VERSION ""

NS_ :

BS_:

BU_: ECM

BO_ 611 ORC_FD_1: 32 Vector__XXX
 SG_ MessageCounter_ORC1 : 179|4@0+ (1,0) [0|15] "-"  ECM
 SG_ CRC_ORC1 : 191|8@0+ (1,0) [0|255] "-"  ECM

BO_ 264 EPS_FD_1: 32 Vector__XXX
 SG_ LwsAngle : 7|16@0+ (0.1,-720) [-720|720] "°"  ECM

BO_ 518 ENGINE_FD_5: 32 ECM
 SG_ RPMOverRev_W : 115|1@0+ (1,0) [0|1] "-"  Vector__XXX
 SG_ PdlPosActual : 87|8@0+ (0.4,0) [0|100] "%"  Vector__XXX
 SG_ MessageCounter_ENGINE5 : 179|4@0+ (1,0) [0|15] "-"  Vector__XXX
 SG_ EngTrqEnblRq_DAS_W : 101|1@0+ (1,0) [0|1] "-"  Vector__XXX
 SG_ CRC_ENGINE5 : 191|8@0+ (1,0) [0|255] "-"  Vector__XXX

BO_ 1054 ENGINE_FD_1: 32 ECM
 SG_ ThermalManagementActive_W : 1|1@0+ (1,0) [0|1] "-"  Vector__XXX
 SG_ MessageCounter_ENGINE1 : 179|4@0+ (1,0) [0|15] "-"  Vector__XXX
 SG_ CRC_ENGINE1 : 191|8@0+ (1,0) [0|255] "-"  Vector__XXX

BO_ 514 BRAKE_FD_7: 32 Vector__XXX
 SG_ MessageCounter_BRAKE7 : 179|4@0+ (1,0) [0|15] "-"  ECM
 SG_ CRC_BRAKE7 : 191|8@0+ (1,0) [0|255] "-"  ECM
 SG_ BrkPdl_Stat : 85|2@0+ (1,0) [0|2] "-"  ECM
 SG_ BrkPdl_Flt : 86|1@0+ (1,0) [0|1] "-"  ECM
 SG_ BrakePdlPosn : 63|8@0+ (0.4,0) [0|100] "%"  ECM

BO_ 1155 BRAKE_FD_5: 32 Vector__XXX
 SG_ ACCEngaged : 92|1@0+ (1,0) [0|1] "-"  ECM
 SG_ ABSFailSts : 87|1@0+ (1,0) [0|1] "-"  ECM
 SG_ MessageCounter_BRAKE5 : 179|4@0+ (1,0) [0|15] "-"  ECM
 SG_ CRC_BRAKE5 : 191|8@0+ (1,0) [0|255] "-"  ECM

BO_ 513 BRAKE_FD_1: 32 Vector__XXX
 SG_ SelectSpdSts : 165|2@0+ (1,0) [0|2] "-"  ECM
 SG_ MessageCounter_BRAKE1 : 179|4@0+ (1,0) [0|15] "-"  ECM
 SG_ CRC_BRAKE1 : 191|8@0+ (1,0) [0|255] "-"  ECM

BO_ 255 PT_TORQUE_FD_1: 48 ECM
 SG_ SumTorqueStatic : 98|11@0+ (1,-500) [-500|1546] "Nm"  Vector__XXX
 SG_ SumTorqueSel_D_TTC : 82|11@0+ (1,-500) [-500|1546] "Nm"  Vector__XXX
 SG_ SumTorqueMin : 66|11@0+ (1,-500) [-500|1546] "Nm"  Vector__XXX
 SG_ SumTorqueMax : 50|11@0+ (1,-500) [-500|1546] "Nm"  Vector__XXX
 SG_ SumTorqueExp : 34|11@0+ (1,-500) [-500|1546] "Nm"  Vector__XXX
 SG_ SumTorque_DrvReqMod : 20|13@0+ (0.25,-500) [-500|1547.5] "Nm"  Vector__XXX
 SG_ MessageCounter_PT_TORQUE_FD_1 : 307|4@0+ (1,0) [0|15] "-"  Vector__XXX
 SG_ CRC_PT_TORQUE_FD_1 : 319|8@0+ (1,0) [0|255] "-"  Vector__XXX
 SG_ SSC_TrqEnblRq_Allowed : 22|1@0+ (1,0) [0|1] "-"  Vector__XXX
 SG_ ESC_TrqEnblRq_Allowed : 38|1@0+ (1,0) [0|1] "-"  Vector__XXX
 SG_ Accel_Pedal_Override : 37|1@0+ (1,0) [0|1] "-"  Vector__XXX
 SG_ ACC_NCC_TrqEnblRq_Allowed : 23|1@0+ (1,0) [0|1] "-"  Vector__XXX
 SG_ Total_AxleTorque_Static : 151|16@0+ (2,-65534) [-65534|65536] "Nm"  Vector__XXX
 SG_ Rear_AxleTorque_Static : 183|16@0+ (2,-65534) [-65534|65536] "Nm"  Vector__XXX
 SG_ Front_AxleTorque_Static : 167|16@0+ (2,-65534) [-65534|65536] "Nm"  Vector__XXX

BO_ 1036 ENGINE_FD_3: 32 ECM
 SG_ SpeedLimitSts : 159|3@0+ (1,0) [0|7] "-"  Vector__XXX
 SG_ Override : 163|1@0+ (1,0) [0|1] "-"  Vector__XXX
 SG_ MessageCounter_ENGINE3 : 179|4@0+ (1,0) [0|15] "-"  Vector__XXX
 SG_ ISASts : 167|1@0+ (1,0) [0|1] "-"  Vector__XXX
 SG_ CRC_ENGINE3 : 191|8@0+ (1,0) [0|255] "-"  Vector__XXX

BO_ 1456 ADAS_FD_HMI: 32 Vector__XXX
 SG_ MessageCounter_ADAS_FD_HMI : 179|4@0+ (1,0) [0|15] "-"  ECM
 SG_ CRC_ADAS_FD_HMI : 191|8@0+ (1,0) [0|255] "-"  ECM
 SG_ Set_Speed_MPH : 15|8@0+ (1,0) [0|255] "mph"  ECM
 SG_ Set_Speed_KPH : 7|8@0+ (1,0) [0|255] "kph"  ECM

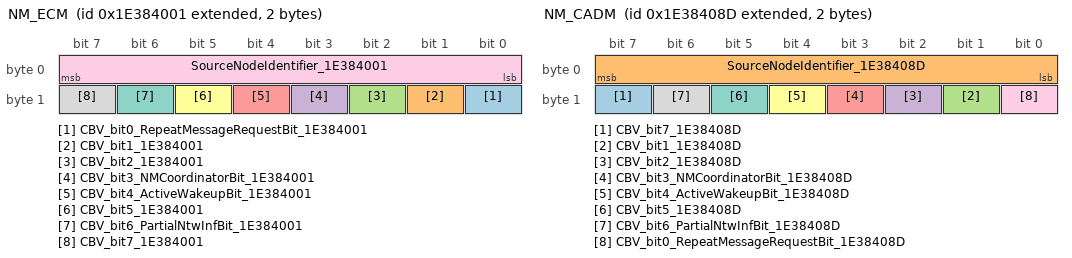
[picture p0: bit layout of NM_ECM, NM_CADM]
BO_ 2654486529 NM_ECM: 2 ECM
 SG_ CBV_bit0_RepeatMessageRequestBit_1E384001 : 8|1@0+ (1,0) [0|1] "" Vector__XXX
 SG_ CBV_bit1_1E384001 : 9|1@0+ (1,0) [0|1] "" Vector__XXX
 SG_ CBV_bit2_1E384001 : 10|1@0+ (1,0) [0|1] "" Vector__XXX
 SG_ CBV_bit3_NMCoordinatorBit_1E384001 : 11|1@0+ (1,0) [0|1] "" Vector__XXX
 SG_ CBV_bit4_ActiveWakeupBit_1E384001 : 12|1@0+ (1,0) [0|1] "" Vector__XXX
 SG_ CBV_bit5_1E384001 : 13|1@0+ (1,0) [0|1] "" Vector__XXX
 SG_ CBV_bit6_PartialNtwInfBit_1E384001 : 14|1@0+ (1,0) [0|1] "" Vector__XXX
 SG_ CBV_bit7_1E384001 : 15|1@0+ (1,0) [0|1] "" Vector__XXX
 SG_ SourceNodeIdentifier_1E384001 : 7|8@0+ (1,0) [0|255] "-"  Vector__XXX

BO_ 2654486669 NM_CADM: 2 Vector__XXX
 SG_ CBV_bit7_1E38408D : 15|1@0+ (1,0) [0|1] "" ECM
 SG_ SourceNodeIdentifier_1E38408D : 7|8@0+ (1,0) [0|255] "-"  ECM
 SG_ CBV_bit1_1E38408D : 9|1@0+ (1,0) [0|1] "" ECM
 SG_ CBV_bit2_1E38408D : 10|1@0+ (1,0) [0|1] "" ECM
 SG_ CBV_bit3_NMCoordinatorBit_1E38408D : 11|1@0+ (1,0) [0|1] "" ECM
 SG_ CBV_bit4_ActiveWakeupBit_1E38408D : 12|1@0+ (1,0) [0|1] "" ECM
 SG_ CBV_bit5_1E38408D : 13|1@0+ (1,0) [0|1] "" ECM
 SG_ CBV_bit6_PartialNtwInfBit_1E38408D : 14|1@0+ (1,0) [0|1] "" ECM
 SG_ CBV_bit0_RepeatMessageRequestBit_1E38408D : 8|1@0+ (1,0) [0|1] "" ECM

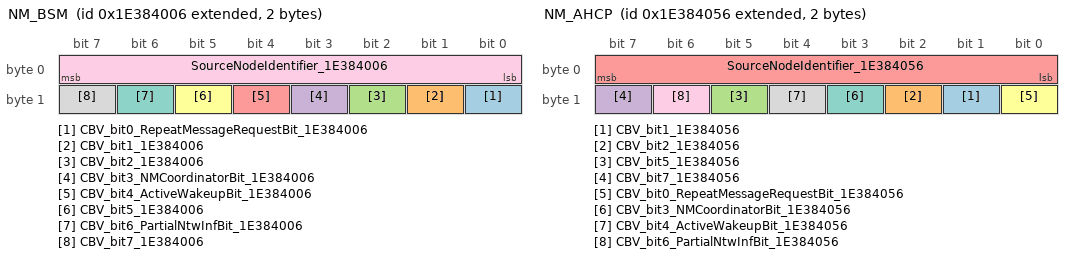
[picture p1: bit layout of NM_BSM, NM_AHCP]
BO_ 2654486534 NM_BSM: 2 Vector__XXX
 SG_ CBV_bit0_RepeatMessageRequestBit_1E384006 : 8|1@0+ (1,0) [0|1] "" ECM
 SG_ CBV_bit1_1E384006 : 9|1@0+ (1,0) [0|1] "" ECM
 SG_ CBV_bit2_1E384006 : 10|1@0+ (1,0) [0|1] "" ECM
 SG_ CBV_bit3_NMCoordinatorBit_1E384006 : 11|1@0+ (1,0) [0|1] "" ECM
 SG_ CBV_bit4_ActiveWakeupBit_1E384006 : 12|1@0+ (1,0) [0|1] "" ECM
 SG_ CBV_bit5_1E384006 : 13|1@0+ (1,0) [0|1] "" ECM
 SG_ CBV_bit6_PartialNtwInfBit_1E384006 : 14|1@0+ (1,0) [0|1] "" ECM
 SG_ CBV_bit7_1E384006 : 15|1@0+ (1,0) [0|1] "" ECM
 SG_ SourceNodeIdentifier_1E384006 : 7|8@0+ (1,0) [0|255] "-"  ECM

BO_ 276 HYBRID_POWERTRAIN1: 64 Vector__XXX
 SG_ PropulsionSystemActive : 408|1@0+ (1,0) [0|1] "-"  ECM

BO_ 262 ENGINE_FD_2: 64 ECM
 SG_ PowertrainPrplsnActv : 181|1@0+ (1,0) [0|1] "" Vector__XXX
 SG_ MessageCounter_ENGINE2 : 435|4@0+ (1,0) [0|15] "-"  Vector__XXX
 SG_ LV12PwrFreeRq_W : 176|1@0+ (1,0) [0|1] "-"  Vector__XXX
 SG_ GasPedalPositionFailSts_W : 169|1@0+ (1,0) [0|1] "-"  Vector__XXX
 SG_ GasPedalPosition_W : 143|8@0+ (0.392,0) [0|99.568] "%"  Vector__XXX
 SG_ FeedbackASR_ESCReq_W : 186|1@0+ (1,0) [0|1] "-"  Vector__XXX
 SG_ ESS_ENG_ST_W : 175|4@0+ (1,0) [0|15] "-"  Vector__XXX
 SG_ EngineSts_W : 87|2@0+ (1,0) [0|3] "-"  Vector__XXX
 SG_ EngineSpeed_W : 21|14@0+ (1,0) [0|16382] "1/min"  Vector__XXX
 SG_ ECM_LHOM_W : 188|1@0+ (1,0) [0|1] "-"  Vector__XXX
 SG_ CRC_ENGINE2 : 447|8@0+ (1,0) [0|255] "-"  Vector__XXX

BO_ 258 BRAKE_FD_2: 64 Vector__XXX
 SG_ TorqueRequest : 98|11@0+ (1,-500) [-500|1546] "-"  ECM
 SG_ TorqueReduct : 158|1@0+ (1,0) [0|1] "-"  ECM
 SG_ TorqueIncrease : 175|1@0+ (1,0) [0|1] "-"  ECM
 SG_ MessageCounter_BRAKE2 : 435|4@0+ (1,0) [0|15] "-"  ECM
 SG_ CRC_BRAKE2 : 447|8@0+ (1,0) [0|255] "-"  ECM
 SG_ BrakePedalPressure : 386|11@0+ (0.1,0) [0|200] "bar"  ECM
 SG_ BrakeBoostPressure : 370|11@0+ (0.1,0) [0|200] "bar"  ECM
 SG_ ABSActive : 83|1@0+ (1,0) [0|1] "-"  ECM
 SG_ Brk_Stat : 343|2@0+ (1,0) [0|2] "-"  ECM
 SG_ ACC_Wheel_Torque_Enabled_BSM : 85|1@0+ (1,0) [0|1] "-"  ECM
 SG_ ACC_Wheel_Torque_BSM : 423|16@0+ (2,-36878) [-36878|94190] "-"  ECM

BO_ 2654486614 NM_AHCP: 2 Vector__XXX
 SG_ CBV_bit1_1E384056 : 9|1@0+ (1,0) [0|1] "" ECM
 SG_ CBV_bit2_1E384056 : 10|1@0+ (1,0) [0|1] "" ECM
 SG_ CBV_bit5_1E384056 : 13|1@0+ (1,0) [0|1] "" ECM
 SG_ CBV_bit7_1E384056 : 15|1@0+ (1,0) [0|1] "" ECM
 SG_ SourceNodeIdentifier_1E384056 : 7|8@0+ (1,0) [0|255] "-"  ECM
 SG_ CBV_bit0_RepeatMessageRequestBit_1E384056 : 8|1@0+ (1,0) [0|1] "" ECM
 SG_ CBV_bit3_NMCoordinatorBit_1E384056 : 11|1@0+ (1,0) [0|1] "" ECM
 SG_ CBV_bit4_ActiveWakeupBit_1E384056 : 12|1@0+ (1,0) [0|1] "" ECM
 SG_ CBV_bit6_PartialNtwInfBit_1E384056 : 14|1@0+ (1,0) [0|1] "" ECM

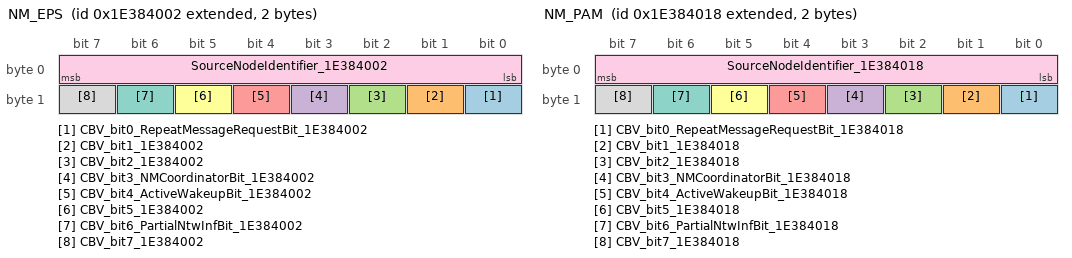
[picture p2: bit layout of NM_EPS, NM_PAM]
BO_ 2654486530 NM_EPS: 2 Vector__XXX
 SG_ CBV_bit0_RepeatMessageRequestBit_1E384002 : 8|1@0+ (1,0) [0|1] "" ECM
 SG_ CBV_bit1_1E384002 : 9|1@0+ (1,0) [0|1] "" ECM
 SG_ CBV_bit2_1E384002 : 10|1@0+ (1,0) [0|1] "" ECM
 SG_ CBV_bit3_NMCoordinatorBit_1E384002 : 11|1@0+ (1,0) [0|1] "" ECM
 SG_ CBV_bit4_ActiveWakeupBit_1E384002 : 12|1@0+ (1,0) [0|1] "" ECM
 SG_ CBV_bit5_1E384002 : 13|1@0+ (1,0) [0|1] "" ECM
 SG_ CBV_bit6_PartialNtwInfBit_1E384002 : 14|1@0+ (1,0) [0|1] "" ECM
 SG_ CBV_bit7_1E384002 : 15|1@0+ (1,0) [0|1] "" ECM
 SG_ SourceNodeIdentifier_1E384002 : 7|8@0+ (1,0) [0|255] "-"  ECM

BO_ 2654486552 NM_PAM: 2 Vector__XXX
 SG_ CBV_bit0_RepeatMessageRequestBit_1E384018 : 8|1@0+ (1,0) [0|1] "" ECM
 SG_ CBV_bit1_1E384018 : 9|1@0+ (1,0) [0|1] "" ECM
 SG_ CBV_bit2_1E384018 : 10|1@0+ (1,0) [0|1] "" ECM
 SG_ CBV_bit3_NMCoordinatorBit_1E384018 : 11|1@0+ (1,0) [0|1] "" ECM
 SG_ CBV_bit4_ActiveWakeupBit_1E384018 : 12|1@0+ (1,0) [0|1] "" ECM
 SG_ CBV_bit5_1E384018 : 13|1@0+ (1,0) [0|1] "" ECM
 SG_ CBV_bit6_PartialNtwInfBit_1E384018 : 14|1@0+ (1,0) [0|1] "" ECM
 SG_ CBV_bit7_1E384018 : 15|1@0+ (1,0) [0|1] "" ECM
 SG_ SourceNodeIdentifier_1E384018 : 7|8@0+ (1,0) [0|255] "-"  ECM

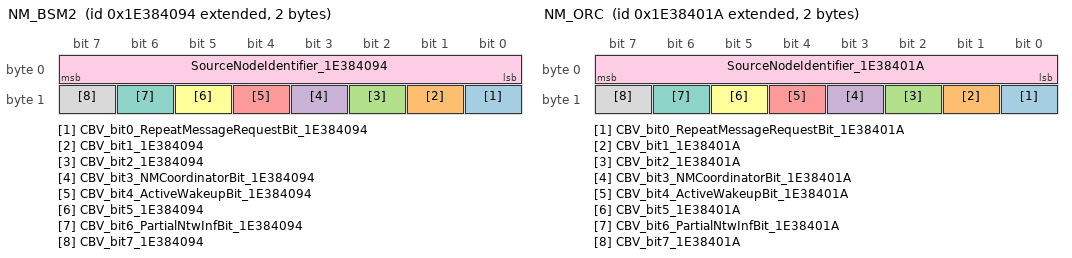
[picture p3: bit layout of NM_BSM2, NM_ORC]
BO_ 2654486676 NM_BSM2: 2 Vector__XXX
 SG_ CBV_bit0_RepeatMessageRequestBit_1E384094 : 8|1@0+ (1,0) [0|1] "" ECM
 SG_ CBV_bit1_1E384094 : 9|1@0+ (1,0) [0|1] "" ECM
 SG_ CBV_bit2_1E384094 : 10|1@0+ (1,0) [0|1] "" ECM
 SG_ CBV_bit3_NMCoordinatorBit_1E384094 : 11|1@0+ (1,0) [0|1] "" ECM
 SG_ CBV_bit4_ActiveWakeupBit_1E384094 : 12|1@0+ (1,0) [0|1] "" ECM
 SG_ CBV_bit5_1E384094 : 13|1@0+ (1,0) [0|1] "" ECM
 SG_ CBV_bit6_PartialNtwInfBit_1E384094 : 14|1@0+ (1,0) [0|1] "" ECM
 SG_ CBV_bit7_1E384094 : 15|1@0+ (1,0) [0|1] "" ECM
 SG_ SourceNodeIdentifier_1E384094 : 7|8@0+ (1,0) [0|255] "-"  ECM

BO_ 280 ADAS_FD_INFO: 32 Vector__XXX
 SG_ Object_Dist : 127|8@0+ (1,0) [0|255] "m"  ECM
 SG_ MessageCounter_ADAS_FD_INFO : 179|4@0+ (1,0) [0|15] "-"  ECM
 SG_ CRC_ADAS_FD_INFO : 191|8@0+ (1,0) [0|255] "-"  ECM
 SG_ ACC_DsrSpeedKPH : 119|8@0+ (1,0) [0|255] "km/h"  ECM
 SG_ MRM_STATUS : 23|3@0+ (1,0) [0|6] "" ECM
 SG_ ACC_Systemsts : 183|4@0+ (1,0) [0|14] "-"  ECM
 SG_ ACC_StopStart : 97|2@0+ (1,0) [0|2] "-"  ECM

BO_ 2654486554 NM_ORC: 2 Vector__XXX
 SG_ CBV_bit0_RepeatMessageRequestBit_1E38401A : 8|1@0+ (1,0) [0|1] "" ECM
 SG_ CBV_bit1_1E38401A : 9|1@0+ (1,0) [0|1] "" ECM
 SG_ CBV_bit2_1E38401A : 10|1@0+ (1,0) [0|1] "" ECM
 SG_ CBV_bit3_NMCoordinatorBit_1E38401A : 11|1@0+ (1,0) [0|1] "" ECM
 SG_ CBV_bit4_ActiveWakeupBit_1E38401A : 12|1@0+ (1,0) [0|1] "" ECM
 SG_ CBV_bit5_1E38401A : 13|1@0+ (1,0) [0|1] "" ECM
 SG_ CBV_bit6_PartialNtwInfBit_1E38401A : 14|1@0+ (1,0) [0|1] "" ECM
 SG_ CBV_bit7_1E38401A : 15|1@0+ (1,0) [0|1] "" ECM
 SG_ SourceNodeIdentifier_1E38401A : 7|8@0+ (1,0) [0|255] "-"  ECM

BO_ 205 BRAKE_FD_6: 64 Vector__XXX
 SG_ CRC_BRAKE_FD_6 : 447|8@0+ (1,0) [0|255] "-"  ECM
 SG_ MessageCounter_BRAKE_FD_6 : 435|4@0+ (1,0) [0|15] "-"  ECM
 SG_ TotalAxle_Min_Rq_BSM : 50|1@0+ (1,0) [0|1] "" ECM
 SG_ TotalAxle_Max_Rq_BSM : 51|1@0+ (1,0) [0|1] "" ECM
 SG_ DriverReq_AxleTrq_Enabled_BSM : 175|4@0+ (1,0) [0|15] "" ECM
 SG_ TotalAxle_Rq_BSM : 95|16@0+ (2,-65534) [-65534|65536] "Nm"  ECM
 SG_ DriverRequested_AxleTrq_BSM : 159|16@0+ (2,-65534) [-65534|65536] "Nm"  ECM

BO_ 204 AXLE_TORQUE_FD_1: 48 ECM
 SG_ MessageCounter_AXLE_TORQUE_FD_1 : 307|4@0+ (1,0) [0|15] "-"  Vector__XXX
 SG_ CRC_AXLE_TORQUE_FD_1 : 319|8@0+ (1,0) [0|255] "-"  Vector__XXX
 SG_ Rear_Axle_Regen_Capacity : 197|14@0+ (2,0) [0|32764] "Nm"  Vector__XXX
 SG_ Rear_Axle_Est_Regen_Torq : 181|14@0+ (2,0) [0|32764] "Nm"  Vector__XXX
 SG_ Front_Axle_Regen_Capacity : 165|14@0+ (2,0) [0|32764] "Nm"  Vector__XXX
 SG_ Front_Axle_Est_Regen_Torq : 149|14@0+ (2,0) [0|32764] "Nm"  Vector__XXX
 SG_ Total_AxleTorque_Min : 23|16@0+ (2,-65534) [-65534|65536] "Nm"  Vector__XXX
 SG_ Total_AxleTorque_Max : 7|16@0+ (2,-65534) [-65534|65536] "Nm"  Vector__XXX
 SG_ Axle_TorqueStatic_D_TTC : 39|16@0+ (2,-65534) [-65534|65536] "Nm"  Vector__XXX
 SG_ Axle_Torque_DrvReqMod : 55|16@0+ (2,-65534) [-65534|65536] "Nm"  Vector__XXX
 SG_ Rear_AxleTorque_Min : 119|16@0+ (2,-65534) [-65534|65536] "Nm"  Vector__XXX
 SG_ Rear_AxleTorque_Max : 103|16@0+ (2,-65534) [-65534|65536] "Nm"  Vector__XXX
 SG_ Front_AxleTorque_Min : 87|16@0+ (2,-65534) [-65534|65536] "Nm"  Vector__XXX
 SG_ Front_AxleTorque_Max : 71|16@0+ (2,-65534) [-65534|65536] "Nm"  Vector__XXX

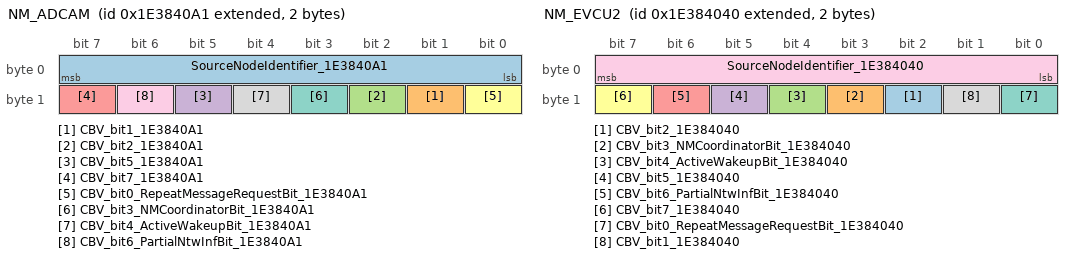
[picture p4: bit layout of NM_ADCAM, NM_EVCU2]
BO_ 2654486689 NM_ADCAM: 2 Vector__XXX
 SG_ SourceNodeIdentifier_1E3840A1 : 7|8@0+ (1,0) [0|255] "-"  ECM
 SG_ CBV_bit1_1E3840A1 : 9|1@0+ (1,0) [0|1] "" ECM
 SG_ CBV_bit2_1E3840A1 : 10|1@0+ (1,0) [0|1] "" ECM
 SG_ CBV_bit5_1E3840A1 : 13|1@0+ (1,0) [0|1] "" ECM
 SG_ CBV_bit7_1E3840A1 : 15|1@0+ (1,0) [0|1] "" ECM
 SG_ CBV_bit0_RepeatMessageRequestBit_1E3840A1 : 8|1@0+ (1,0) [0|1] "-"  ECM
 SG_ CBV_bit3_NMCoordinatorBit_1E3840A1 : 11|1@0+ (1,0) [0|1] "-"  ECM
 SG_ CBV_bit4_ActiveWakeupBit_1E3840A1 : 12|1@0+ (1,0) [0|1] "-"  ECM
 SG_ CBV_bit6_PartialNtwInfBit_1E3840A1 : 14|1@0+ (1,0) [0|1] "-"  ECM

BO_ 263 PT_SYSTEM_FD_1: 64 Vector__XXX
 SG_ MessageCounter_PT_SYSTEM_FD_1 : 435|4@0+ (1,0) [0|15] "-"  ECM
 SG_ CRC_PT_SYSTEM_FD_1 : 447|8@0+ (1,0) [0|255] "-"  ECM

BO_ 2654486592 NM_EVCU2: 2 Vector__XXX
 SG_ CBV_bit2_1E384040 : 10|1@0+ (1,0) [0|1] "" ECM
 SG_ CBV_bit3_NMCoordinatorBit_1E384040 : 11|1@0+ (1,0) [0|1] "" ECM
 SG_ CBV_bit4_ActiveWakeupBit_1E384040 : 12|1@0+ (1,0) [0|1] "" ECM
 SG_ CBV_bit5_1E384040 : 13|1@0+ (1,0) [0|1] "" ECM
 SG_ CBV_bit6_PartialNtwInfBit_1E384040 : 14|1@0+ (1,0) [0|1] "" ECM
 SG_ CBV_bit7_1E384040 : 15|1@0+ (1,0) [0|1] "" ECM
 SG_ CBV_bit0_RepeatMessageRequestBit_1E384040 : 8|1@0+ (1,0) [0|1] "" ECM
 SG_ CBV_bit1_1E384040 : 9|1@0+ (1,0) [0|1] "" ECM
 SG_ SourceNodeIdentifier_1E384040 : 7|8@0+ (1,0) [0|255] "-"  ECM

CM_ "Project_WL25_ProjectStandard_FD-CAN14 [CS00155_FD]";
CM_ SG_ 263 CRC_PT_SYSTEM_FD_1 "CRC according to SAE J1850 standard at each frame transmission.";
CM_ SG_ 263 MessageCounter_PT_SYSTEM_FD_1 "This signal is a counter used for safety checks strategies. This counter is incremented of 1 (one) unit at each frame transmission.";
CM_ SG_ 2654486689 CBV_bit0_RepeatMessageRequestBit_1E3840A1 "Repeat Message Request Bit";
CM_ SG_ 2654486689 CBV_bit3_NMCoordinatorBit_1E3840A1 "NM Coordinator Sleep Bit";
CM_ SG_ 2654486689 CBV_bit4_ActiveWakeupBit_1E3840A1 "Active Wakeup Bit";
CM_ SG_ 2654486689 CBV_bit6_PartialNtwInfBit_1E3840A1 "Partial Network Information Bit (PNI)";
CM_ SG_ 2654486689 SourceNodeIdentifier_1E3840A1 "Source Node Identifier";
CM_ SG_ 264 LwsAngle "This signal indicates the steering angle value, counterclockwise positive.";
CM_ SG_ 611 CRC_ORC1 "CRC according to SAE J1850 standard at each frame transmission.";
CM_ SG_ 611 MessageCounter_ORC1 "This signal is a counter used for safety checks strategies. This counter is incremented of 1 (one) unit at each frame transmission.";
CM_ SG_ 205 DriverRequested_AxleTrq_BSM "Virtual driver torque request from BSM";
CM_ SG_ 205 TotalAxle_Rq_BSM "Combined axle traction torque request";
CM_ SG_ 205 DriverReq_AxleTrq_Enabled_BSM "It indicates the request to enable virtual driver torque interface for BSM driver functions";
CM_ SG_ 205 TotalAxle_Max_Rq_BSM "Combined axle traction torque max limit flag. Active = [1]";
CM_ SG_ 205 TotalAxle_Min_Rq_BSM "Combined axle traction torque min limit flag. Active = [1]";
CM_ SG_ 205 MessageCounter_BRAKE_FD_6 "This signal is a counter used for safety checks strategies. This counter is incremented of 1 (one) unit at each frame transmission.";
CM_ SG_ 205 CRC_BRAKE_FD_6 "CRC according to SAE J1850 standard at each frame transmission.";
CM_ SG_ 2654486554 CBV_bit0_RepeatMessageRequestBit_1E38401A "Repeat Message Request Bit";
CM_ SG_ 2654486554 CBV_bit3_NMCoordinatorBit_1E38401A "NM Coordinator Sleep Bit";
CM_ SG_ 2654486554 CBV_bit4_ActiveWakeupBit_1E38401A "Active Wakeup Bit";
CM_ SG_ 2654486554 CBV_bit6_PartialNtwInfBit_1E38401A "Partial Network Information Bit (PNI)";
CM_ SG_ 2654486554 SourceNodeIdentifier_1E38401A "Source Node Identifier";
CM_ SG_ 280 Object_Dist "It indicates the distance to the recognized object";
CM_ SG_ 280 ACC_DsrSpeedKPH "Desired speed in kilometers per hour";
CM_ SG_ 280 ACC_StopStart "Allows StopStart when ACC is engaged";
CM_ SG_ 280 ACC_Systemsts "ACC System Status";
CM_ SG_ 280 MRM_STATUS "Status of the minimum risk maneuver to handle system faults or driver abuse as understood by primary controller";
CM_ SG_ 280 CRC_ADAS_FD_INFO "CRC according to SAE J1850 standard at each frame transmission.";
CM_ SG_ 280 MessageCounter_ADAS_FD_INFO "This signal is a counter used for safety checks strategies. This counter is incremented of 1 (one) unit at each frame transmission.";
CM_ SG_ 2654486676 CBV_bit0_RepeatMessageRequestBit_1E384094 "Repeat Message Request Bit";
CM_ SG_ 2654486676 CBV_bit3_NMCoordinatorBit_1E384094 "NM Coordinator Sleep Bit";
CM_ SG_ 2654486676 CBV_bit4_ActiveWakeupBit_1E384094 "Active Wakeup Bit";
CM_ SG_ 2654486676 CBV_bit6_PartialNtwInfBit_1E384094 "Partial Network Information Bit (PNI)";
CM_ SG_ 2654486676 SourceNodeIdentifier_1E384094 "Source Node Identifier";
CM_ SG_ 2654486552 CBV_bit0_RepeatMessageRequestBit_1E384018 "Repeat Message Request Bit";
CM_ SG_ 2654486552 CBV_bit3_NMCoordinatorBit_1E384018 "NM Coordinator Sleep Bit";
CM_ SG_ 2654486552 CBV_bit4_ActiveWakeupBit_1E384018 "Active Wakeup Bit";
CM_ SG_ 2654486552 CBV_bit6_PartialNtwInfBit_1E384018 "Partial Network Information Bit (PNI)";
CM_ SG_ 2654486552 SourceNodeIdentifier_1E384018 "Source Node Identifier";
CM_ SG_ 2654486530 CBV_bit0_RepeatMessageRequestBit_1E384002 "Repeat Message Request Bit";
CM_ SG_ 2654486530 CBV_bit3_NMCoordinatorBit_1E384002 "NM Coordinator Sleep Bit";
CM_ SG_ 2654486530 CBV_bit4_ActiveWakeupBit_1E384002 "Active Wakeup Bit";
CM_ SG_ 2654486530 CBV_bit6_PartialNtwInfBit_1E384002 "Partial Network Information Bit (PNI)";
CM_ SG_ 2654486530 SourceNodeIdentifier_1E384002 "Source Node Identifier";
CM_ SG_ 2654486614 CBV_bit0_RepeatMessageRequestBit_1E384056 "Repeat Message Request Bit";
CM_ SG_ 2654486614 CBV_bit3_NMCoordinatorBit_1E384056 "NM Coordinator Sleep Bit";
CM_ SG_ 2654486614 CBV_bit4_ActiveWakeupBit_1E384056 "Active Wakeup Bit";
CM_ SG_ 2654486614 CBV_bit6_PartialNtwInfBit_1E384056 "Partial Network Information Bit (PNI)";
CM_ SG_ 2654486614 SourceNodeIdentifier_1E384056 "Source Node Identifier";
CM_ SG_ 258 BrakePedalPressure "Pressure Information from Brake Pedal Simulator Pressure Sensor";
CM_ SG_ 258 BrakeBoostPressure "Pressure Information from Brake Booster Pressure Sensor";
CM_ SG_ 258 ACC_Wheel_Torque_BSM "It indicates the requested wheel torque value of ACC function";
CM_ SG_ 258 ACC_Wheel_Torque_Enabled_BSM "It indicates the request to enable torque interface of ACC function";
CM_ SG_ 258 Brk_Stat "Brake state";
CM_ SG_ 258 ABSActive "This signal is set to Active when the ABS functionality is active.";
CM_ SG_ 258 CRC_BRAKE2 "CRC according to SAE J1850 standard at each frame transmission.";
CM_ SG_ 258 MessageCounter_BRAKE2 "This signal is a counter used for safety checks strategies. This counter is incremented of 1 (one) unit at each frame transmission.";
CM_ SG_ 258 TorqueIncrease "0";
CM_ SG_ 258 TorqueReduct "0";
CM_ SG_ 258 TorqueRequest "[NOTE FOR MASERATI PROGRAMS ONLY] ICE & MHEV BSG: signal is referred to flywheel torque - Unit: Nm; MHEV P1R & BEV: signal is referred to wheel torque - Unit: daNm";
CM_ SG_ 276 PropulsionSystemActive "Propulsion system active, [1] = active";
CM_ SG_ 2654486534 CBV_bit0_RepeatMessageRequestBit_1E384006 "Repeat Message Request Bit";
CM_ SG_ 2654486534 CBV_bit3_NMCoordinatorBit_1E384006 "NM Coordinator Sleep Bit";
CM_ SG_ 2654486534 CBV_bit4_ActiveWakeupBit_1E384006 "Active Wakeup Bit";
CM_ SG_ 2654486534 CBV_bit6_PartialNtwInfBit_1E384006 "Partial Network Information Bit (PNI)";
CM_ SG_ 2654486534 SourceNodeIdentifier_1E384006 "Source Node Identifier";
CM_ SG_ 2654486669 CBV_bit0_RepeatMessageRequestBit_1E38408D "Repeat Message Request Bit";
CM_ SG_ 2654486669 CBV_bit3_NMCoordinatorBit_1E38408D "NM Coordinator Sleep Bit";
CM_ SG_ 2654486669 CBV_bit4_ActiveWakeupBit_1E38408D "Active Wakeup Bit";
CM_ SG_ 2654486669 CBV_bit6_PartialNtwInfBit_1E38408D "Partial Network Information Bit (PNI)";
CM_ SG_ 2654486669 SourceNodeIdentifier_1E38408D "Source Node Identifier";
CM_ SG_ 1456 Set_Speed_KPH "Speed shown by IPC, which ACC is controlling in KPH";
CM_ SG_ 1456 Set_Speed_MPH "Speed shown by IPC, which ACC is controlling in MPH";
CM_ SG_ 1456 CRC_ADAS_FD_HMI "CRC according to SAE J1850 standard at each frame transmission.";
CM_ SG_ 1456 MessageCounter_ADAS_FD_HMI "This signal is a counter used for safety checks strategies. This counter is incremented of 1 (one) unit at each frame transmission.";
CM_ SG_ 513 CRC_BRAKE1 "CRC according to SAE J1850 standard at each frame transmission.";
CM_ SG_ 513 MessageCounter_BRAKE1 "This signal is a counter used for safety checks strategies. This counter is incremented of 1 (one) unit at each frame transmission.";
CM_ SG_ 513 SelectSpdSts "0";
CM_ SG_ 1155 CRC_BRAKE5 "CRC according to SAE J1850 standard at each frame transmission.";
CM_ SG_ 1155 MessageCounter_BRAKE5 "This signal is a counter used for safety checks strategies. This counter is incremented of 1 (one) unit at each frame transmission.";
CM_ SG_ 1155 ABSFailSts "0";
CM_ SG_ 1155 ACCEngaged "ACC is engaged";
CM_ SG_ 514 CRC_BRAKE7 "CRC according to SAE J1850 standard at each frame transmission.";
CM_ SG_ 514 MessageCounter_BRAKE7 "This signal is a counter used for safety checks strategies. This counter is incremented of 1 (one) unit at each frame transmission.";
CM_ SG_ 514 BrkPdl_Flt "Brake Pedal Fault is active, 1=Faulted";
CM_ SG_ 514 BrakePdlPosn "Brake pedal travel sensor 0-100% (0 = upstop)";
CM_ SG_ 514 BrkPdl_Stat "Brake pedal state";
CM_ SG_ 204 Rear_Axle_Regen_Capacity "Regenerative Braking rear Axle Torque Capability";
CM_ SG_ 204 Rear_Axle_Est_Regen_Torq "Estimated regen Braking Torque at the Rear axle";
CM_ SG_ 204 Front_Axle_Regen_Capacity "Regenerative Braking front Axle Torque Capability";
CM_ SG_ 204 Front_Axle_Est_Regen_Torq "Estimated regen Braking Torque at the Front axle";
CM_ SG_ 204 Rear_AxleTorque_Min "Minimum rear Axle torque";
CM_ SG_ 204 Rear_AxleTorque_Max "Maximum rear Axle torque";
CM_ SG_ 204 Front_AxleTorque_Min "Minimum front Axle torque";
CM_ SG_ 204 Front_AxleTorque_Max "Maximum front Axle torque";
CM_ SG_ 204 Axle_Torque_DrvReqMod "Driver requested Axle torque raw (no torque shaping)";
CM_ SG_ 204 Axle_TorqueStatic_D_TTC "Driver requested Axle torque (filtered/ torque shaped)";
CM_ SG_ 204 Total_AxleTorque_Max "Maximum total Axle torque";
CM_ SG_ 204 Total_AxleTorque_Min "Minimum total Axle torque";
CM_ SG_ 204 CRC_AXLE_TORQUE_FD_1 "CRC according to SAE J1850 standard at each frame transmission.";
CM_ SG_ 204 MessageCounter_AXLE_TORQUE_FD_1 "This signal is a counter used for safety checks strategies. This counter is incremented of 1 (one) unit at each frame transmission.";
CM_ SG_ 262 CRC_ENGINE2 "CRC according to SAE J1850 standard at each frame transmission.";
CM_ SG_ 262 ECM_LHOM_W "-";
CM_ SG_ 262 EngineSpeed_W "It gives information on C-CAN network about  engine speed";
CM_ SG_ 262 EngineSts_W "-";
CM_ SG_ 262 ESS_ENG_ST_W "ESS Engine State";
CM_ SG_ 262 FeedbackASR_ESCReq_W "It is set to Not Valid, when the plausibility conditions about ASR / ESC torque request are not fulfilled . Nevertheless, it shall not be set to Not Valid, due to ValidData bits Not Valid transmitted from BSM.";
CM_ SG_ 262 GasPedalPosition_W "-";
CM_ SG_ 262 GasPedalPositionFailSts_W "-";
CM_ SG_ 262 LV12PwrFreeRq_W "-";
CM_ SG_ 262 MessageCounter_ENGINE2 "This signal is a counter used for safety checks strategies. This counter is incremented of 1 (one) unit at each frame transmission.";
CM_ SG_ 262 PowertrainPrplsnActv "Powertrain Propulsion Status.";
CM_ SG_ 2654486529 CBV_bit0_RepeatMessageRequestBit_1E384001 "Repeat Message Request Bit";
CM_ SG_ 2654486529 CBV_bit3_NMCoordinatorBit_1E384001 "NM Coordinator Sleep Bit";
CM_ SG_ 2654486529 CBV_bit4_ActiveWakeupBit_1E384001 "Active Wakeup Bit";
CM_ SG_ 2654486529 CBV_bit6_PartialNtwInfBit_1E384001 "Partial Network Information Bit (PNI)";
CM_ SG_ 2654486529 SourceNodeIdentifier_1E384001 "Source Node Identifier";
CM_ SG_ 1036 CRC_ENGINE3 "CRC according to SAE J1850 standard at each frame transmission.";
CM_ SG_ 1036 ISASts "This signal will be used to indicate when the Intelligent Speed Assist is Active";
CM_ SG_ 1036 MessageCounter_ENGINE3 "This signal is a counter used for safety checks strategies. This counter is incremented of 1 (one) unit at each frame transmission.";
CM_ SG_ 1036 Override "-";
CM_ SG_ 1036 SpeedLimitSts "It represents on C-CAN the actual status of speed limiter control function.";
CM_ SG_ 255 Rear_AxleTorque_Static "Static Rear Axle Torque";
CM_ SG_ 255 Front_AxleTorque_Static "Static Front Axle Torqu";
CM_ SG_ 255 ACC_NCC_TrqEnblRq_Allowed "ACC/NCC Torque request allowed. True =[1]";
CM_ SG_ 255 Accel_Pedal_Override "Driver Accelerator Pedal Override. True =[1]";
CM_ SG_ 255 ESC_TrqEnblRq_Allowed "ESC Torque request allowed. True =[1]";
CM_ SG_ 255 SSC_TrqEnblRq_Allowed "SCC Torque request allowed. True =[1]";
CM_ SG_ 255 CRC_PT_TORQUE_FD_1 "CRC according to SAE J1850 standard at each frame transmission.";
CM_ SG_ 255 MessageCounter_PT_TORQUE_FD_1 "This signal is a counter used for safety checks strategies. This counter is incremented of 1 (one) unit at each frame transmission.";
CM_ SG_ 255 Total_AxleTorque_Static "Static Axle Torque (effective total Axle torque)";
CM_ SG_ 255 SumTorque_DrvReqMod "Driver requested sum torque modified";
CM_ SG_ 255 SumTorqueExp "Expected sum torque based on target transmission input speed";
CM_ SG_ 255 SumTorqueMax "Maximum sum torque";
CM_ SG_ 255 SumTorqueMin "Minimum sum torque";
CM_ SG_ 255 SumTorqueSel_D_TTC "Corrected (substitute) driver torque demand";
CM_ SG_ 255 SumTorqueStatic "Static sum torque (effective sum torque)";
CM_ SG_ 1054 CRC_ENGINE1 "CRC according to SAE J1850 standard at each frame transmission.";
CM_ SG_ 1054 MessageCounter_ENGINE1 "This signal is a counter used for safety checks strategies. This counter is incremented of 1 (one) unit at each frame transmission.";
CM_ SG_ 1054 ThermalManagementActive_W "-";
CM_ SG_ 518 CRC_ENGINE5 "CRC according to SAE J1850 standard at each frame transmission.";
CM_ SG_ 518 EngTrqEnblRq_DAS_W "-";
CM_ SG_ 518 MessageCounter_ENGINE5 "This signal is a counter used for safety checks strategies. This counter is incremented of 1 (one) unit at each frame transmission.";
CM_ SG_ 518 PdlPosActual "Actual pedal position.";
CM_ SG_ 518 RPMOverRev_W "-";
BA_DEF_ SG_ "GenSigTimeoutTime_ADCAM" INT 0 65535;
BA_DEF_ SG_ "GenSigTimeoutTime_CVADAS" INT 0 65535;
BA_DEF_ SG_ "GenSigTimeoutTime_EVCU2" INT 0 65535;
BA_DEF_ SG_ "GenSigTimeoutTime_VDCM" INT 0 65535;
BA_DEF_ SG_ "GenSigStartValue" INT 0 2147483647;
BA_DEF_ SG_ "GenSigInactiveValue" INT 0 2147483647;
BA_DEF_ SG_ "GenSigSendType" ENUM "NotUsed","OnWrite","OnWriteWithRepetition","OnChange","OnChangeWithRepetition","IfActive","IfActiveWithRepetition","NoSigSendType";
BA_DEF_ SG_ "GenSigTimeoutTime_AHCP" INT 0 65535;
BA_DEF_ SG_ "GenSigTimeoutTime_BSM" INT 0 65535;
BA_DEF_ SG_ "GenSigTimeoutTime_BSM2" INT 0 65535;
BA_DEF_ SG_ "GenSigTimeoutTime_CADM" INT 0 65535;
BA_DEF_ SG_ "GenSigTimeoutTime_CVPAM" INT 0 65535;
BA_DEF_ SG_ "GenSigTimeoutTime_ECM" INT 0 65535;
BA_DEF_ SG_ "GenSigTimeoutTime_EPS" INT 0 65535;
BA_DEF_ SG_ "GenSigTimeoutTime_ORC" INT 0 65535;
BA_DEF_ BO_ "DiagRequest" ENUM "No","Yes";
BA_DEF_ BO_ "Type" ENUM "P","C","PE","COC","PE_Cntrl","E","E_Cntrl","OC","S","BAF","DC","EM","MM","ISO-TP","-";
BA_DEF_ BO_ "DiagResponse" ENUM "No","Yes";
BA_DEF_ BO_ "NmMessage" ENUM "No","Yes";
BA_DEF_ BO_ "GenMsgSendType" ENUM "Cyclic","NotUsed","NotUsed","NotUsed","NotUsed","NotUsed","NotUsed","NotUsed","NoMsgSendType";
BA_DEF_ BO_ "GenMsgNrOfRepetition" INT 0 255;
BA_DEF_ BO_ "GenMsgILSupport" ENUM "No","Yes";
BA_DEF_ BO_ "GenMsgCycleTimeFast" INT 0 65535;
BA_DEF_ BO_ "GenMsgCycleTime" INT 0 65535;
BA_DEF_ BO_ "GenMsgDelayTime" INT 0 65535;
BA_DEF_ BO_ "NmAsrMessage" ENUM "No","Yes";
BA_DEF_ BO_ "DiagState" ENUM "No","Yes";
BA_DEF_ BO_ "DiagConnection" HEX 0 65535;
BA_DEF_ BO_ "VFrameFormat" ENUM "StandardCAN","ExtendedCAN","reserved","reserved","reserved","reserved","reserved","reserved","reserved","reserved","reserved","reserved","reserved","reserved","StandardCAN_FD","ExtendedCAN_FD";
BA_DEF_ BO_ "CANFD_BRS" ENUM "0","1";
BA_DEF_ "Manufacturer" ENUM "DBAG","VAG","BWVAG","PAG","GM";
BA_DEF_ "NmType" STRING ;
BA_DEF_ "BusType" STRING ;
BA_DEF_ "Baudrate" INT 0 1000000;
BA_DEF_ "DBName" STRING ;
BA_DEF_ "NmAsrTimeoutTime" INT 1 65535;
BA_DEF_ "NmAsrWaitBusSleepTime" INT 1 65535;
BA_DEF_ "NmAsrRepeatMessageTime" INT 1 65535;
BA_DEF_ "NmAsrMessageCount" INT 1 256;
BA_DEF_ "NmAsrBaseAddress" HEX 235487232 2147483647;
BA_DEF_ "NmAsrCanMsgCycleTime" INT 1 65535;
BA_DEF_ "Version" HEX 0 255;
BA_DEF_ "VersionWeek" INT 0 53;
BA_DEF_ "VersionYear" INT 0 99;
BA_DEF_ BU_ "Description" STRING ;
BA_DEF_ BU_ "NmStationAddress" HEX 0 255;
BA_DEF_ BU_ "NmNode" ENUM "No","Yes";
BA_DEF_ BU_ "NmAsrNode" ENUM "No","Yes";
BA_DEF_ BU_ "NmAsrNodeIdentifier" HEX 0 255;
BA_DEF_ BU_ "NmAsrCanMsgReducedTime" INT 1 65535;
BA_DEF_ BU_ "NmNodeType" ENUM "+15_NotWakeable","+30_Wakeable","+30_NotWakeable","kMaster","kSlave15","kSlave30","none";
BA_DEF_ BU_ "NwmNodeType" ENUM "+15_NotWakeable","+30_Wakeable","+30_NotWakeable","kMaster","kSlave15","kSlave30","none";
BA_DEF_DEF_ "GenSigTimeoutTime_ADCAM" 2500;
BA_DEF_DEF_ "GenSigTimeoutTime_CVADAS" 2500;
BA_DEF_DEF_ "GenSigTimeoutTime_EVCU2" 2500;
BA_DEF_DEF_ "GenSigTimeoutTime_VDCM" 2500;
BA_DEF_DEF_ "GenSigStartValue" 0;
BA_DEF_DEF_ "GenSigInactiveValue" 0;
BA_DEF_DEF_ "GenSigSendType" "NoSigSendType";
BA_DEF_DEF_ "GenSigTimeoutTime_AHCP" 2500;
BA_DEF_DEF_ "GenSigTimeoutTime_BSM" 2500;
BA_DEF_DEF_ "GenSigTimeoutTime_BSM2" 2500;
BA_DEF_DEF_ "GenSigTimeoutTime_CADM" 2500;
BA_DEF_DEF_ "GenSigTimeoutTime_CVPAM" 2500;
BA_DEF_DEF_ "GenSigTimeoutTime_ECM" 2500;
BA_DEF_DEF_ "GenSigTimeoutTime_EPS" 2500;
BA_DEF_DEF_ "GenSigTimeoutTime_ORC" 2500;
BA_DEF_DEF_ "DiagRequest" "No";
BA_DEF_DEF_ "Type" "-";
BA_DEF_DEF_ "DiagResponse" "No";
BA_DEF_DEF_ "NmMessage" "No";
BA_DEF_DEF_ "GenMsgSendType" "NoMsgSendType";
BA_DEF_DEF_ "GenMsgNrOfRepetition" 0;
BA_DEF_DEF_ "GenMsgILSupport" "No";
BA_DEF_DEF_ "GenMsgCycleTimeFast" 0;
BA_DEF_DEF_ "GenMsgCycleTime" 0;
BA_DEF_DEF_ "GenMsgDelayTime" 0;
BA_DEF_DEF_ "NmAsrMessage" "No";
BA_DEF_DEF_ "DiagState" "No";
BA_DEF_DEF_ "DiagConnection" 0;
BA_DEF_DEF_ "VFrameFormat" "StandardCAN_FD";
BA_DEF_DEF_ "CANFD_BRS" "0";
BA_DEF_DEF_ "Manufacturer" "DBAG";
BA_DEF_DEF_ "NmType" "";
BA_DEF_DEF_ "BusType" "CAN";
BA_DEF_DEF_ "Baudrate" 500000;
BA_DEF_DEF_ "DBName" "CAN";
BA_DEF_DEF_ "NmAsrTimeoutTime" 1000;
BA_DEF_DEF_ "NmAsrWaitBusSleepTime" 750;
BA_DEF_DEF_ "NmAsrRepeatMessageTime" 800;
BA_DEF_DEF_ "NmAsrMessageCount" 256;
BA_DEF_DEF_ "NmAsrBaseAddress" 506724352;
BA_DEF_DEF_ "NmAsrCanMsgCycleTime" 200;
BA_DEF_DEF_ "Version" 160;
BA_DEF_DEF_ "VersionWeek" 34;
BA_DEF_DEF_ "VersionYear" 25;
BA_DEF_DEF_ "Description" "";
BA_DEF_DEF_ "NmStationAddress" 0;
BA_DEF_DEF_ "NmNode" "Yes";
BA_DEF_DEF_ "NmAsrNode" "Yes";
BA_DEF_DEF_ "NmAsrNodeIdentifier" 0;
BA_DEF_DEF_ "NmAsrCanMsgReducedTime" 100;
BA_DEF_DEF_ "NmNodeType" "none";
BA_DEF_DEF_ "NwmNodeType" "none";
BA_ "NmType" "NmAsr";
BA_ "BusType" "CAN FD";
BA_ "DBName" "FDCAN14";
BA_ "NmAsrTimeoutTime" 8000;
BA_ "NmAsrWaitBusSleepTime" 1000;
BA_ "NmAsrRepeatMessageTime" 5000;
BA_ "NmAsrBaseAddress" 507002880;
BA_ "NmAsrCanMsgCycleTime" 1000;
BA_ "Description" BU_ ECM "Engine Control Module";
BA_ "NmStationAddress" BU_ ECM 1;
BA_ "NmAsrNodeIdentifier" BU_ ECM 1;
BA_ "NmAsrCanMsgReducedTime" BU_ ECM 575;
BA_ "NmNodeType" BU_ ECM 2;
BA_ "NwmNodeType" BU_ ECM 2;
BA_ "Type" BO_ 2654486592 8;
BA_ "NmMessage" BO_ 2654486592 1;
BA_ "NmAsrMessage" BO_ 2654486592 1;
BA_ "VFrameFormat" BO_ 2654486592 15;
BA_ "CANFD_BRS" BO_ 2654486592 1;
BA_ "Type" BO_ 263 1;
BA_ "GenMsgSendType" BO_ 263 0;
BA_ "GenMsgILSupport" BO_ 263 1;
BA_ "GenMsgCycleTime" BO_ 263 10;
BA_ "CANFD_BRS" BO_ 263 1;
BA_ "Type" BO_ 2654486689 8;
BA_ "NmMessage" BO_ 2654486689 1;
BA_ "NmAsrMessage" BO_ 2654486689 1;
BA_ "VFrameFormat" BO_ 2654486689 15;
BA_ "CANFD_BRS" BO_ 2654486689 1;
BA_ "Type" BO_ 264 1;
BA_ "GenMsgSendType" BO_ 264 0;
BA_ "GenMsgILSupport" BO_ 264 1;
BA_ "GenMsgCycleTime" BO_ 264 10;
BA_ "CANFD_BRS" BO_ 264 1;
BA_ "Type" BO_ 611 3;
BA_ "GenMsgSendType" BO_ 611 0;
BA_ "GenMsgILSupport" BO_ 611 1;
BA_ "GenMsgCycleTime" BO_ 611 100;
BA_ "GenMsgDelayTime" BO_ 611 20;
BA_ "CANFD_BRS" BO_ 611 1;
BA_ "Type" BO_ 205 1;
BA_ "GenMsgSendType" BO_ 205 0;
BA_ "GenMsgILSupport" BO_ 205 1;
BA_ "GenMsgCycleTime" BO_ 205 10;
BA_ "CANFD_BRS" BO_ 205 1;
BA_ "Type" BO_ 2654486554 8;
BA_ "NmMessage" BO_ 2654486554 1;
BA_ "NmAsrMessage" BO_ 2654486554 1;
BA_ "VFrameFormat" BO_ 2654486554 15;
BA_ "CANFD_BRS" BO_ 2654486554 1;
BA_ "Type" BO_ 280 1;
BA_ "GenMsgSendType" BO_ 280 0;
BA_ "GenMsgILSupport" BO_ 280 1;
BA_ "GenMsgCycleTime" BO_ 280 10;
BA_ "CANFD_BRS" BO_ 280 1;
BA_ "Type" BO_ 2654486676 8;
BA_ "NmMessage" BO_ 2654486676 1;
BA_ "NmAsrMessage" BO_ 2654486676 1;
BA_ "VFrameFormat" BO_ 2654486676 15;
BA_ "CANFD_BRS" BO_ 2654486676 1;
BA_ "Type" BO_ 2654486552 8;
BA_ "NmMessage" BO_ 2654486552 1;
BA_ "NmAsrMessage" BO_ 2654486552 1;
BA_ "VFrameFormat" BO_ 2654486552 15;
BA_ "CANFD_BRS" BO_ 2654486552 1;
BA_ "Type" BO_ 2654486530 8;
BA_ "NmMessage" BO_ 2654486530 1;
BA_ "NmAsrMessage" BO_ 2654486530 1;
BA_ "VFrameFormat" BO_ 2654486530 15;
BA_ "CANFD_BRS" BO_ 2654486530 1;
BA_ "Type" BO_ 2654486614 8;
BA_ "NmMessage" BO_ 2654486614 1;
BA_ "NmAsrMessage" BO_ 2654486614 1;
BA_ "VFrameFormat" BO_ 2654486614 15;
BA_ "CANFD_BRS" BO_ 2654486614 1;
BA_ "Type" BO_ 258 1;
BA_ "GenMsgSendType" BO_ 258 0;
BA_ "GenMsgILSupport" BO_ 258 1;
BA_ "GenMsgCycleTime" BO_ 258 10;
BA_ "CANFD_BRS" BO_ 258 1;
BA_ "Type" BO_ 276 1;
BA_ "GenMsgSendType" BO_ 276 0;
BA_ "GenMsgILSupport" BO_ 276 1;
BA_ "GenMsgCycleTime" BO_ 276 10;
BA_ "CANFD_BRS" BO_ 276 1;
BA_ "Type" BO_ 2654486534 8;
BA_ "NmMessage" BO_ 2654486534 1;
BA_ "NmAsrMessage" BO_ 2654486534 1;
BA_ "VFrameFormat" BO_ 2654486534 15;
BA_ "CANFD_BRS" BO_ 2654486534 1;
BA_ "Type" BO_ 2654486669 8;
BA_ "NmMessage" BO_ 2654486669 1;
BA_ "NmAsrMessage" BO_ 2654486669 1;
BA_ "VFrameFormat" BO_ 2654486669 15;
BA_ "CANFD_BRS" BO_ 2654486669 1;
BA_ "Type" BO_ 1456 3;
BA_ "GenMsgSendType" BO_ 1456 0;
BA_ "GenMsgILSupport" BO_ 1456 1;
BA_ "GenMsgCycleTime" BO_ 1456 100;
BA_ "GenMsgDelayTime" BO_ 1456 20;
BA_ "CANFD_BRS" BO_ 1456 1;
BA_ "Type" BO_ 513 1;
BA_ "GenMsgSendType" BO_ 513 0;
BA_ "GenMsgILSupport" BO_ 513 1;
BA_ "GenMsgCycleTime" BO_ 513 20;
BA_ "CANFD_BRS" BO_ 513 1;
BA_ "Type" BO_ 1155 3;
BA_ "GenMsgSendType" BO_ 1155 0;
BA_ "GenMsgNrOfRepetition" BO_ 1155 2;
BA_ "GenMsgILSupport" BO_ 1155 1;
BA_ "GenMsgCycleTimeFast" BO_ 1155 20;
BA_ "GenMsgCycleTime" BO_ 1155 500;
BA_ "GenMsgDelayTime" BO_ 1155 20;
BA_ "CANFD_BRS" BO_ 1155 1;
BA_ "Type" BO_ 514 1;
BA_ "GenMsgSendType" BO_ 514 0;
BA_ "GenMsgILSupport" BO_ 514 1;
BA_ "GenMsgCycleTime" BO_ 514 20;
BA_ "CANFD_BRS" BO_ 514 1;
BA_ "Type" BO_ 204 1;
BA_ "GenMsgSendType" BO_ 204 0;
BA_ "GenMsgILSupport" BO_ 204 1;
BA_ "GenMsgCycleTime" BO_ 204 10;
BA_ "CANFD_BRS" BO_ 204 1;
BA_ "Type" BO_ 262 1;
BA_ "GenMsgSendType" BO_ 262 0;
BA_ "GenMsgILSupport" BO_ 262 1;
BA_ "GenMsgCycleTime" BO_ 262 10;
BA_ "CANFD_BRS" BO_ 262 1;
BA_ "Type" BO_ 2654486529 8;
BA_ "NmMessage" BO_ 2654486529 1;
BA_ "NmAsrMessage" BO_ 2654486529 1;
BA_ "VFrameFormat" BO_ 2654486529 15;
BA_ "CANFD_BRS" BO_ 2654486529 1;
BA_ "Type" BO_ 1036 3;
BA_ "GenMsgSendType" BO_ 1036 0;
BA_ "GenMsgNrOfRepetition" BO_ 1036 2;
BA_ "GenMsgILSupport" BO_ 1036 1;
BA_ "GenMsgCycleTimeFast" BO_ 1036 20;
BA_ "GenMsgCycleTime" BO_ 1036 100;
BA_ "GenMsgDelayTime" BO_ 1036 20;
BA_ "CANFD_BRS" BO_ 1036 1;
BA_ "Type" BO_ 255 1;
BA_ "GenMsgSendType" BO_ 255 0;
BA_ "GenMsgILSupport" BO_ 255 1;
BA_ "GenMsgCycleTime" BO_ 255 10;
BA_ "CANFD_BRS" BO_ 255 1;
BA_ "Type" BO_ 1054 1;
BA_ "GenMsgSendType" BO_ 1054 0;
BA_ "GenMsgILSupport" BO_ 1054 1;
BA_ "GenMsgCycleTime" BO_ 1054 100;
BA_ "CANFD_BRS" BO_ 1054 1;
BA_ "Type" BO_ 518 1;
BA_ "GenMsgSendType" BO_ 518 0;
BA_ "GenMsgILSupport" BO_ 518 1;
BA_ "GenMsgCycleTime" BO_ 518 20;
BA_ "CANFD_BRS" BO_ 518 1;
BA_ "GenSigTimeoutTime_BSM2" SG_ 1036 CRC_ENGINE3 0;
BA_ "GenSigTimeoutTime_CVPAM" SG_ 1036 CRC_ENGINE3 0;
BA_ "GenSigTimeoutTime_ECM" SG_ 1036 CRC_ENGINE3 0;
BA_ "GenSigTimeoutTime_EPS" SG_ 1036 CRC_ENGINE3 0;
BA_ "GenSigTimeoutTime_ORC" SG_ 1036 CRC_ENGINE3 0;
BA_ "GenSigSendType" SG_ 1036 ISASts 3;
BA_ "GenSigTimeoutTime_AHCP" SG_ 1036 ISASts 0;
BA_ "GenSigTimeoutTime_BSM" SG_ 1036 ISASts 0;
BA_ "GenSigTimeoutTime_BSM2" SG_ 1036 ISASts 0;
BA_ "GenSigTimeoutTime_CADM" SG_ 1036 ISASts 0;
BA_ "GenSigTimeoutTime_CVPAM" SG_ 1036 ISASts 0;
BA_ "GenSigTimeoutTime_ECM" SG_ 1036 ISASts 0;
BA_ "GenSigTimeoutTime_EPS" SG_ 1036 ISASts 0;
BA_ "GenSigTimeoutTime_ORC" SG_ 1036 ISASts 0;
BA_ "GenSigTimeoutTime_AHCP" SG_ 1036 MessageCounter_ENGINE3 0;
BA_ "GenSigTimeoutTime_BSM2" SG_ 1036 MessageCounter_ENGINE3 0;
BA_ "GenSigTimeoutTime_CVPAM" SG_ 1036 MessageCounter_ENGINE3 0;
BA_ "GenSigTimeoutTime_ECM" SG_ 1036 MessageCounter_ENGINE3 0;
BA_ "GenSigTimeoutTime_EPS" SG_ 1036 MessageCounter_ENGINE3 0;
BA_ "GenSigTimeoutTime_ORC" SG_ 1036 MessageCounter_ENGINE3 0;
BA_ "GenSigSendType" SG_ 1036 Override 3;
BA_ "GenSigTimeoutTime_AHCP" SG_ 1036 Override 0;
BA_ "GenSigTimeoutTime_BSM2" SG_ 1036 Override 0;
BA_ "GenSigTimeoutTime_CVPAM" SG_ 1036 Override 0;
BA_ "GenSigTimeoutTime_ECM" SG_ 1036 Override 0;
BA_ "GenSigTimeoutTime_EPS" SG_ 1036 Override 0;
BA_ "GenSigTimeoutTime_ORC" SG_ 1036 Override 0;
BA_ "GenSigStartValue" SG_ 1036 SpeedLimitSts 2;
BA_ "GenSigSendType" SG_ 1036 SpeedLimitSts 3;
BA_ "GenSigTimeoutTime_AHCP" SG_ 1036 SpeedLimitSts 0;
BA_ "GenSigTimeoutTime_BSM" SG_ 1036 SpeedLimitSts 0;
BA_ "GenSigTimeoutTime_BSM2" SG_ 1036 SpeedLimitSts 0;
BA_ "GenSigTimeoutTime_CVPAM" SG_ 1036 SpeedLimitSts 0;
BA_ "GenSigTimeoutTime_ECM" SG_ 1036 SpeedLimitSts 0;
BA_ "GenSigTimeoutTime_EPS" SG_ 1036 SpeedLimitSts 0;
BA_ "GenSigTimeoutTime_ORC" SG_ 1036 SpeedLimitSts 0;
BA_ "GenSigTimeoutTime_ADCAM" SG_ 255 Rear_AxleTorque_Static 0;
BA_ "GenSigTimeoutTime_CVADAS" SG_ 255 Rear_AxleTorque_Static 0;
BA_ "GenSigTimeoutTime_EVCU2" SG_ 255 Rear_AxleTorque_Static 0;
BA_ "GenSigStartValue" SG_ 255 Rear_AxleTorque_Static 32767;
BA_ "GenSigTimeoutTime_BSM" SG_ 255 Rear_AxleTorque_Static 0;
BA_ "GenSigTimeoutTime_ECM" SG_ 255 Rear_AxleTorque_Static 0;
BA_ "GenSigTimeoutTime_EPS" SG_ 255 Rear_AxleTorque_Static 0;
BA_ "GenSigTimeoutTime_ORC" SG_ 255 Rear_AxleTorque_Static 0;
BA_ "GenSigTimeoutTime_ADCAM" SG_ 255 Front_AxleTorque_Static 0;
BA_ "GenSigTimeoutTime_CVADAS" SG_ 255 Front_AxleTorque_Static 0;
BA_ "GenSigTimeoutTime_EVCU2" SG_ 255 Front_AxleTorque_Static 0;
BA_ "GenSigStartValue" SG_ 255 Front_AxleTorque_Static 32767;
BA_ "GenSigTimeoutTime_BSM" SG_ 255 Front_AxleTorque_Static 0;
BA_ "GenSigTimeoutTime_ECM" SG_ 255 Front_AxleTorque_Static 0;
BA_ "GenSigTimeoutTime_ORC" SG_ 255 Front_AxleTorque_Static 0;
BA_ "GenSigTimeoutTime_CVADAS" SG_ 255 ACC_NCC_TrqEnblRq_Allowed 0;
BA_ "GenSigTimeoutTime_EVCU2" SG_ 255 ACC_NCC_TrqEnblRq_Allowed 0;
BA_ "GenSigTimeoutTime_VDCM" SG_ 255 ACC_NCC_TrqEnblRq_Allowed 0;
BA_ "GenSigTimeoutTime_CVADAS" SG_ 255 Accel_Pedal_Override 0;
BA_ "GenSigTimeoutTime_EVCU2" SG_ 255 Accel_Pedal_Override 0;
BA_ "GenSigTimeoutTime_VDCM" SG_ 255 Accel_Pedal_Override 0;
BA_ "GenSigTimeoutTime_ADCAM" SG_ 255 ESC_TrqEnblRq_Allowed 0;
BA_ "GenSigTimeoutTime_CVADAS" SG_ 255 ESC_TrqEnblRq_Allowed 0;
BA_ "GenSigTimeoutTime_EVCU2" SG_ 255 ESC_TrqEnblRq_Allowed 0;
BA_ "GenSigTimeoutTime_VDCM" SG_ 255 ESC_TrqEnblRq_Allowed 0;
BA_ "GenSigTimeoutTime_ADCAM" SG_ 255 SSC_TrqEnblRq_Allowed 0;
BA_ "GenSigTimeoutTime_CVADAS" SG_ 255 SSC_TrqEnblRq_Allowed 0;
BA_ "GenSigTimeoutTime_EVCU2" SG_ 255 SSC_TrqEnblRq_Allowed 0;
BA_ "GenSigTimeoutTime_VDCM" SG_ 255 SSC_TrqEnblRq_Allowed 0;
BA_ "GenSigTimeoutTime_CVADAS" SG_ 255 CRC_PT_TORQUE_FD_1 0;
BA_ "GenSigTimeoutTime_EVCU2" SG_ 255 CRC_PT_TORQUE_FD_1 0;
BA_ "GenSigTimeoutTime_VDCM" SG_ 255 CRC_PT_TORQUE_FD_1 0;
BA_ "GenSigTimeoutTime_CVADAS" SG_ 255 MessageCounter_PT_TORQUE_FD_1 0;
BA_ "GenSigTimeoutTime_EVCU2" SG_ 255 MessageCounter_PT_TORQUE_FD_1 0;
BA_ "GenSigTimeoutTime_VDCM" SG_ 255 MessageCounter_PT_TORQUE_FD_1 0;
BA_ "GenSigTimeoutTime_CVADAS" SG_ 255 Total_AxleTorque_Static 0;
BA_ "GenSigTimeoutTime_EVCU2" SG_ 255 Total_AxleTorque_Static 0;
BA_ "GenSigTimeoutTime_ADCAM" SG_ 255 SumTorque_DrvReqMod 0;
BA_ "GenSigTimeoutTime_CVADAS" SG_ 255 SumTorque_DrvReqMod 0;
BA_ "GenSigTimeoutTime_EVCU2" SG_ 255 SumTorque_DrvReqMod 0;
BA_ "GenSigTimeoutTime_VDCM" SG_ 255 SumTorque_DrvReqMod 0;
BA_ "GenSigTimeoutTime_ADCAM" SG_ 255 SumTorqueMax 0;
BA_ "GenSigTimeoutTime_CVADAS" SG_ 255 SumTorqueMax 0;
BA_ "GenSigTimeoutTime_EVCU2" SG_ 255 SumTorqueMax 0;
BA_ "GenSigTimeoutTime_VDCM" SG_ 255 SumTorqueMax 0;
BA_ "GenSigTimeoutTime_ADCAM" SG_ 255 SumTorqueMin 0;
BA_ "GenSigTimeoutTime_CVADAS" SG_ 255 SumTorqueMin 0;
BA_ "GenSigTimeoutTime_EVCU2" SG_ 255 SumTorqueMin 0;
BA_ "GenSigTimeoutTime_VDCM" SG_ 255 SumTorqueMin 0;
BA_ "GenSigTimeoutTime_ADCAM" SG_ 255 SumTorqueSel_D_TTC 0;
BA_ "GenSigTimeoutTime_CVADAS" SG_ 255 SumTorqueSel_D_TTC 0;
BA_ "GenSigTimeoutTime_EVCU2" SG_ 255 SumTorqueSel_D_TTC 0;
BA_ "GenSigTimeoutTime_VDCM" SG_ 255 SumTorqueSel_D_TTC 0;
BA_ "GenSigTimeoutTime_ADCAM" SG_ 255 SumTorqueStatic 0;
BA_ "GenSigTimeoutTime_CVADAS" SG_ 255 SumTorqueStatic 0;
BA_ "GenSigTimeoutTime_EVCU2" SG_ 255 SumTorqueStatic 0;
BA_ "GenSigTimeoutTime_VDCM" SG_ 255 SumTorqueStatic 0;
BA_ "GenSigTimeoutTime_AHCP" SG_ 255 ACC_NCC_TrqEnblRq_Allowed 0;
BA_ "GenSigTimeoutTime_BSM" SG_ 255 ACC_NCC_TrqEnblRq_Allowed 0;
BA_ "GenSigTimeoutTime_BSM2" SG_ 255 ACC_NCC_TrqEnblRq_Allowed 0;
BA_ "GenSigTimeoutTime_CVPAM" SG_ 255 ACC_NCC_TrqEnblRq_Allowed 0;
BA_ "GenSigTimeoutTime_ECM" SG_ 255 ACC_NCC_TrqEnblRq_Allowed 0;
BA_ "GenSigTimeoutTime_EPS" SG_ 255 ACC_NCC_TrqEnblRq_Allowed 0;
BA_ "GenSigTimeoutTime_ORC" SG_ 255 ACC_NCC_TrqEnblRq_Allowed 0;
BA_ "GenSigTimeoutTime_AHCP" SG_ 255 Accel_Pedal_Override 0;
BA_ "GenSigTimeoutTime_BSM2" SG_ 255 Accel_Pedal_Override 0;
BA_ "GenSigTimeoutTime_CVPAM" SG_ 255 Accel_Pedal_Override 0;
BA_ "GenSigTimeoutTime_ECM" SG_ 255 Accel_Pedal_Override 0;
BA_ "GenSigTimeoutTime_EPS" SG_ 255 Accel_Pedal_Override 0;
BA_ "GenSigTimeoutTime_ORC" SG_ 255 Accel_Pedal_Override 0;
BA_ "GenSigTimeoutTime_AHCP" SG_ 255 ESC_TrqEnblRq_Allowed 0;
BA_ "GenSigTimeoutTime_BSM" SG_ 255 ESC_TrqEnblRq_Allowed 0;
BA_ "GenSigTimeoutTime_BSM2" SG_ 255 ESC_TrqEnblRq_Allowed 0;
BA_ "GenSigTimeoutTime_CADM" SG_ 255 ESC_TrqEnblRq_Allowed 0;
BA_ "GenSigTimeoutTime_CVPAM" SG_ 255 ESC_TrqEnblRq_Allowed 0;
BA_ "GenSigTimeoutTime_ECM" SG_ 255 ESC_TrqEnblRq_Allowed 0;
BA_ "GenSigTimeoutTime_EPS" SG_ 255 ESC_TrqEnblRq_Allowed 0;
BA_ "GenSigTimeoutTime_ORC" SG_ 255 ESC_TrqEnblRq_Allowed 0;
BA_ "GenSigTimeoutTime_AHCP" SG_ 255 SSC_TrqEnblRq_Allowed 0;
BA_ "GenSigTimeoutTime_BSM" SG_ 255 SSC_TrqEnblRq_Allowed 0;
BA_ "GenSigTimeoutTime_BSM2" SG_ 255 SSC_TrqEnblRq_Allowed 0;
BA_ "GenSigTimeoutTime_CADM" SG_ 255 SSC_TrqEnblRq_Allowed 0;
BA_ "GenSigTimeoutTime_CVPAM" SG_ 255 SSC_TrqEnblRq_Allowed 0;
BA_ "GenSigTimeoutTime_ECM" SG_ 255 SSC_TrqEnblRq_Allowed 0;
BA_ "GenSigTimeoutTime_EPS" SG_ 255 SSC_TrqEnblRq_Allowed 0;
BA_ "GenSigTimeoutTime_ORC" SG_ 255 SSC_TrqEnblRq_Allowed 0;
BA_ "GenSigTimeoutTime_AHCP" SG_ 255 CRC_PT_TORQUE_FD_1 0;
BA_ "GenSigTimeoutTime_BSM" SG_ 255 CRC_PT_TORQUE_FD_1 0;
BA_ "GenSigTimeoutTime_BSM2" SG_ 255 CRC_PT_TORQUE_FD_1 0;
BA_ "GenSigTimeoutTime_CVPAM" SG_ 255 CRC_PT_TORQUE_FD_1 0;
BA_ "GenSigTimeoutTime_ECM" SG_ 255 CRC_PT_TORQUE_FD_1 0;
BA_ "GenSigTimeoutTime_EPS" SG_ 255 CRC_PT_TORQUE_FD_1 0;
BA_ "GenSigTimeoutTime_ORC" SG_ 255 CRC_PT_TORQUE_FD_1 0;
BA_ "GenSigTimeoutTime_AHCP" SG_ 255 MessageCounter_PT_TORQUE_FD_1 0;
BA_ "GenSigTimeoutTime_BSM" SG_ 255 MessageCounter_PT_TORQUE_FD_1 0;
BA_ "GenSigTimeoutTime_BSM2" SG_ 255 MessageCounter_PT_TORQUE_FD_1 0;
BA_ "GenSigTimeoutTime_CVPAM" SG_ 255 MessageCounter_PT_TORQUE_FD_1 0;
BA_ "GenSigTimeoutTime_ECM" SG_ 255 MessageCounter_PT_TORQUE_FD_1 0;
BA_ "GenSigTimeoutTime_EPS" SG_ 255 MessageCounter_PT_TORQUE_FD_1 0;
BA_ "GenSigTimeoutTime_ORC" SG_ 255 MessageCounter_PT_TORQUE_FD_1 0;
BA_ "GenSigStartValue" SG_ 255 Total_AxleTorque_Static 32767;
BA_ "GenSigTimeoutTime_AHCP" SG_ 255 Total_AxleTorque_Static 0;
BA_ "GenSigTimeoutTime_BSM" SG_ 255 Total_AxleTorque_Static 0;
BA_ "GenSigTimeoutTime_BSM2" SG_ 255 Total_AxleTorque_Static 0;
BA_ "GenSigTimeoutTime_CVPAM" SG_ 255 Total_AxleTorque_Static 0;
BA_ "GenSigTimeoutTime_ECM" SG_ 255 Total_AxleTorque_Static 0;
BA_ "GenSigTimeoutTime_EPS" SG_ 255 Total_AxleTorque_Static 0;
BA_ "GenSigTimeoutTime_ORC" SG_ 255 Total_AxleTorque_Static 0;
BA_ "GenSigTimeoutTime_AHCP" SG_ 255 SumTorque_DrvReqMod 0;
BA_ "GenSigTimeoutTime_BSM" SG_ 255 SumTorque_DrvReqMod 0;
BA_ "GenSigTimeoutTime_BSM2" SG_ 255 SumTorque_DrvReqMod 0;
BA_ "GenSigTimeoutTime_CVPAM" SG_ 255 SumTorque_DrvReqMod 0;
BA_ "GenSigTimeoutTime_ECM" SG_ 255 SumTorque_DrvReqMod 0;
BA_ "GenSigTimeoutTime_EPS" SG_ 255 SumTorque_DrvReqMod 0;
BA_ "GenSigTimeoutTime_ORC" SG_ 255 SumTorque_DrvReqMod 0;
BA_ "GenSigTimeoutTime_AHCP" SG_ 255 SumTorqueExp 0;
BA_ "GenSigTimeoutTime_BSM" SG_ 255 SumTorqueExp 0;
BA_ "GenSigTimeoutTime_BSM2" SG_ 255 SumTorqueExp 0;
BA_ "GenSigTimeoutTime_CADM" SG_ 255 SumTorqueExp 0;
BA_ "GenSigTimeoutTime_CVPAM" SG_ 255 SumTorqueExp 0;
BA_ "GenSigTimeoutTime_ECM" SG_ 255 SumTorqueExp 0;
BA_ "GenSigTimeoutTime_EPS" SG_ 255 SumTorqueExp 0;
BA_ "GenSigTimeoutTime_ORC" SG_ 255 SumTorqueExp 0;
BA_ "GenSigTimeoutTime_AHCP" SG_ 255 SumTorqueMax 0;
BA_ "GenSigTimeoutTime_BSM" SG_ 255 SumTorqueMax 0;
BA_ "GenSigTimeoutTime_BSM2" SG_ 255 SumTorqueMax 0;
BA_ "GenSigTimeoutTime_CVPAM" SG_ 255 SumTorqueMax 0;
BA_ "GenSigTimeoutTime_ECM" SG_ 255 SumTorqueMax 0;
BA_ "GenSigTimeoutTime_EPS" SG_ 255 SumTorqueMax 0;
BA_ "GenSigTimeoutTime_ORC" SG_ 255 SumTorqueMax 0;
BA_ "GenSigTimeoutTime_AHCP" SG_ 255 SumTorqueMin 0;
BA_ "GenSigTimeoutTime_BSM" SG_ 255 SumTorqueMin 0;
BA_ "GenSigTimeoutTime_BSM2" SG_ 255 SumTorqueMin 0;
BA_ "GenSigTimeoutTime_CVPAM" SG_ 255 SumTorqueMin 0;
BA_ "GenSigTimeoutTime_ECM" SG_ 255 SumTorqueMin 0;
BA_ "GenSigTimeoutTime_EPS" SG_ 255 SumTorqueMin 0;
BA_ "GenSigTimeoutTime_ORC" SG_ 255 SumTorqueMin 0;
BA_ "GenSigTimeoutTime_AHCP" SG_ 255 SumTorqueSel_D_TTC 0;
BA_ "GenSigTimeoutTime_BSM" SG_ 255 SumTorqueSel_D_TTC 0;
BA_ "GenSigTimeoutTime_BSM2" SG_ 255 SumTorqueSel_D_TTC 0;
BA_ "GenSigTimeoutTime_CVPAM" SG_ 255 SumTorqueSel_D_TTC 0;
BA_ "GenSigTimeoutTime_ECM" SG_ 255 SumTorqueSel_D_TTC 0;
BA_ "GenSigTimeoutTime_EPS" SG_ 255 SumTorqueSel_D_TTC 0;
BA_ "GenSigTimeoutTime_ORC" SG_ 255 SumTorqueSel_D_TTC 0;
BA_ "GenSigTimeoutTime_AHCP" SG_ 255 SumTorqueStatic 0;
BA_ "GenSigTimeoutTime_BSM" SG_ 255 SumTorqueStatic 0;
BA_ "GenSigTimeoutTime_BSM2" SG_ 255 SumTorqueStatic 0;
BA_ "GenSigTimeoutTime_CVPAM" SG_ 255 SumTorqueStatic 0;
BA_ "GenSigTimeoutTime_ECM" SG_ 255 SumTorqueStatic 0;
BA_ "GenSigTimeoutTime_EPS" SG_ 255 SumTorqueStatic 0;
BA_ "GenSigTimeoutTime_ORC" SG_ 255 SumTorqueStatic 0;
BA_ "GenSigTimeoutTime_CVADAS" SG_ 1054 ThermalManagementActive_W 0;
BA_ "GenSigTimeoutTime_EVCU2" SG_ 1054 ThermalManagementActive_W 0;
BA_ "GenSigTimeoutTime_VDCM" SG_ 1054 ThermalManagementActive_W 0;
BA_ "GenSigTimeoutTime_AHCP" SG_ 1054 CRC_ENGINE1 0;
BA_ "GenSigTimeoutTime_BSM" SG_ 1054 CRC_ENGINE1 0;
BA_ "GenSigTimeoutTime_BSM2" SG_ 1054 CRC_ENGINE1 0;
BA_ "GenSigTimeoutTime_CVPAM" SG_ 1054 CRC_ENGINE1 0;
BA_ "GenSigTimeoutTime_ECM" SG_ 1054 CRC_ENGINE1 0;
BA_ "GenSigTimeoutTime_EPS" SG_ 1054 CRC_ENGINE1 0;
BA_ "GenSigTimeoutTime_ORC" SG_ 1054 CRC_ENGINE1 0;
BA_ "GenSigTimeoutTime_AHCP" SG_ 1054 MessageCounter_ENGINE1 0;
BA_ "GenSigTimeoutTime_BSM" SG_ 1054 MessageCounter_ENGINE1 0;
BA_ "GenSigTimeoutTime_BSM2" SG_ 1054 MessageCounter_ENGINE1 0;
BA_ "GenSigTimeoutTime_CVPAM" SG_ 1054 MessageCounter_ENGINE1 0;
BA_ "GenSigTimeoutTime_ECM" SG_ 1054 MessageCounter_ENGINE1 0;
BA_ "GenSigTimeoutTime_EPS" SG_ 1054 MessageCounter_ENGINE1 0;
BA_ "GenSigTimeoutTime_ORC" SG_ 1054 MessageCounter_ENGINE1 0;
BA_ "GenSigTimeoutTime_AHCP" SG_ 1054 ThermalManagementActive_W 0;
BA_ "GenSigTimeoutTime_BSM" SG_ 1054 ThermalManagementActive_W 0;
BA_ "GenSigTimeoutTime_BSM2" SG_ 1054 ThermalManagementActive_W 0;
BA_ "GenSigTimeoutTime_CVPAM" SG_ 1054 ThermalManagementActive_W 0;
BA_ "GenSigTimeoutTime_ECM" SG_ 1054 ThermalManagementActive_W 0;
BA_ "GenSigTimeoutTime_EPS" SG_ 1054 ThermalManagementActive_W 0;
BA_ "GenSigTimeoutTime_ORC" SG_ 1054 ThermalManagementActive_W 0;
BA_ "GenSigTimeoutTime_CVADAS" SG_ 518 CRC_ENGINE5 0;
BA_ "GenSigTimeoutTime_EVCU2" SG_ 518 CRC_ENGINE5 0;
BA_ "GenSigTimeoutTime_VDCM" SG_ 518 CRC_ENGINE5 0;
BA_ "GenSigTimeoutTime_BSM" SG_ 518 CRC_ENGINE5 0;
BA_ "GenSigTimeoutTime_CVADAS" SG_ 518 MessageCounter_ENGINE5 0;
BA_ "GenSigTimeoutTime_EVCU2" SG_ 518 MessageCounter_ENGINE5 0;
BA_ "GenSigTimeoutTime_VDCM" SG_ 518 MessageCounter_ENGINE5 0;
BA_ "GenSigTimeoutTime_BSM" SG_ 518 MessageCounter_ENGINE5 0;
BA_ "GenSigTimeoutTime_CVADAS" SG_ 518 PdlPosActual 0;
BA_ "GenSigTimeoutTime_EVCU2" SG_ 518 PdlPosActual 0;
BA_ "GenSigTimeoutTime_VDCM" SG_ 518 PdlPosActual 0;
BA_ "GenSigTimeoutTime_CVADAS" SG_ 518 RPMOverRev_W 0;
BA_ "GenSigTimeoutTime_EVCU2" SG_ 518 RPMOverRev_W 0;
BA_ "GenSigTimeoutTime_VDCM" SG_ 518 RPMOverRev_W 0;
BA_ "GenSigTimeoutTime_AHCP" SG_ 518 CRC_ENGINE5 0;
BA_ "GenSigTimeoutTime_CVPAM" SG_ 518 CRC_ENGINE5 0;
BA_ "GenSigTimeoutTime_ECM" SG_ 518 CRC_ENGINE5 0;
BA_ "GenSigTimeoutTime_EPS" SG_ 518 CRC_ENGINE5 0;
BA_ "GenSigTimeoutTime_ORC" SG_ 518 CRC_ENGINE5 0;
BA_ "GenSigStartValue" SG_ 518 EngTrqEnblRq_DAS_W 1;
BA_ "GenSigTimeoutTime_AHCP" SG_ 518 EngTrqEnblRq_DAS_W 0;
BA_ "GenSigTimeoutTime_ADCAM" SG_ 2654486592 CBV_bit0_RepeatMessageRequestBit_1E384040 0;
BA_ "GenSigTimeoutTime_CVADAS" SG_ 2654486592 CBV_bit0_RepeatMessageRequestBit_1E384040 0;
BA_ "GenSigTimeoutTime_EVCU2" SG_ 2654486592 CBV_bit0_RepeatMessageRequestBit_1E384040 0;
BA_ "GenSigTimeoutTime_VDCM" SG_ 2654486592 CBV_bit0_RepeatMessageRequestBit_1E384040 0;
BA_ "GenSigTimeoutTime_BSM" SG_ 2654486592 CBV_bit0_RepeatMessageRequestBit_1E384040 0;
BA_ "GenSigTimeoutTime_ECM" SG_ 2654486592 CBV_bit0_RepeatMessageRequestBit_1E384040 0;
BA_ "GenSigTimeoutTime_EPS" SG_ 2654486592 CBV_bit0_RepeatMessageRequestBit_1E384040 0;
BA_ "GenSigTimeoutTime_ORC" SG_ 2654486592 CBV_bit0_RepeatMessageRequestBit_1E384040 0;
BA_ "GenSigTimeoutTime_ADCAM" SG_ 2654486592 CBV_bit1_1E384040 0;
BA_ "GenSigTimeoutTime_CVADAS" SG_ 2654486592 CBV_bit1_1E384040 0;
BA_ "GenSigTimeoutTime_EVCU2" SG_ 2654486592 CBV_bit1_1E384040 0;
BA_ "GenSigTimeoutTime_VDCM" SG_ 2654486592 CBV_bit1_1E384040 0;
BA_ "GenSigTimeoutTime_BSM" SG_ 2654486592 CBV_bit1_1E384040 0;
BA_ "GenSigTimeoutTime_ECM" SG_ 2654486592 CBV_bit1_1E384040 0;
BA_ "GenSigTimeoutTime_EPS" SG_ 2654486592 CBV_bit1_1E384040 0;
BA_ "GenSigTimeoutTime_ORC" SG_ 2654486592 CBV_bit1_1E384040 0;
BA_ "GenSigTimeoutTime_ADCAM" SG_ 2654486592 CBV_bit2_1E384040 0;
BA_ "GenSigTimeoutTime_CVADAS" SG_ 2654486592 CBV_bit2_1E384040 0;
BA_ "GenSigTimeoutTime_EVCU2" SG_ 2654486592 CBV_bit2_1E384040 0;
BA_ "GenSigTimeoutTime_VDCM" SG_ 2654486592 CBV_bit2_1E384040 0;
BA_ "GenSigTimeoutTime_BSM" SG_ 2654486592 CBV_bit2_1E384040 0;
BA_ "GenSigTimeoutTime_ECM" SG_ 2654486592 CBV_bit2_1E384040 0;
BA_ "GenSigTimeoutTime_EPS" SG_ 2654486592 CBV_bit2_1E384040 0;
BA_ "GenSigTimeoutTime_ORC" SG_ 2654486592 CBV_bit2_1E384040 0;
BA_ "GenSigTimeoutTime_ADCAM" SG_ 2654486592 CBV_bit3_NMCoordinatorBit_1E384040 0;
BA_ "GenSigTimeoutTime_CVADAS" SG_ 2654486592 CBV_bit3_NMCoordinatorBit_1E384040 0;
BA_ "GenSigTimeoutTime_EVCU2" SG_ 2654486592 CBV_bit3_NMCoordinatorBit_1E384040 0;
BA_ "GenSigTimeoutTime_VDCM" SG_ 2654486592 CBV_bit3_NMCoordinatorBit_1E384040 0;
BA_ "GenSigTimeoutTime_BSM" SG_ 2654486592 CBV_bit3_NMCoordinatorBit_1E384040 0;
BA_ "GenSigTimeoutTime_ECM" SG_ 2654486592 CBV_bit3_NMCoordinatorBit_1E384040 0;
BA_ "GenSigTimeoutTime_EPS" SG_ 2654486592 CBV_bit3_NMCoordinatorBit_1E384040 0;
BA_ "GenSigTimeoutTime_ORC" SG_ 2654486592 CBV_bit3_NMCoordinatorBit_1E384040 0;
BA_ "GenSigTimeoutTime_ADCAM" SG_ 2654486592 CBV_bit4_ActiveWakeupBit_1E384040 0;
BA_ "GenSigTimeoutTime_CVADAS" SG_ 2654486592 CBV_bit4_ActiveWakeupBit_1E384040 0;
BA_ "GenSigTimeoutTime_EVCU2" SG_ 2654486592 CBV_bit4_ActiveWakeupBit_1E384040 0;
BA_ "GenSigTimeoutTime_VDCM" SG_ 2654486592 CBV_bit4_ActiveWakeupBit_1E384040 0;
BA_ "GenSigTimeoutTime_BSM" SG_ 2654486592 CBV_bit4_ActiveWakeupBit_1E384040 0;
BA_ "GenSigTimeoutTime_ECM" SG_ 2654486592 CBV_bit4_ActiveWakeupBit_1E384040 0;
BA_ "GenSigTimeoutTime_EPS" SG_ 2654486592 CBV_bit4_ActiveWakeupBit_1E384040 0;
BA_ "GenSigTimeoutTime_ORC" SG_ 2654486592 CBV_bit4_ActiveWakeupBit_1E384040 0;
BA_ "GenSigTimeoutTime_ADCAM" SG_ 2654486592 CBV_bit5_1E384040 0;
BA_ "GenSigTimeoutTime_CVADAS" SG_ 2654486592 CBV_bit5_1E384040 0;
BA_ "GenSigTimeoutTime_EVCU2" SG_ 2654486592 CBV_bit5_1E384040 0;
BA_ "GenSigTimeoutTime_VDCM" SG_ 2654486592 CBV_bit5_1E384040 0;
BA_ "GenSigTimeoutTime_BSM" SG_ 2654486592 CBV_bit5_1E384040 0;
BA_ "GenSigTimeoutTime_ECM" SG_ 2654486592 CBV_bit5_1E384040 0;
BA_ "GenSigTimeoutTime_EPS" SG_ 2654486592 CBV_bit5_1E384040 0;
BA_ "GenSigTimeoutTime_ORC" SG_ 2654486592 CBV_bit5_1E384040 0;
BA_ "GenSigTimeoutTime_ADCAM" SG_ 2654486592 CBV_bit6_PartialNtwInfBit_1E384040 0;
BA_ "GenSigTimeoutTime_CVADAS" SG_ 2654486592 CBV_bit6_PartialNtwInfBit_1E384040 0;
BA_ "GenSigTimeoutTime_EVCU2" SG_ 2654486592 CBV_bit6_PartialNtwInfBit_1E384040 0;
BA_ "GenSigTimeoutTime_VDCM" SG_ 2654486592 CBV_bit6_PartialNtwInfBit_1E384040 0;
BA_ "GenSigTimeoutTime_BSM" SG_ 2654486592 CBV_bit6_PartialNtwInfBit_1E384040 0;
BA_ "GenSigTimeoutTime_ECM" SG_ 2654486592 CBV_bit6_PartialNtwInfBit_1E384040 0;
BA_ "GenSigTimeoutTime_EPS" SG_ 2654486592 CBV_bit6_PartialNtwInfBit_1E384040 0;
BA_ "GenSigTimeoutTime_ORC" SG_ 2654486592 CBV_bit6_PartialNtwInfBit_1E384040 0;
BA_ "GenSigTimeoutTime_ADCAM" SG_ 2654486592 CBV_bit7_1E384040 0;
BA_ "GenSigTimeoutTime_CVADAS" SG_ 2654486592 CBV_bit7_1E384040 0;
BA_ "GenSigTimeoutTime_EVCU2" SG_ 2654486592 CBV_bit7_1E384040 0;
BA_ "GenSigTimeoutTime_VDCM" SG_ 2654486592 CBV_bit7_1E384040 0;
BA_ "GenSigTimeoutTime_BSM" SG_ 2654486592 CBV_bit7_1E384040 0;
BA_ "GenSigTimeoutTime_ECM" SG_ 2654486592 CBV_bit7_1E384040 0;
BA_ "GenSigTimeoutTime_EPS" SG_ 2654486592 CBV_bit7_1E384040 0;
BA_ "GenSigTimeoutTime_ORC" SG_ 2654486592 CBV_bit7_1E384040 0;
BA_ "GenSigTimeoutTime_ADCAM" SG_ 2654486592 SourceNodeIdentifier_1E384040 0;
BA_ "GenSigTimeoutTime_CVADAS" SG_ 2654486592 SourceNodeIdentifier_1E384040 0;
BA_ "GenSigTimeoutTime_EVCU2" SG_ 2654486592 SourceNodeIdentifier_1E384040 0;
BA_ "GenSigTimeoutTime_VDCM" SG_ 2654486592 SourceNodeIdentifier_1E384040 0;
BA_ "GenSigTimeoutTime_BSM" SG_ 2654486592 SourceNodeIdentifier_1E384040 0;
BA_ "GenSigTimeoutTime_ECM" SG_ 2654486592 SourceNodeIdentifier_1E384040 0;
BA_ "GenSigTimeoutTime_EPS" SG_ 2654486592 SourceNodeIdentifier_1E384040 0;
BA_ "GenSigTimeoutTime_ORC" SG_ 2654486592 SourceNodeIdentifier_1E384040 0;
BA_ "GenSigTimeoutTime_CVADAS" SG_ 263 CRC_PT_SYSTEM_FD_1 0;
BA_ "GenSigTimeoutTime_EVCU2" SG_ 263 CRC_PT_SYSTEM_FD_1 0;
BA_ "GenSigTimeoutTime_VDCM" SG_ 263 CRC_PT_SYSTEM_FD_1 0;
BA_ "GenSigTimeoutTime_BSM" SG_ 263 CRC_PT_SYSTEM_FD_1 0;
BA_ "GenSigTimeoutTime_ORC" SG_ 263 CRC_PT_SYSTEM_FD_1 0;
BA_ "GenSigTimeoutTime_CVADAS" SG_ 263 MessageCounter_PT_SYSTEM_FD_1 0;
BA_ "GenSigTimeoutTime_EVCU2" SG_ 263 MessageCounter_PT_SYSTEM_FD_1 0;
BA_ "GenSigTimeoutTime_VDCM" SG_ 263 MessageCounter_PT_SYSTEM_FD_1 0;
BA_ "GenSigTimeoutTime_BSM" SG_ 263 MessageCounter_PT_SYSTEM_FD_1 0;
BA_ "GenSigTimeoutTime_ORC" SG_ 263 MessageCounter_PT_SYSTEM_FD_1 0;
BA_ "GenSigTimeoutTime_ADCAM" SG_ 2654486689 CBV_bit0_RepeatMessageRequestBit_1E3840A1 0;
BA_ "GenSigTimeoutTime_CVADAS" SG_ 2654486689 CBV_bit0_RepeatMessageRequestBit_1E3840A1 0;
BA_ "GenSigTimeoutTime_EVCU2" SG_ 2654486689 CBV_bit0_RepeatMessageRequestBit_1E3840A1 0;
BA_ "GenSigTimeoutTime_VDCM" SG_ 2654486689 CBV_bit0_RepeatMessageRequestBit_1E3840A1 0;
BA_ "GenSigTimeoutTime_BSM" SG_ 2654486689 CBV_bit0_RepeatMessageRequestBit_1E3840A1 0;
BA_ "GenSigTimeoutTime_ECM" SG_ 2654486689 CBV_bit0_RepeatMessageRequestBit_1E3840A1 0;
BA_ "GenSigTimeoutTime_EPS" SG_ 2654486689 CBV_bit0_RepeatMessageRequestBit_1E3840A1 0;
BA_ "GenSigTimeoutTime_ORC" SG_ 2654486689 CBV_bit0_RepeatMessageRequestBit_1E3840A1 0;
BA_ "GenSigTimeoutTime_ADCAM" SG_ 2654486689 CBV_bit3_NMCoordinatorBit_1E3840A1 0;
BA_ "GenSigTimeoutTime_CVADAS" SG_ 2654486689 CBV_bit3_NMCoordinatorBit_1E3840A1 0;
BA_ "GenSigTimeoutTime_EVCU2" SG_ 2654486689 CBV_bit3_NMCoordinatorBit_1E3840A1 0;
BA_ "GenSigTimeoutTime_VDCM" SG_ 2654486689 CBV_bit3_NMCoordinatorBit_1E3840A1 0;
BA_ "GenSigTimeoutTime_BSM" SG_ 2654486689 CBV_bit3_NMCoordinatorBit_1E3840A1 0;
BA_ "GenSigTimeoutTime_ECM" SG_ 2654486689 CBV_bit3_NMCoordinatorBit_1E3840A1 0;
BA_ "GenSigTimeoutTime_EPS" SG_ 2654486689 CBV_bit3_NMCoordinatorBit_1E3840A1 0;
BA_ "GenSigTimeoutTime_ORC" SG_ 2654486689 CBV_bit3_NMCoordinatorBit_1E3840A1 0;
BA_ "GenSigTimeoutTime_ADCAM" SG_ 2654486689 CBV_bit4_ActiveWakeupBit_1E3840A1 0;
BA_ "GenSigTimeoutTime_CVADAS" SG_ 2654486689 CBV_bit4_ActiveWakeupBit_1E3840A1 0;
BA_ "GenSigTimeoutTime_EVCU2" SG_ 2654486689 CBV_bit4_ActiveWakeupBit_1E3840A1 0;
BA_ "GenSigTimeoutTime_VDCM" SG_ 2654486689 CBV_bit4_ActiveWakeupBit_1E3840A1 0;
BA_ "GenSigTimeoutTime_BSM" SG_ 2654486689 CBV_bit4_ActiveWakeupBit_1E3840A1 0;
BA_ "GenSigTimeoutTime_ECM" SG_ 2654486689 CBV_bit4_ActiveWakeupBit_1E3840A1 0;
BA_ "GenSigTimeoutTime_EPS" SG_ 2654486689 CBV_bit4_ActiveWakeupBit_1E3840A1 0;
BA_ "GenSigTimeoutTime_ORC" SG_ 2654486689 CBV_bit4_ActiveWakeupBit_1E3840A1 0;
BA_ "GenSigTimeoutTime_ADCAM" SG_ 2654486689 CBV_bit6_PartialNtwInfBit_1E3840A1 0;
BA_ "GenSigTimeoutTime_CVADAS" SG_ 2654486689 CBV_bit6_PartialNtwInfBit_1E3840A1 0;
BA_ "GenSigTimeoutTime_EVCU2" SG_ 2654486689 CBV_bit6_PartialNtwInfBit_1E3840A1 0;
BA_ "GenSigTimeoutTime_VDCM" SG_ 2654486689 CBV_bit6_PartialNtwInfBit_1E3840A1 0;
BA_ "GenSigTimeoutTime_BSM" SG_ 2654486689 CBV_bit6_PartialNtwInfBit_1E3840A1 0;
BA_ "GenSigTimeoutTime_ECM" SG_ 2654486689 CBV_bit6_PartialNtwInfBit_1E3840A1 0;
BA_ "GenSigTimeoutTime_EPS" SG_ 2654486689 CBV_bit6_PartialNtwInfBit_1E3840A1 0;
BA_ "GenSigTimeoutTime_ORC" SG_ 2654486689 CBV_bit6_PartialNtwInfBit_1E3840A1 0;
BA_ "GenSigTimeoutTime_ADCAM" SG_ 2654486689 CBV_bit1_1E3840A1 0;
BA_ "GenSigTimeoutTime_CVADAS" SG_ 2654486689 CBV_bit1_1E3840A1 0;
BA_ "GenSigTimeoutTime_EVCU2" SG_ 2654486689 CBV_bit1_1E3840A1 0;
BA_ "GenSigTimeoutTime_VDCM" SG_ 2654486689 CBV_bit1_1E3840A1 0;
BA_ "GenSigTimeoutTime_BSM" SG_ 2654486689 CBV_bit1_1E3840A1 0;
BA_ "GenSigTimeoutTime_ECM" SG_ 2654486689 CBV_bit1_1E3840A1 0;
BA_ "GenSigTimeoutTime_EPS" SG_ 2654486689 CBV_bit1_1E3840A1 0;
BA_ "GenSigTimeoutTime_ORC" SG_ 2654486689 CBV_bit1_1E3840A1 0;
BA_ "GenSigTimeoutTime_ADCAM" SG_ 2654486689 CBV_bit2_1E3840A1 0;
BA_ "GenSigTimeoutTime_CVADAS" SG_ 2654486689 CBV_bit2_1E3840A1 0;
BA_ "GenSigTimeoutTime_EVCU2" SG_ 2654486689 CBV_bit2_1E3840A1 0;
BA_ "GenSigTimeoutTime_VDCM" SG_ 2654486689 CBV_bit2_1E3840A1 0;
BA_ "GenSigTimeoutTime_BSM" SG_ 2654486689 CBV_bit2_1E3840A1 0;
BA_ "GenSigTimeoutTime_ECM" SG_ 2654486689 CBV_bit2_1E3840A1 0;
BA_ "GenSigTimeoutTime_EPS" SG_ 2654486689 CBV_bit2_1E3840A1 0;
BA_ "GenSigTimeoutTime_ORC" SG_ 2654486689 CBV_bit2_1E3840A1 0;
BA_ "GenSigTimeoutTime_ADCAM" SG_ 2654486689 CBV_bit5_1E3840A1 0;
BA_ "GenSigTimeoutTime_CVADAS" SG_ 2654486689 CBV_bit5_1E3840A1 0;
BA_ "GenSigTimeoutTime_EVCU2" SG_ 2654486689 CBV_bit5_1E3840A1 0;
BA_ "GenSigTimeoutTime_VDCM" SG_ 2654486689 CBV_bit5_1E3840A1 0;
BA_ "GenSigTimeoutTime_BSM" SG_ 2654486689 CBV_bit5_1E3840A1 0;
BA_ "GenSigTimeoutTime_ECM" SG_ 2654486689 CBV_bit5_1E3840A1 0;
BA_ "GenSigTimeoutTime_EPS" SG_ 2654486689 CBV_bit5_1E3840A1 0;
BA_ "GenSigTimeoutTime_ORC" SG_ 2654486689 CBV_bit5_1E3840A1 0;
BA_ "GenSigTimeoutTime_ADCAM" SG_ 2654486689 CBV_bit7_1E3840A1 0;
BA_ "GenSigTimeoutTime_CVADAS" SG_ 2654486689 CBV_bit7_1E3840A1 0;
BA_ "GenSigTimeoutTime_EVCU2" SG_ 2654486689 CBV_bit7_1E3840A1 0;
BA_ "GenSigTimeoutTime_VDCM" SG_ 2654486689 CBV_bit7_1E3840A1 0;
BA_ "GenSigTimeoutTime_BSM" SG_ 2654486689 CBV_bit7_1E3840A1 0;
BA_ "GenSigTimeoutTime_ECM" SG_ 2654486689 CBV_bit7_1E3840A1 0;
BA_ "GenSigTimeoutTime_EPS" SG_ 2654486689 CBV_bit7_1E3840A1 0;
BA_ "GenSigTimeoutTime_ORC" SG_ 2654486689 CBV_bit7_1E3840A1 0;
BA_ "GenSigTimeoutTime_ADCAM" SG_ 2654486689 SourceNodeIdentifier_1E3840A1 0;
BA_ "GenSigTimeoutTime_CVADAS" SG_ 2654486689 SourceNodeIdentifier_1E3840A1 0;
BA_ "GenSigTimeoutTime_EVCU2" SG_ 2654486689 SourceNodeIdentifier_1E3840A1 0;
BA_ "GenSigTimeoutTime_VDCM" SG_ 2654486689 SourceNodeIdentifier_1E3840A1 0;
BA_ "GenSigTimeoutTime_BSM" SG_ 2654486689 SourceNodeIdentifier_1E3840A1 0;
BA_ "GenSigTimeoutTime_ECM" SG_ 2654486689 SourceNodeIdentifier_1E3840A1 0;
BA_ "GenSigTimeoutTime_EPS" SG_ 2654486689 SourceNodeIdentifier_1E3840A1 0;
BA_ "GenSigTimeoutTime_ORC" SG_ 2654486689 SourceNodeIdentifier_1E3840A1 0;
BA_ "GenSigTimeoutTime_EPS" SG_ 264 LwsAngle 0;
BA_ "GenSigTimeoutTime_ORC" SG_ 264 LwsAngle 0;
BA_ "GenSigTimeoutTime_CVADAS" SG_ 611 CRC_ORC1 0;
BA_ "GenSigTimeoutTime_VDCM" SG_ 611 CRC_ORC1 0;
BA_ "GenSigTimeoutTime_EPS" SG_ 611 CRC_ORC1 0;
BA_ "GenSigTimeoutTime_ORC" SG_ 611 CRC_ORC1 0;
BA_ "GenSigTimeoutTime_CVADAS" SG_ 611 MessageCounter_ORC1 0;
BA_ "GenSigTimeoutTime_VDCM" SG_ 611 MessageCounter_ORC1 0;
BA_ "GenSigTimeoutTime_EPS" SG_ 611 MessageCounter_ORC1 0;
BA_ "GenSigTimeoutTime_ORC" SG_ 611 MessageCounter_ORC1 0;
BA_ "GenSigTimeoutTime_ADCAM" SG_ 205 DriverRequested_AxleTrq_BSM 0;
BA_ "GenSigTimeoutTime_CVADAS" SG_ 205 DriverRequested_AxleTrq_BSM 0;
BA_ "GenSigTimeoutTime_VDCM" SG_ 205 DriverRequested_AxleTrq_BSM 0;
BA_ "GenSigTimeoutTime_ADCAM" SG_ 205 TotalAxle_Rq_BSM 0;
BA_ "GenSigTimeoutTime_CVADAS" SG_ 205 TotalAxle_Rq_BSM 0;
BA_ "GenSigTimeoutTime_EVCU2" SG_ 205 TotalAxle_Rq_BSM 0;
BA_ "GenSigTimeoutTime_VDCM" SG_ 205 TotalAxle_Rq_BSM 0;
BA_ "GenSigTimeoutTime_ADCAM" SG_ 205 DriverReq_AxleTrq_Enabled_BSM 0;
BA_ "GenSigTimeoutTime_CVADAS" SG_ 205 DriverReq_AxleTrq_Enabled_BSM 0;
BA_ "GenSigTimeoutTime_VDCM" SG_ 205 DriverReq_AxleTrq_Enabled_BSM 0;
BA_ "GenSigTimeoutTime_ADCAM" SG_ 205 TotalAxle_Max_Rq_BSM 0;
BA_ "GenSigTimeoutTime_CVADAS" SG_ 205 TotalAxle_Max_Rq_BSM 0;
BA_ "GenSigTimeoutTime_EVCU2" SG_ 205 TotalAxle_Max_Rq_BSM 0;
BA_ "GenSigTimeoutTime_VDCM" SG_ 205 TotalAxle_Max_Rq_BSM 0;
BA_ "GenSigTimeoutTime_ADCAM" SG_ 205 TotalAxle_Min_Rq_BSM 0;
BA_ "GenSigTimeoutTime_CVADAS" SG_ 205 TotalAxle_Min_Rq_BSM 0;
BA_ "GenSigTimeoutTime_EVCU2" SG_ 205 TotalAxle_Min_Rq_BSM 0;
BA_ "GenSigTimeoutTime_VDCM" SG_ 205 TotalAxle_Min_Rq_BSM 0;
BA_ "GenSigTimeoutTime_ADCAM" SG_ 205 MessageCounter_BRAKE_FD_6 0;
BA_ "GenSigTimeoutTime_CVADAS" SG_ 205 MessageCounter_BRAKE_FD_6 0;
BA_ "GenSigTimeoutTime_VDCM" SG_ 205 MessageCounter_BRAKE_FD_6 0;
BA_ "GenSigTimeoutTime_ADCAM" SG_ 205 CRC_BRAKE_FD_6 0;
BA_ "GenSigTimeoutTime_CVADAS" SG_ 205 CRC_BRAKE_FD_6 0;
BA_ "GenSigTimeoutTime_VDCM" SG_ 205 CRC_BRAKE_FD_6 0;
BA_ "GenSigStartValue" SG_ 205 DriverRequested_AxleTrq_BSM 32767;
BA_ "GenSigTimeoutTime_AHCP" SG_ 205 DriverRequested_AxleTrq_BSM 0;
BA_ "GenSigTimeoutTime_BSM" SG_ 205 DriverRequested_AxleTrq_BSM 0;
BA_ "GenSigTimeoutTime_BSM2" SG_ 205 DriverRequested_AxleTrq_BSM 0;
BA_ "GenSigTimeoutTime_CADM" SG_ 205 DriverRequested_AxleTrq_BSM 0;
BA_ "GenSigTimeoutTime_CVPAM" SG_ 205 DriverRequested_AxleTrq_BSM 0;
BA_ "GenSigTimeoutTime_EPS" SG_ 205 DriverRequested_AxleTrq_BSM 0;
BA_ "GenSigTimeoutTime_ORC" SG_ 205 DriverRequested_AxleTrq_BSM 0;
BA_ "GenSigStartValue" SG_ 205 TotalAxle_Rq_BSM 32767;
BA_ "GenSigTimeoutTime_AHCP" SG_ 205 TotalAxle_Rq_BSM 0;
BA_ "GenSigTimeoutTime_BSM" SG_ 205 TotalAxle_Rq_BSM 0;
BA_ "GenSigTimeoutTime_BSM2" SG_ 205 TotalAxle_Rq_BSM 0;
BA_ "GenSigTimeoutTime_CADM" SG_ 205 TotalAxle_Rq_BSM 0;
BA_ "GenSigTimeoutTime_CVPAM" SG_ 205 TotalAxle_Rq_BSM 0;
BA_ "GenSigTimeoutTime_EPS" SG_ 205 TotalAxle_Rq_BSM 0;
BA_ "GenSigTimeoutTime_ORC" SG_ 205 TotalAxle_Rq_BSM 0;
BA_ "GenSigTimeoutTime_AHCP" SG_ 205 DriverReq_AxleTrq_Enabled_BSM 0;
BA_ "GenSigTimeoutTime_BSM" SG_ 205 DriverReq_AxleTrq_Enabled_BSM 0;
BA_ "GenSigTimeoutTime_BSM2" SG_ 205 DriverReq_AxleTrq_Enabled_BSM 0;
BA_ "GenSigTimeoutTime_CADM" SG_ 205 DriverReq_AxleTrq_Enabled_BSM 0;
BA_ "GenSigTimeoutTime_CVPAM" SG_ 205 DriverReq_AxleTrq_Enabled_BSM 0;
BA_ "GenSigTimeoutTime_EPS" SG_ 205 DriverReq_AxleTrq_Enabled_BSM 0;
BA_ "GenSigTimeoutTime_ORC" SG_ 205 DriverReq_AxleTrq_Enabled_BSM 0;
BA_ "GenSigTimeoutTime_AHCP" SG_ 205 TotalAxle_Max_Rq_BSM 0;
BA_ "GenSigTimeoutTime_BSM" SG_ 205 TotalAxle_Max_Rq_BSM 0;
BA_ "GenSigTimeoutTime_BSM2" SG_ 205 TotalAxle_Max_Rq_BSM 0;
BA_ "GenSigTimeoutTime_CADM" SG_ 205 TotalAxle_Max_Rq_BSM 0;
BA_ "GenSigTimeoutTime_CVPAM" SG_ 205 TotalAxle_Max_Rq_BSM 0;
BA_ "GenSigTimeoutTime_EPS" SG_ 205 TotalAxle_Max_Rq_BSM 0;
BA_ "GenSigTimeoutTime_ORC" SG_ 205 TotalAxle_Max_Rq_BSM 0;
BA_ "GenSigTimeoutTime_AHCP" SG_ 205 TotalAxle_Min_Rq_BSM 0;
BA_ "GenSigTimeoutTime_BSM" SG_ 205 TotalAxle_Min_Rq_BSM 0;
BA_ "GenSigTimeoutTime_BSM2" SG_ 205 TotalAxle_Min_Rq_BSM 0;
BA_ "GenSigTimeoutTime_CADM" SG_ 205 TotalAxle_Min_Rq_BSM 0;
BA_ "GenSigTimeoutTime_CVPAM" SG_ 205 TotalAxle_Min_Rq_BSM 0;
BA_ "GenSigTimeoutTime_EPS" SG_ 205 TotalAxle_Min_Rq_BSM 0;
BA_ "GenSigTimeoutTime_ORC" SG_ 205 TotalAxle_Min_Rq_BSM 0;
BA_ "GenSigTimeoutTime_AHCP" SG_ 205 MessageCounter_BRAKE_FD_6 0;
BA_ "GenSigTimeoutTime_BSM" SG_ 205 MessageCounter_BRAKE_FD_6 0;
BA_ "GenSigTimeoutTime_BSM2" SG_ 205 MessageCounter_BRAKE_FD_6 0;
BA_ "GenSigTimeoutTime_CADM" SG_ 205 MessageCounter_BRAKE_FD_6 0;
BA_ "GenSigTimeoutTime_CVPAM" SG_ 205 MessageCounter_BRAKE_FD_6 0;
BA_ "GenSigTimeoutTime_EPS" SG_ 205 MessageCounter_BRAKE_FD_6 0;
BA_ "GenSigTimeoutTime_ORC" SG_ 205 MessageCounter_BRAKE_FD_6 0;
BA_ "GenSigTimeoutTime_AHCP" SG_ 205 CRC_BRAKE_FD_6 0;
BA_ "GenSigTimeoutTime_BSM" SG_ 205 CRC_BRAKE_FD_6 0;
BA_ "GenSigTimeoutTime_BSM2" SG_ 205 CRC_BRAKE_FD_6 0;
BA_ "GenSigTimeoutTime_CADM" SG_ 205 CRC_BRAKE_FD_6 0;
BA_ "GenSigTimeoutTime_CVPAM" SG_ 205 CRC_BRAKE_FD_6 0;
BA_ "GenSigTimeoutTime_EPS" SG_ 205 CRC_BRAKE_FD_6 0;
BA_ "GenSigTimeoutTime_ORC" SG_ 205 CRC_BRAKE_FD_6 0;
BA_ "GenSigTimeoutTime_ADCAM" SG_ 2654486554 CBV_bit0_RepeatMessageRequestBit_1E38401A 0;
BA_ "GenSigTimeoutTime_CVADAS" SG_ 2654486554 CBV_bit0_RepeatMessageRequestBit_1E38401A 0;
BA_ "GenSigTimeoutTime_EVCU2" SG_ 2654486554 CBV_bit0_RepeatMessageRequestBit_1E38401A 0;
BA_ "GenSigTimeoutTime_VDCM" SG_ 2654486554 CBV_bit0_RepeatMessageRequestBit_1E38401A 0;
BA_ "GenSigTimeoutTime_ADCAM" SG_ 2654486554 CBV_bit1_1E38401A 0;
BA_ "GenSigTimeoutTime_CVADAS" SG_ 2654486554 CBV_bit1_1E38401A 0;
BA_ "GenSigTimeoutTime_EVCU2" SG_ 2654486554 CBV_bit1_1E38401A 0;
BA_ "GenSigTimeoutTime_VDCM" SG_ 2654486554 CBV_bit1_1E38401A 0;
BA_ "GenSigTimeoutTime_ADCAM" SG_ 2654486554 CBV_bit2_1E38401A 0;
BA_ "GenSigTimeoutTime_CVADAS" SG_ 2654486554 CBV_bit2_1E38401A 0;
BA_ "GenSigTimeoutTime_EVCU2" SG_ 2654486554 CBV_bit2_1E38401A 0;
BA_ "GenSigTimeoutTime_VDCM" SG_ 2654486554 CBV_bit2_1E38401A 0;
BA_ "GenSigTimeoutTime_ADCAM" SG_ 2654486554 CBV_bit3_NMCoordinatorBit_1E38401A 0;
BA_ "GenSigTimeoutTime_CVADAS" SG_ 2654486554 CBV_bit3_NMCoordinatorBit_1E38401A 0;
BA_ "GenSigTimeoutTime_EVCU2" SG_ 2654486554 CBV_bit3_NMCoordinatorBit_1E38401A 0;
BA_ "GenSigTimeoutTime_VDCM" SG_ 2654486554 CBV_bit3_NMCoordinatorBit_1E38401A 0;
BA_ "GenSigTimeoutTime_ADCAM" SG_ 2654486554 CBV_bit4_ActiveWakeupBit_1E38401A 0;
BA_ "GenSigTimeoutTime_CVADAS" SG_ 2654486554 CBV_bit4_ActiveWakeupBit_1E38401A 0;
BA_ "GenSigTimeoutTime_EVCU2" SG_ 2654486554 CBV_bit4_ActiveWakeupBit_1E38401A 0;
BA_ "GenSigTimeoutTime_VDCM" SG_ 2654486554 CBV_bit4_ActiveWakeupBit_1E38401A 0;
BA_ "GenSigTimeoutTime_ADCAM" SG_ 2654486554 CBV_bit5_1E38401A 0;
BA_ "GenSigTimeoutTime_CVADAS" SG_ 2654486554 CBV_bit5_1E38401A 0;
BA_ "GenSigTimeoutTime_EVCU2" SG_ 2654486554 CBV_bit5_1E38401A 0;
BA_ "GenSigTimeoutTime_VDCM" SG_ 2654486554 CBV_bit5_1E38401A 0;
BA_ "GenSigTimeoutTime_ADCAM" SG_ 2654486554 CBV_bit6_PartialNtwInfBit_1E38401A 0;
BA_ "GenSigTimeoutTime_CVADAS" SG_ 2654486554 CBV_bit6_PartialNtwInfBit_1E38401A 0;
BA_ "GenSigTimeoutTime_EVCU2" SG_ 2654486554 CBV_bit6_PartialNtwInfBit_1E38401A 0;
BA_ "GenSigTimeoutTime_VDCM" SG_ 2654486554 CBV_bit6_PartialNtwInfBit_1E38401A 0;
BA_ "GenSigTimeoutTime_ADCAM" SG_ 2654486554 CBV_bit7_1E38401A 0;
BA_ "GenSigTimeoutTime_CVADAS" SG_ 2654486554 CBV_bit7_1E38401A 0;
BA_ "GenSigTimeoutTime_EVCU2" SG_ 2654486554 CBV_bit7_1E38401A 0;
BA_ "GenSigTimeoutTime_VDCM" SG_ 2654486554 CBV_bit7_1E38401A 0;
BA_ "GenSigTimeoutTime_ADCAM" SG_ 2654486554 SourceNodeIdentifier_1E38401A 0;
BA_ "GenSigTimeoutTime_CVADAS" SG_ 2654486554 SourceNodeIdentifier_1E38401A 0;
BA_ "GenSigTimeoutTime_EVCU2" SG_ 2654486554 SourceNodeIdentifier_1E38401A 0;
BA_ "GenSigTimeoutTime_VDCM" SG_ 2654486554 SourceNodeIdentifier_1E38401A 0;
BA_ "GenSigTimeoutTime_AHCP" SG_ 2654486554 CBV_bit0_RepeatMessageRequestBit_1E38401A 0;
BA_ "GenSigTimeoutTime_BSM" SG_ 2654486554 CBV_bit0_RepeatMessageRequestBit_1E38401A 0;
BA_ "GenSigTimeoutTime_BSM2" SG_ 2654486554 CBV_bit0_RepeatMessageRequestBit_1E38401A 0;
BA_ "GenSigTimeoutTime_CADM" SG_ 2654486554 CBV_bit0_RepeatMessageRequestBit_1E38401A 0;
BA_ "GenSigTimeoutTime_CVPAM" SG_ 2654486554 CBV_bit0_RepeatMessageRequestBit_1E38401A 0;
BA_ "GenSigTimeoutTime_ECM" SG_ 2654486554 CBV_bit0_RepeatMessageRequestBit_1E38401A 0;
BA_ "GenSigTimeoutTime_EPS" SG_ 2654486554 CBV_bit0_RepeatMessageRequestBit_1E38401A 0;
BA_ "GenSigTimeoutTime_ORC" SG_ 2654486554 CBV_bit0_RepeatMessageRequestBit_1E38401A 0;
BA_ "GenSigTimeoutTime_AHCP" SG_ 2654486554 CBV_bit1_1E38401A 0;
BA_ "GenSigTimeoutTime_BSM" SG_ 2654486554 CBV_bit1_1E38401A 0;
BA_ "GenSigTimeoutTime_BSM2" SG_ 2654486554 CBV_bit1_1E38401A 0;
BA_ "GenSigTimeoutTime_CADM" SG_ 2654486554 CBV_bit1_1E38401A 0;
BA_ "GenSigTimeoutTime_CVPAM" SG_ 2654486554 CBV_bit1_1E38401A 0;
BA_ "GenSigTimeoutTime_ECM" SG_ 2654486554 CBV_bit1_1E38401A 0;
BA_ "GenSigTimeoutTime_EPS" SG_ 2654486554 CBV_bit1_1E38401A 0;
BA_ "GenSigTimeoutTime_ORC" SG_ 2654486554 CBV_bit1_1E38401A 0;
BA_ "GenSigTimeoutTime_AHCP" SG_ 2654486554 CBV_bit2_1E38401A 0;
BA_ "GenSigTimeoutTime_BSM" SG_ 2654486554 CBV_bit2_1E38401A 0;
BA_ "GenSigTimeoutTime_BSM2" SG_ 2654486554 CBV_bit2_1E38401A 0;
BA_ "GenSigTimeoutTime_CADM" SG_ 2654486554 CBV_bit2_1E38401A 0;
BA_ "GenSigTimeoutTime_CVPAM" SG_ 2654486554 CBV_bit2_1E38401A 0;
BA_ "GenSigTimeoutTime_ECM" SG_ 2654486554 CBV_bit2_1E38401A 0;
BA_ "GenSigTimeoutTime_EPS" SG_ 2654486554 CBV_bit2_1E38401A 0;
BA_ "GenSigTimeoutTime_ORC" SG_ 2654486554 CBV_bit2_1E38401A 0;
BA_ "GenSigTimeoutTime_AHCP" SG_ 2654486554 CBV_bit3_NMCoordinatorBit_1E38401A 0;
BA_ "GenSigTimeoutTime_BSM" SG_ 2654486554 CBV_bit3_NMCoordinatorBit_1E38401A 0;
BA_ "GenSigTimeoutTime_BSM2" SG_ 2654486554 CBV_bit3_NMCoordinatorBit_1E38401A 0;
BA_ "GenSigTimeoutTime_CADM" SG_ 2654486554 CBV_bit3_NMCoordinatorBit_1E38401A 0;
BA_ "GenSigTimeoutTime_CVPAM" SG_ 2654486554 CBV_bit3_NMCoordinatorBit_1E38401A 0;
BA_ "GenSigTimeoutTime_ECM" SG_ 2654486554 CBV_bit3_NMCoordinatorBit_1E38401A 0;
BA_ "GenSigTimeoutTime_EPS" SG_ 2654486554 CBV_bit3_NMCoordinatorBit_1E38401A 0;
BA_ "GenSigTimeoutTime_ORC" SG_ 2654486554 CBV_bit3_NMCoordinatorBit_1E38401A 0;
BA_ "GenSigTimeoutTime_AHCP" SG_ 2654486554 CBV_bit4_ActiveWakeupBit_1E38401A 0;
BA_ "GenSigTimeoutTime_BSM" SG_ 2654486554 CBV_bit4_ActiveWakeupBit_1E38401A 0;
BA_ "GenSigTimeoutTime_BSM2" SG_ 2654486554 CBV_bit4_ActiveWakeupBit_1E38401A 0;
BA_ "GenSigTimeoutTime_CADM" SG_ 2654486554 CBV_bit4_ActiveWakeupBit_1E38401A 0;
BA_ "GenSigTimeoutTime_CVPAM" SG_ 2654486554 CBV_bit4_ActiveWakeupBit_1E38401A 0;
BA_ "GenSigTimeoutTime_ECM" SG_ 2654486554 CBV_bit4_ActiveWakeupBit_1E38401A 0;
BA_ "GenSigTimeoutTime_EPS" SG_ 2654486554 CBV_bit4_ActiveWakeupBit_1E38401A 0;
BA_ "GenSigTimeoutTime_ORC" SG_ 2654486554 CBV_bit4_ActiveWakeupBit_1E38401A 0;
BA_ "GenSigTimeoutTime_AHCP" SG_ 2654486554 CBV_bit5_1E38401A 0;
BA_ "GenSigTimeoutTime_BSM" SG_ 2654486554 CBV_bit5_1E38401A 0;
BA_ "GenSigTimeoutTime_BSM2" SG_ 2654486554 CBV_bit5_1E38401A 0;
BA_ "GenSigTimeoutTime_CADM" SG_ 2654486554 CBV_bit5_1E38401A 0;
BA_ "GenSigTimeoutTime_CVPAM" SG_ 2654486554 CBV_bit5_1E38401A 0;
BA_ "GenSigTimeoutTime_ECM" SG_ 2654486554 CBV_bit5_1E38401A 0;
BA_ "GenSigTimeoutTime_EPS" SG_ 2654486554 CBV_bit5_1E38401A 0;
BA_ "GenSigTimeoutTime_ORC" SG_ 2654486554 CBV_bit5_1E38401A 0;
BA_ "GenSigTimeoutTime_AHCP" SG_ 2654486554 CBV_bit6_PartialNtwInfBit_1E38401A 0;
BA_ "GenSigTimeoutTime_BSM" SG_ 2654486554 CBV_bit6_PartialNtwInfBit_1E38401A 0;
BA_ "GenSigTimeoutTime_BSM2" SG_ 2654486554 CBV_bit6_PartialNtwInfBit_1E38401A 0;
BA_ "GenSigTimeoutTime_CADM" SG_ 2654486554 CBV_bit6_PartialNtwInfBit_1E38401A 0;
BA_ "GenSigTimeoutTime_CVPAM" SG_ 2654486554 CBV_bit6_PartialNtwInfBit_1E38401A 0;
BA_ "GenSigTimeoutTime_ECM" SG_ 2654486554 CBV_bit6_PartialNtwInfBit_1E38401A 0;
BA_ "GenSigTimeoutTime_EPS" SG_ 2654486554 CBV_bit6_PartialNtwInfBit_1E38401A 0;
BA_ "GenSigTimeoutTime_ORC" SG_ 2654486554 CBV_bit6_PartialNtwInfBit_1E38401A 0;
BA_ "GenSigTimeoutTime_AHCP" SG_ 2654486554 CBV_bit7_1E38401A 0;
BA_ "GenSigTimeoutTime_BSM" SG_ 2654486554 CBV_bit7_1E38401A 0;
BA_ "GenSigTimeoutTime_BSM2" SG_ 2654486554 CBV_bit7_1E38401A 0;
BA_ "GenSigTimeoutTime_CADM" SG_ 2654486554 CBV_bit7_1E38401A 0;
BA_ "GenSigTimeoutTime_CVPAM" SG_ 2654486554 CBV_bit7_1E38401A 0;
BA_ "GenSigTimeoutTime_ECM" SG_ 2654486554 CBV_bit7_1E38401A 0;
BA_ "GenSigTimeoutTime_EPS" SG_ 2654486554 CBV_bit7_1E38401A 0;
BA_ "GenSigTimeoutTime_ORC" SG_ 2654486554 CBV_bit7_1E38401A 0;
BA_ "GenSigTimeoutTime_AHCP" SG_ 2654486554 SourceNodeIdentifier_1E38401A 0;
BA_ "GenSigTimeoutTime_BSM" SG_ 2654486554 SourceNodeIdentifier_1E38401A 0;
BA_ "GenSigTimeoutTime_BSM2" SG_ 2654486554 SourceNodeIdentifier_1E38401A 0;
BA_ "GenSigTimeoutTime_CADM" SG_ 2654486554 SourceNodeIdentifier_1E38401A 0;
BA_ "GenSigTimeoutTime_CVPAM" SG_ 2654486554 SourceNodeIdentifier_1E38401A 0;
BA_ "GenSigTimeoutTime_ECM" SG_ 2654486554 SourceNodeIdentifier_1E38401A 0;
BA_ "GenSigTimeoutTime_EPS" SG_ 2654486554 SourceNodeIdentifier_1E38401A 0;
BA_ "GenSigTimeoutTime_ORC" SG_ 2654486554 SourceNodeIdentifier_1E38401A 0;
BA_ "GenSigTimeoutTime_ADCAM" SG_ 280 Object_Dist 0;
BA_ "GenSigTimeoutTime_CVADAS" SG_ 280 Object_Dist 0;
BA_ "GenSigTimeoutTime_VDCM" SG_ 280 Object_Dist 0;
BA_ "GenSigStartValue" SG_ 280 Object_Dist 255;
BA_ "GenSigTimeoutTime_EPS" SG_ 280 Object_Dist 0;
BA_ "GenSigTimeoutTime_ADCAM" SG_ 280 ACC_DsrSpeedKPH 0;
BA_ "GenSigTimeoutTime_CVADAS" SG_ 280 ACC_DsrSpeedKPH 0;
BA_ "GenSigTimeoutTime_VDCM" SG_ 280 ACC_DsrSpeedKPH 0;
BA_ "GenSigStartValue" SG_ 280 ACC_DsrSpeedKPH 255;
BA_ "GenSigTimeoutTime_BSM" SG_ 280 ACC_DsrSpeedKPH 0;
BA_ "GenSigTimeoutTime_EPS" SG_ 280 ACC_DsrSpeedKPH 0;
BA_ "GenSigTimeoutTime_ORC" SG_ 280 ACC_DsrSpeedKPH 0;
BA_ "GenSigTimeoutTime_ADCAM" SG_ 280 ACC_StopStart 0;
BA_ "GenSigTimeoutTime_CVADAS" SG_ 280 ACC_StopStart 0;
BA_ "GenSigTimeoutTime_EVCU2" SG_ 280 ACC_StopStart 0;
BA_ "GenSigTimeoutTime_VDCM" SG_ 280 ACC_StopStart 0;
BA_ "GenSigTimeoutTime_AHCP" SG_ 280 ACC_StopStart 0;
BA_ "GenSigTimeoutTime_BSM" SG_ 280 ACC_StopStart 0;
BA_ "GenSigTimeoutTime_BSM2" SG_ 280 ACC_StopStart 0;
BA_ "GenSigTimeoutTime_CADM" SG_ 280 ACC_StopStart 0;
BA_ "GenSigTimeoutTime_CVPAM" SG_ 280 ACC_StopStart 0;
BA_ "GenSigTimeoutTime_EPS" SG_ 280 ACC_StopStart 0;
BA_ "GenSigTimeoutTime_ORC" SG_ 280 ACC_StopStart 0;
BA_ "GenSigTimeoutTime_AHCP" SG_ 280 ACC_Systemsts 0;
BA_ "GenSigTimeoutTime_CADM" SG_ 280 ACC_Systemsts 0;
BA_ "GenSigTimeoutTime_CVPAM" SG_ 280 ACC_Systemsts 0;
BA_ "GenSigTimeoutTime_EPS" SG_ 280 ACC_Systemsts 0;
BA_ "GenSigTimeoutTime_AHCP" SG_ 280 MRM_STATUS 0;
BA_ "GenSigTimeoutTime_BSM2" SG_ 280 MRM_STATUS 0;
BA_ "GenSigTimeoutTime_CADM" SG_ 280 MRM_STATUS 0;
BA_ "GenSigTimeoutTime_CVPAM" SG_ 280 MRM_STATUS 0;
BA_ "GenSigTimeoutTime_EPS" SG_ 280 MRM_STATUS 0;
BA_ "GenSigTimeoutTime_AHCP" SG_ 280 CRC_ADAS_FD_INFO 0;
BA_ "GenSigTimeoutTime_CADM" SG_ 280 CRC_ADAS_FD_INFO 0;
BA_ "GenSigTimeoutTime_ORC" SG_ 280 CRC_ADAS_FD_INFO 0;
BA_ "GenSigTimeoutTime_AHCP" SG_ 280 MessageCounter_ADAS_FD_INFO 0;
BA_ "GenSigTimeoutTime_CADM" SG_ 280 MessageCounter_ADAS_FD_INFO 0;
BA_ "GenSigTimeoutTime_ORC" SG_ 280 MessageCounter_ADAS_FD_INFO 0;
BA_ "GenSigTimeoutTime_AHCP" SG_ 2654486676 CBV_bit0_RepeatMessageRequestBit_1E384094 0;
BA_ "GenSigTimeoutTime_BSM" SG_ 2654486676 CBV_bit0_RepeatMessageRequestBit_1E384094 0;
BA_ "GenSigTimeoutTime_BSM2" SG_ 2654486676 CBV_bit0_RepeatMessageRequestBit_1E384094 0;
BA_ "GenSigTimeoutTime_CADM" SG_ 2654486676 CBV_bit0_RepeatMessageRequestBit_1E384094 0;
BA_ "GenSigTimeoutTime_CVPAM" SG_ 2654486676 CBV_bit0_RepeatMessageRequestBit_1E384094 0;
BA_ "GenSigTimeoutTime_ECM" SG_ 2654486676 CBV_bit0_RepeatMessageRequestBit_1E384094 0;
BA_ "GenSigTimeoutTime_EPS" SG_ 2654486676 CBV_bit0_RepeatMessageRequestBit_1E384094 0;
BA_ "GenSigTimeoutTime_ORC" SG_ 2654486676 CBV_bit0_RepeatMessageRequestBit_1E384094 0;
BA_ "GenSigTimeoutTime_AHCP" SG_ 2654486676 CBV_bit1_1E384094 0;
BA_ "GenSigTimeoutTime_BSM" SG_ 2654486676 CBV_bit1_1E384094 0;
BA_ "GenSigTimeoutTime_BSM2" SG_ 2654486676 CBV_bit1_1E384094 0;
BA_ "GenSigTimeoutTime_CADM" SG_ 2654486676 CBV_bit1_1E384094 0;
BA_ "GenSigTimeoutTime_CVPAM" SG_ 2654486676 CBV_bit1_1E384094 0;
BA_ "GenSigTimeoutTime_ECM" SG_ 2654486676 CBV_bit1_1E384094 0;
BA_ "GenSigTimeoutTime_EPS" SG_ 2654486676 CBV_bit1_1E384094 0;
BA_ "GenSigTimeoutTime_ORC" SG_ 2654486676 CBV_bit1_1E384094 0;
BA_ "GenSigTimeoutTime_AHCP" SG_ 2654486676 CBV_bit2_1E384094 0;
BA_ "GenSigTimeoutTime_BSM" SG_ 2654486676 CBV_bit2_1E384094 0;
BA_ "GenSigTimeoutTime_BSM2" SG_ 2654486676 CBV_bit2_1E384094 0;
BA_ "GenSigTimeoutTime_CADM" SG_ 2654486676 CBV_bit2_1E384094 0;
BA_ "GenSigTimeoutTime_CVPAM" SG_ 2654486676 CBV_bit2_1E384094 0;
BA_ "GenSigTimeoutTime_ECM" SG_ 2654486676 CBV_bit2_1E384094 0;
BA_ "GenSigTimeoutTime_EPS" SG_ 2654486676 CBV_bit2_1E384094 0;
BA_ "GenSigTimeoutTime_ORC" SG_ 2654486676 CBV_bit2_1E384094 0;
BA_ "GenSigTimeoutTime_AHCP" SG_ 2654486676 CBV_bit3_NMCoordinatorBit_1E384094 0;
BA_ "GenSigTimeoutTime_BSM" SG_ 2654486676 CBV_bit3_NMCoordinatorBit_1E384094 0;
BA_ "GenSigTimeoutTime_BSM2" SG_ 2654486676 CBV_bit3_NMCoordinatorBit_1E384094 0;
BA_ "GenSigTimeoutTime_CADM" SG_ 2654486676 CBV_bit3_NMCoordinatorBit_1E384094 0;
BA_ "GenSigTimeoutTime_CVPAM" SG_ 2654486676 CBV_bit3_NMCoordinatorBit_1E384094 0;
BA_ "GenSigTimeoutTime_ECM" SG_ 2654486676 CBV_bit3_NMCoordinatorBit_1E384094 0;
BA_ "GenSigTimeoutTime_EPS" SG_ 2654486676 CBV_bit3_NMCoordinatorBit_1E384094 0;
BA_ "GenSigTimeoutTime_ORC" SG_ 2654486676 CBV_bit3_NMCoordinatorBit_1E384094 0;
BA_ "GenSigTimeoutTime_AHCP" SG_ 2654486676 CBV_bit4_ActiveWakeupBit_1E384094 0;
BA_ "GenSigTimeoutTime_BSM" SG_ 2654486676 CBV_bit4_ActiveWakeupBit_1E384094 0;
BA_ "GenSigTimeoutTime_BSM2" SG_ 2654486676 CBV_bit4_ActiveWakeupBit_1E384094 0;
BA_ "GenSigTimeoutTime_CADM" SG_ 2654486676 CBV_bit4_ActiveWakeupBit_1E384094 0;
BA_ "GenSigTimeoutTime_CVPAM" SG_ 2654486676 CBV_bit4_ActiveWakeupBit_1E384094 0;
BA_ "GenSigTimeoutTime_ECM" SG_ 2654486676 CBV_bit4_ActiveWakeupBit_1E384094 0;
BA_ "GenSigTimeoutTime_EPS" SG_ 2654486676 CBV_bit4_ActiveWakeupBit_1E384094 0;
BA_ "GenSigTimeoutTime_ORC" SG_ 2654486676 CBV_bit4_ActiveWakeupBit_1E384094 0;
BA_ "GenSigTimeoutTime_AHCP" SG_ 2654486676 CBV_bit5_1E384094 0;
BA_ "GenSigTimeoutTime_BSM" SG_ 2654486676 CBV_bit5_1E384094 0;
BA_ "GenSigTimeoutTime_BSM2" SG_ 2654486676 CBV_bit5_1E384094 0;
BA_ "GenSigTimeoutTime_CADM" SG_ 2654486676 CBV_bit5_1E384094 0;
BA_ "GenSigTimeoutTime_CVPAM" SG_ 2654486676 CBV_bit5_1E384094 0;
BA_ "GenSigTimeoutTime_ECM" SG_ 2654486676 CBV_bit5_1E384094 0;
BA_ "GenSigTimeoutTime_EPS" SG_ 2654486676 CBV_bit5_1E384094 0;
BA_ "GenSigTimeoutTime_ORC" SG_ 2654486676 CBV_bit5_1E384094 0;
BA_ "GenSigTimeoutTime_AHCP" SG_ 2654486676 CBV_bit6_PartialNtwInfBit_1E384094 0;
BA_ "GenSigTimeoutTime_BSM" SG_ 2654486676 CBV_bit6_PartialNtwInfBit_1E384094 0;
BA_ "GenSigTimeoutTime_BSM2" SG_ 2654486676 CBV_bit6_PartialNtwInfBit_1E384094 0;
BA_ "GenSigTimeoutTime_CADM" SG_ 2654486676 CBV_bit6_PartialNtwInfBit_1E384094 0;
BA_ "GenSigTimeoutTime_CVPAM" SG_ 2654486676 CBV_bit6_PartialNtwInfBit_1E384094 0;
BA_ "GenSigTimeoutTime_ECM" SG_ 2654486676 CBV_bit6_PartialNtwInfBit_1E384094 0;
BA_ "GenSigTimeoutTime_EPS" SG_ 2654486676 CBV_bit6_PartialNtwInfBit_1E384094 0;
BA_ "GenSigTimeoutTime_ORC" SG_ 2654486676 CBV_bit6_PartialNtwInfBit_1E384094 0;
BA_ "GenSigTimeoutTime_AHCP" SG_ 2654486676 CBV_bit7_1E384094 0;
BA_ "GenSigTimeoutTime_BSM" SG_ 2654486676 CBV_bit7_1E384094 0;
BA_ "GenSigTimeoutTime_BSM2" SG_ 2654486676 CBV_bit7_1E384094 0;
BA_ "GenSigTimeoutTime_CADM" SG_ 2654486676 CBV_bit7_1E384094 0;
BA_ "GenSigTimeoutTime_CVPAM" SG_ 2654486676 CBV_bit7_1E384094 0;
BA_ "GenSigTimeoutTime_ECM" SG_ 2654486676 CBV_bit7_1E384094 0;
BA_ "GenSigTimeoutTime_EPS" SG_ 2654486676 CBV_bit7_1E384094 0;
BA_ "GenSigTimeoutTime_ORC" SG_ 2654486676 CBV_bit7_1E384094 0;
BA_ "GenSigTimeoutTime_AHCP" SG_ 2654486676 SourceNodeIdentifier_1E384094 0;
BA_ "GenSigTimeoutTime_BSM" SG_ 2654486676 SourceNodeIdentifier_1E384094 0;
BA_ "GenSigTimeoutTime_BSM2" SG_ 2654486676 SourceNodeIdentifier_1E384094 0;
BA_ "GenSigTimeoutTime_CADM" SG_ 2654486676 SourceNodeIdentifier_1E384094 0;
BA_ "GenSigTimeoutTime_CVPAM" SG_ 2654486676 SourceNodeIdentifier_1E384094 0;
BA_ "GenSigTimeoutTime_ECM" SG_ 2654486676 SourceNodeIdentifier_1E384094 0;
BA_ "GenSigTimeoutTime_EPS" SG_ 2654486676 SourceNodeIdentifier_1E384094 0;
BA_ "GenSigTimeoutTime_ORC" SG_ 2654486676 SourceNodeIdentifier_1E384094 0;
BA_ "GenSigTimeoutTime_ADCAM" SG_ 2654486552 CBV_bit0_RepeatMessageRequestBit_1E384018 0;
BA_ "GenSigTimeoutTime_CVADAS" SG_ 2654486552 CBV_bit0_RepeatMessageRequestBit_1E384018 0;
BA_ "GenSigTimeoutTime_EVCU2" SG_ 2654486552 CBV_bit0_RepeatMessageRequestBit_1E384018 0;
BA_ "GenSigTimeoutTime_VDCM" SG_ 2654486552 CBV_bit0_RepeatMessageRequestBit_1E384018 0;
BA_ "GenSigTimeoutTime_ADCAM" SG_ 2654486552 CBV_bit1_1E384018 0;
BA_ "GenSigTimeoutTime_CVADAS" SG_ 2654486552 CBV_bit1_1E384018 0;
BA_ "GenSigTimeoutTime_EVCU2" SG_ 2654486552 CBV_bit1_1E384018 0;
BA_ "GenSigTimeoutTime_VDCM" SG_ 2654486552 CBV_bit1_1E384018 0;
BA_ "GenSigTimeoutTime_ADCAM" SG_ 2654486552 CBV_bit2_1E384018 0;
BA_ "GenSigTimeoutTime_CVADAS" SG_ 2654486552 CBV_bit2_1E384018 0;
BA_ "GenSigTimeoutTime_EVCU2" SG_ 2654486552 CBV_bit2_1E384018 0;
BA_ "GenSigTimeoutTime_VDCM" SG_ 2654486552 CBV_bit2_1E384018 0;
BA_ "GenSigTimeoutTime_ADCAM" SG_ 2654486552 CBV_bit3_NMCoordinatorBit_1E384018 0;
BA_ "GenSigTimeoutTime_CVADAS" SG_ 2654486552 CBV_bit3_NMCoordinatorBit_1E384018 0;
BA_ "GenSigTimeoutTime_EVCU2" SG_ 2654486552 CBV_bit3_NMCoordinatorBit_1E384018 0;
BA_ "GenSigTimeoutTime_VDCM" SG_ 2654486552 CBV_bit3_NMCoordinatorBit_1E384018 0;
BA_ "GenSigTimeoutTime_ADCAM" SG_ 2654486552 CBV_bit4_ActiveWakeupBit_1E384018 0;
BA_ "GenSigTimeoutTime_CVADAS" SG_ 2654486552 CBV_bit4_ActiveWakeupBit_1E384018 0;
BA_ "GenSigTimeoutTime_EVCU2" SG_ 2654486552 CBV_bit4_ActiveWakeupBit_1E384018 0;
BA_ "GenSigTimeoutTime_VDCM" SG_ 2654486552 CBV_bit4_ActiveWakeupBit_1E384018 0;
BA_ "GenSigTimeoutTime_ADCAM" SG_ 2654486552 CBV_bit5_1E384018 0;
BA_ "GenSigTimeoutTime_CVADAS" SG_ 2654486552 CBV_bit5_1E384018 0;
BA_ "GenSigTimeoutTime_EVCU2" SG_ 2654486552 CBV_bit5_1E384018 0;
BA_ "GenSigTimeoutTime_VDCM" SG_ 2654486552 CBV_bit5_1E384018 0;
BA_ "GenSigTimeoutTime_ADCAM" SG_ 2654486552 CBV_bit6_PartialNtwInfBit_1E384018 0;
BA_ "GenSigTimeoutTime_CVADAS" SG_ 2654486552 CBV_bit6_PartialNtwInfBit_1E384018 0;
BA_ "GenSigTimeoutTime_EVCU2" SG_ 2654486552 CBV_bit6_PartialNtwInfBit_1E384018 0;
BA_ "GenSigTimeoutTime_VDCM" SG_ 2654486552 CBV_bit6_PartialNtwInfBit_1E384018 0;
BA_ "GenSigTimeoutTime_ADCAM" SG_ 2654486552 CBV_bit7_1E384018 0;
BA_ "GenSigTimeoutTime_CVADAS" SG_ 2654486552 CBV_bit7_1E384018 0;
BA_ "GenSigTimeoutTime_EVCU2" SG_ 2654486552 CBV_bit7_1E384018 0;
BA_ "GenSigTimeoutTime_VDCM" SG_ 2654486552 CBV_bit7_1E384018 0;
BA_ "GenSigTimeoutTime_ADCAM" SG_ 2654486552 SourceNodeIdentifier_1E384018 0;
BA_ "GenSigTimeoutTime_CVADAS" SG_ 2654486552 SourceNodeIdentifier_1E384018 0;
BA_ "GenSigTimeoutTime_EVCU2" SG_ 2654486552 SourceNodeIdentifier_1E384018 0;
BA_ "GenSigTimeoutTime_VDCM" SG_ 2654486552 SourceNodeIdentifier_1E384018 0;
BA_ "GenSigTimeoutTime_AHCP" SG_ 2654486552 CBV_bit0_RepeatMessageRequestBit_1E384018 0;
BA_ "GenSigTimeoutTime_BSM" SG_ 2654486552 CBV_bit0_RepeatMessageRequestBit_1E384018 0;
BA_ "GenSigTimeoutTime_BSM2" SG_ 2654486552 CBV_bit0_RepeatMessageRequestBit_1E384018 0;
BA_ "GenSigTimeoutTime_CADM" SG_ 2654486552 CBV_bit0_RepeatMessageRequestBit_1E384018 0;
BA_ "GenSigTimeoutTime_CVPAM" SG_ 2654486552 CBV_bit0_RepeatMessageRequestBit_1E384018 0;
BA_ "GenSigTimeoutTime_ECM" SG_ 2654486552 CBV_bit0_RepeatMessageRequestBit_1E384018 0;
BA_ "GenSigTimeoutTime_EPS" SG_ 2654486552 CBV_bit0_RepeatMessageRequestBit_1E384018 0;
BA_ "GenSigTimeoutTime_ORC" SG_ 2654486552 CBV_bit0_RepeatMessageRequestBit_1E384018 0;
BA_ "GenSigTimeoutTime_AHCP" SG_ 2654486552 CBV_bit1_1E384018 0;
BA_ "GenSigTimeoutTime_BSM" SG_ 2654486552 CBV_bit1_1E384018 0;
BA_ "GenSigTimeoutTime_BSM2" SG_ 2654486552 CBV_bit1_1E384018 0;
BA_ "GenSigTimeoutTime_CADM" SG_ 2654486552 CBV_bit1_1E384018 0;
BA_ "GenSigTimeoutTime_CVPAM" SG_ 2654486552 CBV_bit1_1E384018 0;
BA_ "GenSigTimeoutTime_ECM" SG_ 2654486552 CBV_bit1_1E384018 0;
BA_ "GenSigTimeoutTime_EPS" SG_ 2654486552 CBV_bit1_1E384018 0;
BA_ "GenSigTimeoutTime_ORC" SG_ 2654486552 CBV_bit1_1E384018 0;
BA_ "GenSigTimeoutTime_AHCP" SG_ 2654486552 CBV_bit2_1E384018 0;
BA_ "GenSigTimeoutTime_BSM" SG_ 2654486552 CBV_bit2_1E384018 0;
BA_ "GenSigTimeoutTime_BSM2" SG_ 2654486552 CBV_bit2_1E384018 0;
BA_ "GenSigTimeoutTime_CADM" SG_ 2654486552 CBV_bit2_1E384018 0;
BA_ "GenSigTimeoutTime_CVPAM" SG_ 2654486552 CBV_bit2_1E384018 0;
BA_ "GenSigTimeoutTime_ECM" SG_ 2654486552 CBV_bit2_1E384018 0;
BA_ "GenSigTimeoutTime_EPS" SG_ 2654486552 CBV_bit2_1E384018 0;
BA_ "GenSigTimeoutTime_ORC" SG_ 2654486552 CBV_bit2_1E384018 0;
BA_ "GenSigTimeoutTime_AHCP" SG_ 2654486552 CBV_bit3_NMCoordinatorBit_1E384018 0;
BA_ "GenSigTimeoutTime_BSM" SG_ 2654486552 CBV_bit3_NMCoordinatorBit_1E384018 0;
BA_ "GenSigTimeoutTime_BSM2" SG_ 2654486552 CBV_bit3_NMCoordinatorBit_1E384018 0;
BA_ "GenSigTimeoutTime_CADM" SG_ 2654486552 CBV_bit3_NMCoordinatorBit_1E384018 0;
BA_ "GenSigTimeoutTime_CVPAM" SG_ 2654486552 CBV_bit3_NMCoordinatorBit_1E384018 0;
BA_ "GenSigTimeoutTime_ECM" SG_ 2654486552 CBV_bit3_NMCoordinatorBit_1E384018 0;
BA_ "GenSigTimeoutTime_EPS" SG_ 2654486552 CBV_bit3_NMCoordinatorBit_1E384018 0;
BA_ "GenSigTimeoutTime_ORC" SG_ 2654486552 CBV_bit3_NMCoordinatorBit_1E384018 0;
BA_ "GenSigTimeoutTime_AHCP" SG_ 2654486552 CBV_bit4_ActiveWakeupBit_1E384018 0;
BA_ "GenSigTimeoutTime_BSM" SG_ 2654486552 CBV_bit4_ActiveWakeupBit_1E384018 0;
BA_ "GenSigTimeoutTime_BSM2" SG_ 2654486552 CBV_bit4_ActiveWakeupBit_1E384018 0;
BA_ "GenSigTimeoutTime_CADM" SG_ 2654486552 CBV_bit4_ActiveWakeupBit_1E384018 0;
BA_ "GenSigTimeoutTime_CVPAM" SG_ 2654486552 CBV_bit4_ActiveWakeupBit_1E384018 0;
BA_ "GenSigTimeoutTime_ECM" SG_ 2654486552 CBV_bit4_ActiveWakeupBit_1E384018 0;
BA_ "GenSigTimeoutTime_EPS" SG_ 2654486552 CBV_bit4_ActiveWakeupBit_1E384018 0;
BA_ "GenSigTimeoutTime_ORC" SG_ 2654486552 CBV_bit4_ActiveWakeupBit_1E384018 0;
BA_ "GenSigTimeoutTime_AHCP" SG_ 2654486552 CBV_bit5_1E384018 0;
BA_ "GenSigTimeoutTime_BSM" SG_ 2654486552 CBV_bit5_1E384018 0;
BA_ "GenSigTimeoutTime_BSM2" SG_ 2654486552 CBV_bit5_1E384018 0;
BA_ "GenSigTimeoutTime_CADM" SG_ 2654486552 CBV_bit5_1E384018 0;
BA_ "GenSigTimeoutTime_CVPAM" SG_ 2654486552 CBV_bit5_1E384018 0;
BA_ "GenSigTimeoutTime_ECM" SG_ 2654486552 CBV_bit5_1E384018 0;
BA_ "GenSigTimeoutTime_EPS" SG_ 2654486552 CBV_bit5_1E384018 0;
BA_ "GenSigTimeoutTime_ORC" SG_ 2654486552 CBV_bit5_1E384018 0;
BA_ "GenSigTimeoutTime_AHCP" SG_ 2654486552 CBV_bit6_PartialNtwInfBit_1E384018 0;
BA_ "GenSigTimeoutTime_BSM" SG_ 2654486552 CBV_bit6_PartialNtwInfBit_1E384018 0;
BA_ "GenSigTimeoutTime_BSM2" SG_ 2654486552 CBV_bit6_PartialNtwInfBit_1E384018 0;
BA_ "GenSigTimeoutTime_CADM" SG_ 2654486552 CBV_bit6_PartialNtwInfBit_1E384018 0;
BA_ "GenSigTimeoutTime_CVPAM" SG_ 2654486552 CBV_bit6_PartialNtwInfBit_1E384018 0;
BA_ "GenSigTimeoutTime_ECM" SG_ 2654486552 CBV_bit6_PartialNtwInfBit_1E384018 0;
BA_ "GenSigTimeoutTime_EPS" SG_ 2654486552 CBV_bit6_PartialNtwInfBit_1E384018 0;
BA_ "GenSigTimeoutTime_ORC" SG_ 2654486552 CBV_bit6_PartialNtwInfBit_1E384018 0;
BA_ "GenSigTimeoutTime_AHCP" SG_ 2654486552 CBV_bit7_1E384018 0;
BA_ "GenSigTimeoutTime_BSM" SG_ 2654486552 CBV_bit7_1E384018 0;
BA_ "GenSigTimeoutTime_BSM2" SG_ 2654486552 CBV_bit7_1E384018 0;
BA_ "GenSigTimeoutTime_CADM" SG_ 2654486552 CBV_bit7_1E384018 0;
BA_ "GenSigTimeoutTime_CVPAM" SG_ 2654486552 CBV_bit7_1E384018 0;
BA_ "GenSigTimeoutTime_ECM" SG_ 2654486552 CBV_bit7_1E384018 0;
BA_ "GenSigTimeoutTime_EPS" SG_ 2654486552 CBV_bit7_1E384018 0;
BA_ "GenSigTimeoutTime_ORC" SG_ 2654486552 CBV_bit7_1E384018 0;
BA_ "GenSigTimeoutTime_AHCP" SG_ 2654486552 SourceNodeIdentifier_1E384018 0;
BA_ "GenSigTimeoutTime_BSM" SG_ 2654486552 SourceNodeIdentifier_1E384018 0;
BA_ "GenSigTimeoutTime_BSM2" SG_ 2654486552 SourceNodeIdentifier_1E384018 0;
BA_ "GenSigTimeoutTime_CADM" SG_ 2654486552 SourceNodeIdentifier_1E384018 0;
BA_ "GenSigTimeoutTime_CVPAM" SG_ 2654486552 SourceNodeIdentifier_1E384018 0;
BA_ "GenSigTimeoutTime_ECM" SG_ 2654486552 SourceNodeIdentifier_1E384018 0;
BA_ "GenSigTimeoutTime_EPS" SG_ 2654486552 SourceNodeIdentifier_1E384018 0;
BA_ "GenSigTimeoutTime_ORC" SG_ 2654486552 SourceNodeIdentifier_1E384018 0;
BA_ "GenSigTimeoutTime_ADCAM" SG_ 2654486530 CBV_bit0_RepeatMessageRequestBit_1E384002 0;
BA_ "GenSigTimeoutTime_CVADAS" SG_ 2654486530 CBV_bit0_RepeatMessageRequestBit_1E384002 0;
BA_ "GenSigTimeoutTime_EVCU2" SG_ 2654486530 CBV_bit0_RepeatMessageRequestBit_1E384002 0;
BA_ "GenSigTimeoutTime_VDCM" SG_ 2654486530 CBV_bit0_RepeatMessageRequestBit_1E384002 0;
BA_ "GenSigTimeoutTime_ADCAM" SG_ 2654486530 CBV_bit1_1E384002 0;
BA_ "GenSigTimeoutTime_CVADAS" SG_ 2654486530 CBV_bit1_1E384002 0;
BA_ "GenSigTimeoutTime_EVCU2" SG_ 2654486530 CBV_bit1_1E384002 0;
BA_ "GenSigTimeoutTime_VDCM" SG_ 2654486530 CBV_bit1_1E384002 0;
BA_ "GenSigTimeoutTime_ADCAM" SG_ 2654486530 CBV_bit2_1E384002 0;
BA_ "GenSigTimeoutTime_CVADAS" SG_ 2654486530 CBV_bit2_1E384002 0;
BA_ "GenSigTimeoutTime_EVCU2" SG_ 2654486530 CBV_bit2_1E384002 0;
BA_ "GenSigTimeoutTime_VDCM" SG_ 2654486530 CBV_bit2_1E384002 0;
BA_ "GenSigTimeoutTime_ADCAM" SG_ 2654486530 CBV_bit3_NMCoordinatorBit_1E384002 0;
BA_ "GenSigTimeoutTime_CVADAS" SG_ 2654486530 CBV_bit3_NMCoordinatorBit_1E384002 0;
BA_ "GenSigTimeoutTime_EVCU2" SG_ 2654486530 CBV_bit3_NMCoordinatorBit_1E384002 0;
BA_ "GenSigTimeoutTime_VDCM" SG_ 2654486530 CBV_bit3_NMCoordinatorBit_1E384002 0;
BA_ "GenSigTimeoutTime_ADCAM" SG_ 2654486530 CBV_bit4_ActiveWakeupBit_1E384002 0;
BA_ "GenSigTimeoutTime_CVADAS" SG_ 2654486530 CBV_bit4_ActiveWakeupBit_1E384002 0;
BA_ "GenSigTimeoutTime_EVCU2" SG_ 2654486530 CBV_bit4_ActiveWakeupBit_1E384002 0;
BA_ "GenSigTimeoutTime_VDCM" SG_ 2654486530 CBV_bit4_ActiveWakeupBit_1E384002 0;
BA_ "GenSigTimeoutTime_ADCAM" SG_ 2654486530 CBV_bit5_1E384002 0;
BA_ "GenSigTimeoutTime_CVADAS" SG_ 2654486530 CBV_bit5_1E384002 0;
BA_ "GenSigTimeoutTime_EVCU2" SG_ 2654486530 CBV_bit5_1E384002 0;
BA_ "GenSigTimeoutTime_VDCM" SG_ 2654486530 CBV_bit5_1E384002 0;
BA_ "GenSigTimeoutTime_ADCAM" SG_ 2654486530 CBV_bit6_PartialNtwInfBit_1E384002 0;
BA_ "GenSigTimeoutTime_CVADAS" SG_ 2654486530 CBV_bit6_PartialNtwInfBit_1E384002 0;
BA_ "GenSigTimeoutTime_EVCU2" SG_ 2654486530 CBV_bit6_PartialNtwInfBit_1E384002 0;
BA_ "GenSigTimeoutTime_VDCM" SG_ 2654486530 CBV_bit6_PartialNtwInfBit_1E384002 0;
BA_ "GenSigTimeoutTime_ADCAM" SG_ 2654486530 CBV_bit7_1E384002 0;
BA_ "GenSigTimeoutTime_CVADAS" SG_ 2654486530 CBV_bit7_1E384002 0;
BA_ "GenSigTimeoutTime_EVCU2" SG_ 2654486530 CBV_bit7_1E384002 0;
BA_ "GenSigTimeoutTime_VDCM" SG_ 2654486530 CBV_bit7_1E384002 0;
BA_ "GenSigTimeoutTime_ADCAM" SG_ 2654486530 SourceNodeIdentifier_1E384002 0;
BA_ "GenSigTimeoutTime_CVADAS" SG_ 2654486530 SourceNodeIdentifier_1E384002 0;
BA_ "GenSigTimeoutTime_EVCU2" SG_ 2654486530 SourceNodeIdentifier_1E384002 0;
BA_ "GenSigTimeoutTime_VDCM" SG_ 2654486530 SourceNodeIdentifier_1E384002 0;
BA_ "GenSigTimeoutTime_AHCP" SG_ 2654486530 CBV_bit0_RepeatMessageRequestBit_1E384002 0;
BA_ "GenSigTimeoutTime_BSM" SG_ 2654486530 CBV_bit0_RepeatMessageRequestBit_1E384002 0;
BA_ "GenSigTimeoutTime_BSM2" SG_ 2654486530 CBV_bit0_RepeatMessageRequestBit_1E384002 0;
BA_ "GenSigTimeoutTime_CADM" SG_ 2654486530 CBV_bit0_RepeatMessageRequestBit_1E384002 0;
BA_ "GenSigTimeoutTime_CVPAM" SG_ 2654486530 CBV_bit0_RepeatMessageRequestBit_1E384002 0;
BA_ "GenSigTimeoutTime_ECM" SG_ 2654486530 CBV_bit0_RepeatMessageRequestBit_1E384002 0;
BA_ "GenSigTimeoutTime_EPS" SG_ 2654486530 CBV_bit0_RepeatMessageRequestBit_1E384002 0;
BA_ "GenSigTimeoutTime_ORC" SG_ 2654486530 CBV_bit0_RepeatMessageRequestBit_1E384002 0;
BA_ "GenSigTimeoutTime_AHCP" SG_ 2654486530 CBV_bit1_1E384002 0;
BA_ "GenSigTimeoutTime_BSM" SG_ 2654486530 CBV_bit1_1E384002 0;
BA_ "GenSigTimeoutTime_BSM2" SG_ 2654486530 CBV_bit1_1E384002 0;
BA_ "GenSigTimeoutTime_CADM" SG_ 2654486530 CBV_bit1_1E384002 0;
BA_ "GenSigTimeoutTime_CVPAM" SG_ 2654486530 CBV_bit1_1E384002 0;
BA_ "GenSigTimeoutTime_ECM" SG_ 2654486530 CBV_bit1_1E384002 0;
BA_ "GenSigTimeoutTime_EPS" SG_ 2654486530 CBV_bit1_1E384002 0;
BA_ "GenSigTimeoutTime_ORC" SG_ 2654486530 CBV_bit1_1E384002 0;
BA_ "GenSigTimeoutTime_AHCP" SG_ 2654486530 CBV_bit2_1E384002 0;
BA_ "GenSigTimeoutTime_BSM" SG_ 2654486530 CBV_bit2_1E384002 0;
BA_ "GenSigTimeoutTime_BSM2" SG_ 2654486530 CBV_bit2_1E384002 0;
BA_ "GenSigTimeoutTime_CADM" SG_ 2654486530 CBV_bit2_1E384002 0;
BA_ "GenSigTimeoutTime_CVPAM" SG_ 2654486530 CBV_bit2_1E384002 0;
BA_ "GenSigTimeoutTime_ECM" SG_ 2654486530 CBV_bit2_1E384002 0;
BA_ "GenSigTimeoutTime_EPS" SG_ 2654486530 CBV_bit2_1E384002 0;
BA_ "GenSigTimeoutTime_ORC" SG_ 2654486530 CBV_bit2_1E384002 0;
BA_ "GenSigTimeoutTime_AHCP" SG_ 2654486530 CBV_bit3_NMCoordinatorBit_1E384002 0;
BA_ "GenSigTimeoutTime_BSM" SG_ 2654486530 CBV_bit3_NMCoordinatorBit_1E384002 0;
BA_ "GenSigTimeoutTime_BSM2" SG_ 2654486530 CBV_bit3_NMCoordinatorBit_1E384002 0;
BA_ "GenSigTimeoutTime_CADM" SG_ 2654486530 CBV_bit3_NMCoordinatorBit_1E384002 0;
BA_ "GenSigTimeoutTime_CVPAM" SG_ 2654486530 CBV_bit3_NMCoordinatorBit_1E384002 0;
BA_ "GenSigTimeoutTime_ECM" SG_ 2654486530 CBV_bit3_NMCoordinatorBit_1E384002 0;
BA_ "GenSigTimeoutTime_EPS" SG_ 2654486530 CBV_bit3_NMCoordinatorBit_1E384002 0;
BA_ "GenSigTimeoutTime_ORC" SG_ 2654486530 CBV_bit3_NMCoordinatorBit_1E384002 0;
BA_ "GenSigTimeoutTime_AHCP" SG_ 2654486530 CBV_bit4_ActiveWakeupBit_1E384002 0;
BA_ "GenSigTimeoutTime_BSM" SG_ 2654486530 CBV_bit4_ActiveWakeupBit_1E384002 0;
BA_ "GenSigTimeoutTime_BSM2" SG_ 2654486530 CBV_bit4_ActiveWakeupBit_1E384002 0;
BA_ "GenSigTimeoutTime_CADM" SG_ 2654486530 CBV_bit4_ActiveWakeupBit_1E384002 0;
BA_ "GenSigTimeoutTime_CVPAM" SG_ 2654486530 CBV_bit4_ActiveWakeupBit_1E384002 0;
BA_ "GenSigTimeoutTime_ECM" SG_ 2654486530 CBV_bit4_ActiveWakeupBit_1E384002 0;
BA_ "GenSigTimeoutTime_EPS" SG_ 2654486530 CBV_bit4_ActiveWakeupBit_1E384002 0;
BA_ "GenSigTimeoutTime_ORC" SG_ 2654486530 CBV_bit4_ActiveWakeupBit_1E384002 0;
BA_ "GenSigTimeoutTime_AHCP" SG_ 2654486530 CBV_bit5_1E384002 0;
BA_ "GenSigTimeoutTime_BSM" SG_ 2654486530 CBV_bit5_1E384002 0;
BA_ "GenSigTimeoutTime_BSM2" SG_ 2654486530 CBV_bit5_1E384002 0;
BA_ "GenSigTimeoutTime_CADM" SG_ 2654486530 CBV_bit5_1E384002 0;
BA_ "GenSigTimeoutTime_CVPAM" SG_ 2654486530 CBV_bit5_1E384002 0;
BA_ "GenSigTimeoutTime_ECM" SG_ 2654486530 CBV_bit5_1E384002 0;
BA_ "GenSigTimeoutTime_EPS" SG_ 2654486530 CBV_bit5_1E384002 0;
BA_ "GenSigTimeoutTime_ORC" SG_ 2654486530 CBV_bit5_1E384002 0;
BA_ "GenSigTimeoutTime_AHCP" SG_ 2654486530 CBV_bit6_PartialNtwInfBit_1E384002 0;
BA_ "GenSigTimeoutTime_BSM" SG_ 2654486530 CBV_bit6_PartialNtwInfBit_1E384002 0;
BA_ "GenSigTimeoutTime_BSM2" SG_ 2654486530 CBV_bit6_PartialNtwInfBit_1E384002 0;
BA_ "GenSigTimeoutTime_CADM" SG_ 2654486530 CBV_bit6_PartialNtwInfBit_1E384002 0;
BA_ "GenSigTimeoutTime_CVPAM" SG_ 2654486530 CBV_bit6_PartialNtwInfBit_1E384002 0;
BA_ "GenSigTimeoutTime_ECM" SG_ 2654486530 CBV_bit6_PartialNtwInfBit_1E384002 0;
BA_ "GenSigTimeoutTime_EPS" SG_ 2654486530 CBV_bit6_PartialNtwInfBit_1E384002 0;
BA_ "GenSigTimeoutTime_ORC" SG_ 2654486530 CBV_bit6_PartialNtwInfBit_1E384002 0;
BA_ "GenSigTimeoutTime_AHCP" SG_ 2654486530 CBV_bit7_1E384002 0;
BA_ "GenSigTimeoutTime_BSM" SG_ 2654486530 CBV_bit7_1E384002 0;
BA_ "GenSigTimeoutTime_BSM2" SG_ 2654486530 CBV_bit7_1E384002 0;
BA_ "GenSigTimeoutTime_CADM" SG_ 2654486530 CBV_bit7_1E384002 0;
BA_ "GenSigTimeoutTime_CVPAM" SG_ 2654486530 CBV_bit7_1E384002 0;
BA_ "GenSigTimeoutTime_ECM" SG_ 2654486530 CBV_bit7_1E384002 0;
BA_ "GenSigTimeoutTime_EPS" SG_ 2654486530 CBV_bit7_1E384002 0;
BA_ "GenSigTimeoutTime_ORC" SG_ 2654486530 CBV_bit7_1E384002 0;
BA_ "GenSigTimeoutTime_AHCP" SG_ 2654486530 SourceNodeIdentifier_1E384002 0;
BA_ "GenSigTimeoutTime_BSM" SG_ 2654486530 SourceNodeIdentifier_1E384002 0;
BA_ "GenSigTimeoutTime_BSM2" SG_ 2654486530 SourceNodeIdentifier_1E384002 0;
BA_ "GenSigTimeoutTime_CADM" SG_ 2654486530 SourceNodeIdentifier_1E384002 0;
BA_ "GenSigTimeoutTime_CVPAM" SG_ 2654486530 SourceNodeIdentifier_1E384002 0;
BA_ "GenSigTimeoutTime_ECM" SG_ 2654486530 SourceNodeIdentifier_1E384002 0;
BA_ "GenSigTimeoutTime_EPS" SG_ 2654486530 SourceNodeIdentifier_1E384002 0;
BA_ "GenSigTimeoutTime_ORC" SG_ 2654486530 SourceNodeIdentifier_1E384002 0;
BA_ "GenSigTimeoutTime_AHCP" SG_ 2654486614 CBV_bit0_RepeatMessageRequestBit_1E384056 0;
BA_ "GenSigTimeoutTime_BSM" SG_ 2654486614 CBV_bit0_RepeatMessageRequestBit_1E384056 0;
BA_ "GenSigTimeoutTime_BSM2" SG_ 2654486614 CBV_bit0_RepeatMessageRequestBit_1E384056 0;
BA_ "GenSigTimeoutTime_CADM" SG_ 2654486614 CBV_bit0_RepeatMessageRequestBit_1E384056 0;
BA_ "GenSigTimeoutTime_CVPAM" SG_ 2654486614 CBV_bit0_RepeatMessageRequestBit_1E384056 0;
BA_ "GenSigTimeoutTime_ECM" SG_ 2654486614 CBV_bit0_RepeatMessageRequestBit_1E384056 0;
BA_ "GenSigTimeoutTime_EPS" SG_ 2654486614 CBV_bit0_RepeatMessageRequestBit_1E384056 0;
BA_ "GenSigTimeoutTime_ORC" SG_ 2654486614 CBV_bit0_RepeatMessageRequestBit_1E384056 0;
BA_ "GenSigTimeoutTime_AHCP" SG_ 2654486614 CBV_bit1_1E384056 0;
BA_ "GenSigTimeoutTime_BSM" SG_ 2654486614 CBV_bit1_1E384056 0;
BA_ "GenSigTimeoutTime_BSM2" SG_ 2654486614 CBV_bit1_1E384056 0;
BA_ "GenSigTimeoutTime_CADM" SG_ 2654486614 CBV_bit1_1E384056 0;
BA_ "GenSigTimeoutTime_CVPAM" SG_ 2654486614 CBV_bit1_1E384056 0;
BA_ "GenSigTimeoutTime_ECM" SG_ 2654486614 CBV_bit1_1E384056 0;
BA_ "GenSigTimeoutTime_EPS" SG_ 2654486614 CBV_bit1_1E384056 0;
BA_ "GenSigTimeoutTime_ORC" SG_ 2654486614 CBV_bit1_1E384056 0;
BA_ "GenSigTimeoutTime_AHCP" SG_ 2654486614 CBV_bit2_1E384056 0;
BA_ "GenSigTimeoutTime_BSM" SG_ 2654486614 CBV_bit2_1E384056 0;
BA_ "GenSigTimeoutTime_BSM2" SG_ 2654486614 CBV_bit2_1E384056 0;
BA_ "GenSigTimeoutTime_CADM" SG_ 2654486614 CBV_bit2_1E384056 0;
BA_ "GenSigTimeoutTime_CVPAM" SG_ 2654486614 CBV_bit2_1E384056 0;
BA_ "GenSigTimeoutTime_ECM" SG_ 2654486614 CBV_bit2_1E384056 0;
BA_ "GenSigTimeoutTime_EPS" SG_ 2654486614 CBV_bit2_1E384056 0;
BA_ "GenSigTimeoutTime_ORC" SG_ 2654486614 CBV_bit2_1E384056 0;
BA_ "GenSigTimeoutTime_AHCP" SG_ 2654486614 CBV_bit3_NMCoordinatorBit_1E384056 0;
BA_ "GenSigTimeoutTime_BSM" SG_ 2654486614 CBV_bit3_NMCoordinatorBit_1E384056 0;
BA_ "GenSigTimeoutTime_BSM2" SG_ 2654486614 CBV_bit3_NMCoordinatorBit_1E384056 0;
BA_ "GenSigTimeoutTime_CADM" SG_ 2654486614 CBV_bit3_NMCoordinatorBit_1E384056 0;
BA_ "GenSigTimeoutTime_CVPAM" SG_ 2654486614 CBV_bit3_NMCoordinatorBit_1E384056 0;
BA_ "GenSigTimeoutTime_ECM" SG_ 2654486614 CBV_bit3_NMCoordinatorBit_1E384056 0;
BA_ "GenSigTimeoutTime_EPS" SG_ 2654486614 CBV_bit3_NMCoordinatorBit_1E384056 0;
BA_ "GenSigTimeoutTime_ORC" SG_ 2654486614 CBV_bit3_NMCoordinatorBit_1E384056 0;
BA_ "GenSigTimeoutTime_AHCP" SG_ 2654486614 CBV_bit4_ActiveWakeupBit_1E384056 0;
BA_ "GenSigTimeoutTime_BSM" SG_ 2654486614 CBV_bit4_ActiveWakeupBit_1E384056 0;
BA_ "GenSigTimeoutTime_BSM2" SG_ 2654486614 CBV_bit4_ActiveWakeupBit_1E384056 0;
BA_ "GenSigTimeoutTime_CADM" SG_ 2654486614 CBV_bit4_ActiveWakeupBit_1E384056 0;
BA_ "GenSigTimeoutTime_CVPAM" SG_ 2654486614 CBV_bit4_ActiveWakeupBit_1E384056 0;
BA_ "GenSigTimeoutTime_ECM" SG_ 2654486614 CBV_bit4_ActiveWakeupBit_1E384056 0;
BA_ "GenSigTimeoutTime_EPS" SG_ 2654486614 CBV_bit4_ActiveWakeupBit_1E384056 0;
BA_ "GenSigTimeoutTime_ORC" SG_ 2654486614 CBV_bit4_ActiveWakeupBit_1E384056 0;
BA_ "GenSigTimeoutTime_AHCP" SG_ 2654486614 CBV_bit5_1E384056 0;
BA_ "GenSigTimeoutTime_BSM" SG_ 2654486614 CBV_bit5_1E384056 0;
BA_ "GenSigTimeoutTime_BSM2" SG_ 2654486614 CBV_bit5_1E384056 0;
BA_ "GenSigTimeoutTime_CADM" SG_ 2654486614 CBV_bit5_1E384056 0;
BA_ "GenSigTimeoutTime_CVPAM" SG_ 2654486614 CBV_bit5_1E384056 0;
BA_ "GenSigTimeoutTime_ECM" SG_ 2654486614 CBV_bit5_1E384056 0;
BA_ "GenSigTimeoutTime_EPS" SG_ 2654486614 CBV_bit5_1E384056 0;
BA_ "GenSigTimeoutTime_ORC" SG_ 2654486614 CBV_bit5_1E384056 0;
BA_ "GenSigTimeoutTime_AHCP" SG_ 2654486614 CBV_bit6_PartialNtwInfBit_1E384056 0;
BA_ "GenSigTimeoutTime_BSM" SG_ 2654486614 CBV_bit6_PartialNtwInfBit_1E384056 0;
BA_ "GenSigTimeoutTime_BSM2" SG_ 2654486614 CBV_bit6_PartialNtwInfBit_1E384056 0;
BA_ "GenSigTimeoutTime_CADM" SG_ 2654486614 CBV_bit6_PartialNtwInfBit_1E384056 0;
BA_ "GenSigTimeoutTime_CVPAM" SG_ 2654486614 CBV_bit6_PartialNtwInfBit_1E384056 0;
BA_ "GenSigTimeoutTime_ECM" SG_ 2654486614 CBV_bit6_PartialNtwInfBit_1E384056 0;
BA_ "GenSigTimeoutTime_EPS" SG_ 2654486614 CBV_bit6_PartialNtwInfBit_1E384056 0;
BA_ "GenSigTimeoutTime_ORC" SG_ 2654486614 CBV_bit6_PartialNtwInfBit_1E384056 0;
BA_ "GenSigTimeoutTime_AHCP" SG_ 2654486614 CBV_bit7_1E384056 0;
BA_ "GenSigTimeoutTime_BSM" SG_ 2654486614 CBV_bit7_1E384056 0;
BA_ "GenSigTimeoutTime_BSM2" SG_ 2654486614 CBV_bit7_1E384056 0;
BA_ "GenSigTimeoutTime_CADM" SG_ 2654486614 CBV_bit7_1E384056 0;
BA_ "GenSigTimeoutTime_CVPAM" SG_ 2654486614 CBV_bit7_1E384056 0;
BA_ "GenSigTimeoutTime_ECM" SG_ 2654486614 CBV_bit7_1E384056 0;
BA_ "GenSigTimeoutTime_EPS" SG_ 2654486614 CBV_bit7_1E384056 0;
BA_ "GenSigTimeoutTime_ORC" SG_ 2654486614 CBV_bit7_1E384056 0;
BA_ "GenSigTimeoutTime_AHCP" SG_ 2654486614 SourceNodeIdentifier_1E384056 0;
BA_ "GenSigTimeoutTime_BSM" SG_ 2654486614 SourceNodeIdentifier_1E384056 0;
BA_ "GenSigTimeoutTime_BSM2" SG_ 2654486614 SourceNodeIdentifier_1E384056 0;
BA_ "GenSigTimeoutTime_CADM" SG_ 2654486614 SourceNodeIdentifier_1E384056 0;
BA_ "GenSigTimeoutTime_CVPAM" SG_ 2654486614 SourceNodeIdentifier_1E384056 0;
BA_ "GenSigTimeoutTime_ECM" SG_ 2654486614 SourceNodeIdentifier_1E384056 0;
BA_ "GenSigTimeoutTime_EPS" SG_ 2654486614 SourceNodeIdentifier_1E384056 0;
BA_ "GenSigTimeoutTime_ORC" SG_ 2654486614 SourceNodeIdentifier_1E384056 0;
BA_ "GenSigTimeoutTime_ADCAM" SG_ 258 BrakePedalPressure 0;
BA_ "GenSigTimeoutTime_CVADAS" SG_ 258 BrakePedalPressure 0;
BA_ "GenSigTimeoutTime_VDCM" SG_ 258 BrakePedalPressure 0;
BA_ "GenSigStartValue" SG_ 258 BrakePedalPressure 2047;
BA_ "GenSigTimeoutTime_BSM" SG_ 258 BrakePedalPressure 0;
BA_ "GenSigTimeoutTime_EPS" SG_ 258 BrakePedalPressure 0;
BA_ "GenSigTimeoutTime_ORC" SG_ 258 BrakePedalPressure 0;
BA_ "GenSigTimeoutTime_ADCAM" SG_ 258 BrakeBoostPressure 0;
BA_ "GenSigTimeoutTime_CVADAS" SG_ 258 BrakeBoostPressure 0;
BA_ "GenSigTimeoutTime_VDCM" SG_ 258 BrakeBoostPressure 0;
BA_ "GenSigStartValue" SG_ 258 BrakeBoostPressure 2047;
BA_ "GenSigTimeoutTime_BSM" SG_ 258 BrakeBoostPressure 0;
BA_ "GenSigTimeoutTime_EPS" SG_ 258 BrakeBoostPressure 0;
BA_ "GenSigTimeoutTime_ORC" SG_ 258 BrakeBoostPressure 0;
BA_ "GenSigTimeoutTime_CVADAS" SG_ 258 Brk_Stat 0;
BA_ "GenSigTimeoutTime_VDCM" SG_ 258 Brk_Stat 0;
BA_ "GenSigTimeoutTime_VDCM" SG_ 258 CRC_BRAKE2 0;
BA_ "GenSigTimeoutTime_VDCM" SG_ 258 MessageCounter_BRAKE2 0;
BA_ "GenSigTimeoutTime_AHCP" SG_ 258 ACC_Wheel_Torque_BSM 0;
BA_ "GenSigTimeoutTime_BSM" SG_ 258 ACC_Wheel_Torque_BSM 0;
BA_ "GenSigTimeoutTime_BSM2" SG_ 258 ACC_Wheel_Torque_BSM 0;
BA_ "GenSigTimeoutTime_CADM" SG_ 258 ACC_Wheel_Torque_BSM 0;
BA_ "GenSigTimeoutTime_CVPAM" SG_ 258 ACC_Wheel_Torque_BSM 0;
BA_ "GenSigTimeoutTime_EPS" SG_ 258 ACC_Wheel_Torque_BSM 0;
BA_ "GenSigTimeoutTime_AHCP" SG_ 258 ACC_Wheel_Torque_Enabled_BSM 0;
BA_ "GenSigTimeoutTime_BSM" SG_ 258 ACC_Wheel_Torque_Enabled_BSM 0;
BA_ "GenSigTimeoutTime_BSM2" SG_ 258 ACC_Wheel_Torque_Enabled_BSM 0;
BA_ "GenSigTimeoutTime_CADM" SG_ 258 ACC_Wheel_Torque_Enabled_BSM 0;
BA_ "GenSigTimeoutTime_CVPAM" SG_ 258 ACC_Wheel_Torque_Enabled_BSM 0;
BA_ "GenSigTimeoutTime_EPS" SG_ 258 ACC_Wheel_Torque_Enabled_BSM 0;
BA_ "GenSigTimeoutTime_ORC" SG_ 258 ACC_Wheel_Torque_Enabled_BSM 0;
BA_ "GenSigTimeoutTime_AHCP" SG_ 258 Brk_Stat 0;
BA_ "GenSigTimeoutTime_BSM" SG_ 258 Brk_Stat 0;
BA_ "GenSigTimeoutTime_BSM2" SG_ 258 Brk_Stat 0;
BA_ "GenSigTimeoutTime_CVPAM" SG_ 258 Brk_Stat 0;
BA_ "GenSigTimeoutTime_EPS" SG_ 258 Brk_Stat 0;
BA_ "GenSigTimeoutTime_ORC" SG_ 258 Brk_Stat 0;
BA_ "GenSigTimeoutTime_AHCP" SG_ 258 ABSActive 0;
BA_ "GenSigTimeoutTime_BSM" SG_ 258 ABSActive 0;
BA_ "GenSigTimeoutTime_BSM2" SG_ 258 ABSActive 0;
BA_ "GenSigTimeoutTime_EPS" SG_ 258 ABSActive 0;
BA_ "GenSigTimeoutTime_ORC" SG_ 258 ABSActive 0;
BA_ "GenSigTimeoutTime_AHCP" SG_ 258 CRC_BRAKE2 0;
BA_ "GenSigTimeoutTime_BSM" SG_ 258 CRC_BRAKE2 0;
BA_ "GenSigTimeoutTime_ORC" SG_ 258 CRC_BRAKE2 0;
BA_ "GenSigTimeoutTime_AHCP" SG_ 258 MessageCounter_BRAKE2 0;
BA_ "GenSigTimeoutTime_BSM" SG_ 258 MessageCounter_BRAKE2 0;
BA_ "GenSigTimeoutTime_ORC" SG_ 258 MessageCounter_BRAKE2 0;
BA_ "GenSigTimeoutTime_AHCP" SG_ 258 TorqueIncrease 0;
BA_ "GenSigTimeoutTime_BSM" SG_ 258 TorqueIncrease 0;
BA_ "GenSigTimeoutTime_BSM2" SG_ 258 TorqueIncrease 0;
BA_ "GenSigTimeoutTime_CADM" SG_ 258 TorqueIncrease 0;
BA_ "GenSigTimeoutTime_CVPAM" SG_ 258 TorqueIncrease 0;
BA_ "GenSigTimeoutTime_EPS" SG_ 258 TorqueIncrease 0;
BA_ "GenSigTimeoutTime_ORC" SG_ 258 TorqueIncrease 0;
BA_ "GenSigTimeoutTime_AHCP" SG_ 258 TorqueReduct 0;
BA_ "GenSigTimeoutTime_BSM" SG_ 258 TorqueReduct 0;
BA_ "GenSigTimeoutTime_BSM2" SG_ 258 TorqueReduct 0;
BA_ "GenSigTimeoutTime_CADM" SG_ 258 TorqueReduct 0;
BA_ "GenSigTimeoutTime_CVPAM" SG_ 258 TorqueReduct 0;
BA_ "GenSigTimeoutTime_EPS" SG_ 258 TorqueReduct 0;
BA_ "GenSigTimeoutTime_ORC" SG_ 258 TorqueReduct 0;
BA_ "GenSigStartValue" SG_ 258 TorqueRequest 2047;
BA_ "GenSigTimeoutTime_AHCP" SG_ 258 TorqueRequest 0;
BA_ "GenSigTimeoutTime_BSM" SG_ 258 TorqueRequest 0;
BA_ "GenSigTimeoutTime_BSM2" SG_ 258 TorqueRequest 0;
BA_ "GenSigTimeoutTime_CADM" SG_ 258 TorqueRequest 0;
BA_ "GenSigTimeoutTime_CVPAM" SG_ 258 TorqueRequest 0;
BA_ "GenSigTimeoutTime_EPS" SG_ 258 TorqueRequest 0;
BA_ "GenSigTimeoutTime_ORC" SG_ 258 TorqueRequest 0;
BA_ "GenSigTimeoutTime_AHCP" SG_ 276 PropulsionSystemActive 0;
BA_ "GenSigTimeoutTime_BSM" SG_ 276 PropulsionSystemActive 0;
BA_ "GenSigTimeoutTime_BSM2" SG_ 276 PropulsionSystemActive 0;
BA_ "GenSigTimeoutTime_CADM" SG_ 276 PropulsionSystemActive 0;
BA_ "GenSigTimeoutTime_CVPAM" SG_ 276 PropulsionSystemActive 0;
BA_ "GenSigTimeoutTime_EPS" SG_ 276 PropulsionSystemActive 0;
BA_ "GenSigTimeoutTime_ORC" SG_ 276 PropulsionSystemActive 0;
BA_ "GenSigTimeoutTime_ADCAM" SG_ 2654486534 CBV_bit0_RepeatMessageRequestBit_1E384006 0;
BA_ "GenSigTimeoutTime_CVADAS" SG_ 2654486534 CBV_bit0_RepeatMessageRequestBit_1E384006 0;
BA_ "GenSigTimeoutTime_EVCU2" SG_ 2654486534 CBV_bit0_RepeatMessageRequestBit_1E384006 0;
BA_ "GenSigTimeoutTime_VDCM" SG_ 2654486534 CBV_bit0_RepeatMessageRequestBit_1E384006 0;
BA_ "GenSigTimeoutTime_ADCAM" SG_ 2654486534 CBV_bit1_1E384006 0;
BA_ "GenSigTimeoutTime_CVADAS" SG_ 2654486534 CBV_bit1_1E384006 0;
BA_ "GenSigTimeoutTime_EVCU2" SG_ 2654486534 CBV_bit1_1E384006 0;
BA_ "GenSigTimeoutTime_VDCM" SG_ 2654486534 CBV_bit1_1E384006 0;
BA_ "GenSigTimeoutTime_ADCAM" SG_ 2654486534 CBV_bit2_1E384006 0;
BA_ "GenSigTimeoutTime_CVADAS" SG_ 2654486534 CBV_bit2_1E384006 0;
BA_ "GenSigTimeoutTime_EVCU2" SG_ 2654486534 CBV_bit2_1E384006 0;
BA_ "GenSigTimeoutTime_VDCM" SG_ 2654486534 CBV_bit2_1E384006 0;
BA_ "GenSigTimeoutTime_ADCAM" SG_ 2654486534 CBV_bit3_NMCoordinatorBit_1E384006 0;
BA_ "GenSigTimeoutTime_CVADAS" SG_ 2654486534 CBV_bit3_NMCoordinatorBit_1E384006 0;
BA_ "GenSigTimeoutTime_EVCU2" SG_ 2654486534 CBV_bit3_NMCoordinatorBit_1E384006 0;
BA_ "GenSigTimeoutTime_VDCM" SG_ 2654486534 CBV_bit3_NMCoordinatorBit_1E384006 0;
BA_ "GenSigTimeoutTime_ADCAM" SG_ 2654486534 CBV_bit4_ActiveWakeupBit_1E384006 0;
BA_ "GenSigTimeoutTime_CVADAS" SG_ 2654486534 CBV_bit4_ActiveWakeupBit_1E384006 0;
BA_ "GenSigTimeoutTime_EVCU2" SG_ 2654486534 CBV_bit4_ActiveWakeupBit_1E384006 0;
BA_ "GenSigTimeoutTime_VDCM" SG_ 2654486534 CBV_bit4_ActiveWakeupBit_1E384006 0;
BA_ "GenSigTimeoutTime_ADCAM" SG_ 2654486534 CBV_bit5_1E384006 0;
BA_ "GenSigTimeoutTime_CVADAS" SG_ 2654486534 CBV_bit5_1E384006 0;
BA_ "GenSigTimeoutTime_EVCU2" SG_ 2654486534 CBV_bit5_1E384006 0;
BA_ "GenSigTimeoutTime_VDCM" SG_ 2654486534 CBV_bit5_1E384006 0;
BA_ "GenSigTimeoutTime_ADCAM" SG_ 2654486534 CBV_bit6_PartialNtwInfBit_1E384006 0;
BA_ "GenSigTimeoutTime_CVADAS" SG_ 2654486534 CBV_bit6_PartialNtwInfBit_1E384006 0;
BA_ "GenSigTimeoutTime_EVCU2" SG_ 2654486534 CBV_bit6_PartialNtwInfBit_1E384006 0;
BA_ "GenSigTimeoutTime_VDCM" SG_ 2654486534 CBV_bit6_PartialNtwInfBit_1E384006 0;
BA_ "GenSigTimeoutTime_ADCAM" SG_ 2654486534 CBV_bit7_1E384006 0;
BA_ "GenSigTimeoutTime_CVADAS" SG_ 2654486534 CBV_bit7_1E384006 0;
BA_ "GenSigTimeoutTime_EVCU2" SG_ 2654486534 CBV_bit7_1E384006 0;
BA_ "GenSigTimeoutTime_VDCM" SG_ 2654486534 CBV_bit7_1E384006 0;
BA_ "GenSigTimeoutTime_ADCAM" SG_ 2654486534 SourceNodeIdentifier_1E384006 0;
BA_ "GenSigTimeoutTime_CVADAS" SG_ 2654486534 SourceNodeIdentifier_1E384006 0;
BA_ "GenSigTimeoutTime_EVCU2" SG_ 2654486534 SourceNodeIdentifier_1E384006 0;
BA_ "GenSigTimeoutTime_VDCM" SG_ 2654486534 SourceNodeIdentifier_1E384006 0;
BA_ "GenSigTimeoutTime_AHCP" SG_ 2654486534 CBV_bit0_RepeatMessageRequestBit_1E384006 0;
BA_ "GenSigTimeoutTime_BSM" SG_ 2654486534 CBV_bit0_RepeatMessageRequestBit_1E384006 0;
BA_ "GenSigTimeoutTime_BSM2" SG_ 2654486534 CBV_bit0_RepeatMessageRequestBit_1E384006 0;
BA_ "GenSigTimeoutTime_CADM" SG_ 2654486534 CBV_bit0_RepeatMessageRequestBit_1E384006 0;
BA_ "GenSigTimeoutTime_CVPAM" SG_ 2654486534 CBV_bit0_RepeatMessageRequestBit_1E384006 0;
BA_ "GenSigTimeoutTime_ECM" SG_ 2654486534 CBV_bit0_RepeatMessageRequestBit_1E384006 0;
BA_ "GenSigTimeoutTime_EPS" SG_ 2654486534 CBV_bit0_RepeatMessageRequestBit_1E384006 0;
BA_ "GenSigTimeoutTime_ORC" SG_ 2654486534 CBV_bit0_RepeatMessageRequestBit_1E384006 0;
BA_ "GenSigTimeoutTime_AHCP" SG_ 2654486534 CBV_bit1_1E384006 0;
BA_ "GenSigTimeoutTime_BSM" SG_ 2654486534 CBV_bit1_1E384006 0;
BA_ "GenSigTimeoutTime_BSM2" SG_ 2654486534 CBV_bit1_1E384006 0;
BA_ "GenSigTimeoutTime_CADM" SG_ 2654486534 CBV_bit1_1E384006 0;
BA_ "GenSigTimeoutTime_CVPAM" SG_ 2654486534 CBV_bit1_1E384006 0;
BA_ "GenSigTimeoutTime_ECM" SG_ 2654486534 CBV_bit1_1E384006 0;
BA_ "GenSigTimeoutTime_EPS" SG_ 2654486534 CBV_bit1_1E384006 0;
BA_ "GenSigTimeoutTime_ORC" SG_ 2654486534 CBV_bit1_1E384006 0;
BA_ "GenSigTimeoutTime_AHCP" SG_ 2654486534 CBV_bit2_1E384006 0;
BA_ "GenSigTimeoutTime_BSM" SG_ 2654486534 CBV_bit2_1E384006 0;
BA_ "GenSigTimeoutTime_BSM2" SG_ 2654486534 CBV_bit2_1E384006 0;
BA_ "GenSigTimeoutTime_CADM" SG_ 2654486534 CBV_bit2_1E384006 0;
BA_ "GenSigTimeoutTime_CVPAM" SG_ 2654486534 CBV_bit2_1E384006 0;
BA_ "GenSigTimeoutTime_ECM" SG_ 2654486534 CBV_bit2_1E384006 0;
BA_ "GenSigTimeoutTime_EPS" SG_ 2654486534 CBV_bit2_1E384006 0;
BA_ "GenSigTimeoutTime_ORC" SG_ 2654486534 CBV_bit2_1E384006 0;
BA_ "GenSigTimeoutTime_AHCP" SG_ 2654486534 CBV_bit3_NMCoordinatorBit_1E384006 0;
BA_ "GenSigTimeoutTime_BSM" SG_ 2654486534 CBV_bit3_NMCoordinatorBit_1E384006 0;
BA_ "GenSigTimeoutTime_BSM2" SG_ 2654486534 CBV_bit3_NMCoordinatorBit_1E384006 0;
BA_ "GenSigTimeoutTime_CADM" SG_ 2654486534 CBV_bit3_NMCoordinatorBit_1E384006 0;
BA_ "GenSigTimeoutTime_CVPAM" SG_ 2654486534 CBV_bit3_NMCoordinatorBit_1E384006 0;
BA_ "GenSigTimeoutTime_ECM" SG_ 2654486534 CBV_bit3_NMCoordinatorBit_1E384006 0;
BA_ "GenSigTimeoutTime_EPS" SG_ 2654486534 CBV_bit3_NMCoordinatorBit_1E384006 0;
BA_ "GenSigTimeoutTime_ORC" SG_ 2654486534 CBV_bit3_NMCoordinatorBit_1E384006 0;
BA_ "GenSigTimeoutTime_AHCP" SG_ 2654486534 CBV_bit4_ActiveWakeupBit_1E384006 0;
BA_ "GenSigTimeoutTime_BSM" SG_ 2654486534 CBV_bit4_ActiveWakeupBit_1E384006 0;
BA_ "GenSigTimeoutTime_BSM2" SG_ 2654486534 CBV_bit4_ActiveWakeupBit_1E384006 0;
BA_ "GenSigTimeoutTime_CADM" SG_ 2654486534 CBV_bit4_ActiveWakeupBit_1E384006 0;
BA_ "GenSigTimeoutTime_CVPAM" SG_ 2654486534 CBV_bit4_ActiveWakeupBit_1E384006 0;
BA_ "GenSigTimeoutTime_ECM" SG_ 2654486534 CBV_bit4_ActiveWakeupBit_1E384006 0;
BA_ "GenSigTimeoutTime_EPS" SG_ 2654486534 CBV_bit4_ActiveWakeupBit_1E384006 0;
BA_ "GenSigTimeoutTime_ORC" SG_ 2654486534 CBV_bit4_ActiveWakeupBit_1E384006 0;
BA_ "GenSigTimeoutTime_AHCP" SG_ 2654486534 CBV_bit5_1E384006 0;
BA_ "GenSigTimeoutTime_BSM" SG_ 2654486534 CBV_bit5_1E384006 0;
BA_ "GenSigTimeoutTime_BSM2" SG_ 2654486534 CBV_bit5_1E384006 0;
BA_ "GenSigTimeoutTime_CADM" SG_ 2654486534 CBV_bit5_1E384006 0;
BA_ "GenSigTimeoutTime_CVPAM" SG_ 2654486534 CBV_bit5_1E384006 0;
BA_ "GenSigTimeoutTime_ECM" SG_ 2654486534 CBV_bit5_1E384006 0;
BA_ "GenSigTimeoutTime_EPS" SG_ 2654486534 CBV_bit5_1E384006 0;
BA_ "GenSigTimeoutTime_ORC" SG_ 2654486534 CBV_bit5_1E384006 0;
BA_ "GenSigTimeoutTime_AHCP" SG_ 2654486534 CBV_bit6_PartialNtwInfBit_1E384006 0;
BA_ "GenSigTimeoutTime_BSM" SG_ 2654486534 CBV_bit6_PartialNtwInfBit_1E384006 0;
BA_ "GenSigTimeoutTime_BSM2" SG_ 2654486534 CBV_bit6_PartialNtwInfBit_1E384006 0;
BA_ "GenSigTimeoutTime_CADM" SG_ 2654486534 CBV_bit6_PartialNtwInfBit_1E384006 0;
BA_ "GenSigTimeoutTime_CVPAM" SG_ 2654486534 CBV_bit6_PartialNtwInfBit_1E384006 0;
BA_ "GenSigTimeoutTime_ECM" SG_ 2654486534 CBV_bit6_PartialNtwInfBit_1E384006 0;
BA_ "GenSigTimeoutTime_EPS" SG_ 2654486534 CBV_bit6_PartialNtwInfBit_1E384006 0;
BA_ "GenSigTimeoutTime_ORC" SG_ 2654486534 CBV_bit6_PartialNtwInfBit_1E384006 0;
BA_ "GenSigTimeoutTime_AHCP" SG_ 2654486534 CBV_bit7_1E384006 0;
BA_ "GenSigTimeoutTime_BSM" SG_ 2654486534 CBV_bit7_1E384006 0;
BA_ "GenSigTimeoutTime_BSM2" SG_ 2654486534 CBV_bit7_1E384006 0;
BA_ "GenSigTimeoutTime_CADM" SG_ 2654486534 CBV_bit7_1E384006 0;
BA_ "GenSigTimeoutTime_CVPAM" SG_ 2654486534 CBV_bit7_1E384006 0;
BA_ "GenSigTimeoutTime_ECM" SG_ 2654486534 CBV_bit7_1E384006 0;
BA_ "GenSigTimeoutTime_EPS" SG_ 2654486534 CBV_bit7_1E384006 0;
BA_ "GenSigTimeoutTime_ORC" SG_ 2654486534 CBV_bit7_1E384006 0;
BA_ "GenSigTimeoutTime_AHCP" SG_ 2654486534 SourceNodeIdentifier_1E384006 0;
BA_ "GenSigTimeoutTime_BSM" SG_ 2654486534 SourceNodeIdentifier_1E384006 0;
BA_ "GenSigTimeoutTime_BSM2" SG_ 2654486534 SourceNodeIdentifier_1E384006 0;
BA_ "GenSigTimeoutTime_CADM" SG_ 2654486534 SourceNodeIdentifier_1E384006 0;
BA_ "GenSigTimeoutTime_CVPAM" SG_ 2654486534 SourceNodeIdentifier_1E384006 0;
BA_ "GenSigTimeoutTime_ECM" SG_ 2654486534 SourceNodeIdentifier_1E384006 0;
BA_ "GenSigTimeoutTime_EPS" SG_ 2654486534 SourceNodeIdentifier_1E384006 0;
BA_ "GenSigTimeoutTime_ORC" SG_ 2654486534 SourceNodeIdentifier_1E384006 0;
BA_ "GenSigTimeoutTime_AHCP" SG_ 2654486669 CBV_bit0_RepeatMessageRequestBit_1E38408D 0;
BA_ "GenSigTimeoutTime_BSM" SG_ 2654486669 CBV_bit0_RepeatMessageRequestBit_1E38408D 0;
BA_ "GenSigTimeoutTime_BSM2" SG_ 2654486669 CBV_bit0_RepeatMessageRequestBit_1E38408D 0;
BA_ "GenSigTimeoutTime_CADM" SG_ 2654486669 CBV_bit0_RepeatMessageRequestBit_1E38408D 0;
BA_ "GenSigTimeoutTime_CVPAM" SG_ 2654486669 CBV_bit0_RepeatMessageRequestBit_1E38408D 0;
BA_ "GenSigTimeoutTime_ECM" SG_ 2654486669 CBV_bit0_RepeatMessageRequestBit_1E38408D 0;
BA_ "GenSigTimeoutTime_EPS" SG_ 2654486669 CBV_bit0_RepeatMessageRequestBit_1E38408D 0;
BA_ "GenSigTimeoutTime_ORC" SG_ 2654486669 CBV_bit0_RepeatMessageRequestBit_1E38408D 0;
BA_ "GenSigTimeoutTime_AHCP" SG_ 2654486669 CBV_bit1_1E38408D 0;
BA_ "GenSigTimeoutTime_BSM" SG_ 2654486669 CBV_bit1_1E38408D 0;
BA_ "GenSigTimeoutTime_BSM2" SG_ 2654486669 CBV_bit1_1E38408D 0;
BA_ "GenSigTimeoutTime_CADM" SG_ 2654486669 CBV_bit1_1E38408D 0;
BA_ "GenSigTimeoutTime_CVPAM" SG_ 2654486669 CBV_bit1_1E38408D 0;
BA_ "GenSigTimeoutTime_ECM" SG_ 2654486669 CBV_bit1_1E38408D 0;
BA_ "GenSigTimeoutTime_EPS" SG_ 2654486669 CBV_bit1_1E38408D 0;
BA_ "GenSigTimeoutTime_ORC" SG_ 2654486669 CBV_bit1_1E38408D 0;
BA_ "GenSigTimeoutTime_AHCP" SG_ 2654486669 CBV_bit2_1E38408D 0;
BA_ "GenSigTimeoutTime_BSM" SG_ 2654486669 CBV_bit2_1E38408D 0;
BA_ "GenSigTimeoutTime_BSM2" SG_ 2654486669 CBV_bit2_1E38408D 0;
BA_ "GenSigTimeoutTime_CADM" SG_ 2654486669 CBV_bit2_1E38408D 0;
BA_ "GenSigTimeoutTime_CVPAM" SG_ 2654486669 CBV_bit2_1E38408D 0;
BA_ "GenSigTimeoutTime_ECM" SG_ 2654486669 CBV_bit2_1E38408D 0;
BA_ "GenSigTimeoutTime_EPS" SG_ 2654486669 CBV_bit2_1E38408D 0;
BA_ "GenSigTimeoutTime_ORC" SG_ 2654486669 CBV_bit2_1E38408D 0;
BA_ "GenSigTimeoutTime_AHCP" SG_ 2654486669 CBV_bit3_NMCoordinatorBit_1E38408D 0;
BA_ "GenSigTimeoutTime_BSM" SG_ 2654486669 CBV_bit3_NMCoordinatorBit_1E38408D 0;
BA_ "GenSigTimeoutTime_BSM2" SG_ 2654486669 CBV_bit3_NMCoordinatorBit_1E38408D 0;
BA_ "GenSigTimeoutTime_CADM" SG_ 2654486669 CBV_bit3_NMCoordinatorBit_1E38408D 0;
BA_ "GenSigTimeoutTime_CVPAM" SG_ 2654486669 CBV_bit3_NMCoordinatorBit_1E38408D 0;
BA_ "GenSigTimeoutTime_ECM" SG_ 2654486669 CBV_bit3_NMCoordinatorBit_1E38408D 0;
BA_ "GenSigTimeoutTime_EPS" SG_ 2654486669 CBV_bit3_NMCoordinatorBit_1E38408D 0;
BA_ "GenSigTimeoutTime_ORC" SG_ 2654486669 CBV_bit3_NMCoordinatorBit_1E38408D 0;
BA_ "GenSigTimeoutTime_AHCP" SG_ 2654486669 CBV_bit4_ActiveWakeupBit_1E38408D 0;
BA_ "GenSigTimeoutTime_BSM" SG_ 2654486669 CBV_bit4_ActiveWakeupBit_1E38408D 0;
BA_ "GenSigTimeoutTime_BSM2" SG_ 2654486669 CBV_bit4_ActiveWakeupBit_1E38408D 0;
BA_ "GenSigTimeoutTime_CADM" SG_ 2654486669 CBV_bit4_ActiveWakeupBit_1E38408D 0;
BA_ "GenSigTimeoutTime_CVPAM" SG_ 2654486669 CBV_bit4_ActiveWakeupBit_1E38408D 0;
BA_ "GenSigTimeoutTime_ECM" SG_ 2654486669 CBV_bit4_ActiveWakeupBit_1E38408D 0;
BA_ "GenSigTimeoutTime_EPS" SG_ 2654486669 CBV_bit4_ActiveWakeupBit_1E38408D 0;
BA_ "GenSigTimeoutTime_ORC" SG_ 2654486669 CBV_bit4_ActiveWakeupBit_1E38408D 0;
BA_ "GenSigTimeoutTime_AHCP" SG_ 2654486669 CBV_bit5_1E38408D 0;
BA_ "GenSigTimeoutTime_BSM" SG_ 2654486669 CBV_bit5_1E38408D 0;
BA_ "GenSigTimeoutTime_BSM2" SG_ 2654486669 CBV_bit5_1E38408D 0;
BA_ "GenSigTimeoutTime_CADM" SG_ 2654486669 CBV_bit5_1E38408D 0;
BA_ "GenSigTimeoutTime_CVPAM" SG_ 2654486669 CBV_bit5_1E38408D 0;
BA_ "GenSigTimeoutTime_ECM" SG_ 2654486669 CBV_bit5_1E38408D 0;
BA_ "GenSigTimeoutTime_EPS" SG_ 2654486669 CBV_bit5_1E38408D 0;
BA_ "GenSigTimeoutTime_ORC" SG_ 2654486669 CBV_bit5_1E38408D 0;
BA_ "GenSigTimeoutTime_AHCP" SG_ 2654486669 CBV_bit6_PartialNtwInfBit_1E38408D 0;
BA_ "GenSigTimeoutTime_BSM" SG_ 2654486669 CBV_bit6_PartialNtwInfBit_1E38408D 0;
BA_ "GenSigTimeoutTime_BSM2" SG_ 2654486669 CBV_bit6_PartialNtwInfBit_1E38408D 0;
BA_ "GenSigTimeoutTime_CADM" SG_ 2654486669 CBV_bit6_PartialNtwInfBit_1E38408D 0;
BA_ "GenSigTimeoutTime_CVPAM" SG_ 2654486669 CBV_bit6_PartialNtwInfBit_1E38408D 0;
BA_ "GenSigTimeoutTime_ECM" SG_ 2654486669 CBV_bit6_PartialNtwInfBit_1E38408D 0;
BA_ "GenSigTimeoutTime_EPS" SG_ 2654486669 CBV_bit6_PartialNtwInfBit_1E38408D 0;
BA_ "GenSigTimeoutTime_ORC" SG_ 2654486669 CBV_bit6_PartialNtwInfBit_1E38408D 0;
BA_ "GenSigTimeoutTime_AHCP" SG_ 2654486669 CBV_bit7_1E38408D 0;
BA_ "GenSigTimeoutTime_BSM" SG_ 2654486669 CBV_bit7_1E38408D 0;
BA_ "GenSigTimeoutTime_BSM2" SG_ 2654486669 CBV_bit7_1E38408D 0;
BA_ "GenSigTimeoutTime_CADM" SG_ 2654486669 CBV_bit7_1E38408D 0;
BA_ "GenSigTimeoutTime_CVPAM" SG_ 2654486669 CBV_bit7_1E38408D 0;
BA_ "GenSigTimeoutTime_ECM" SG_ 2654486669 CBV_bit7_1E38408D 0;
BA_ "GenSigTimeoutTime_EPS" SG_ 2654486669 CBV_bit7_1E38408D 0;
BA_ "GenSigTimeoutTime_ORC" SG_ 2654486669 CBV_bit7_1E38408D 0;
BA_ "GenSigTimeoutTime_AHCP" SG_ 2654486669 SourceNodeIdentifier_1E38408D 0;
BA_ "GenSigTimeoutTime_BSM" SG_ 2654486669 SourceNodeIdentifier_1E38408D 0;
BA_ "GenSigTimeoutTime_BSM2" SG_ 2654486669 SourceNodeIdentifier_1E38408D 0;
BA_ "GenSigTimeoutTime_CADM" SG_ 2654486669 SourceNodeIdentifier_1E38408D 0;
BA_ "GenSigTimeoutTime_CVPAM" SG_ 2654486669 SourceNodeIdentifier_1E38408D 0;
BA_ "GenSigTimeoutTime_ECM" SG_ 2654486669 SourceNodeIdentifier_1E38408D 0;
BA_ "GenSigTimeoutTime_EPS" SG_ 2654486669 SourceNodeIdentifier_1E38408D 0;
BA_ "GenSigTimeoutTime_ORC" SG_ 2654486669 SourceNodeIdentifier_1E38408D 0;
BA_ "GenSigTimeoutTime_ADCAM" SG_ 1456 Set_Speed_KPH 0;
BA_ "GenSigTimeoutTime_CVADAS" SG_ 1456 Set_Speed_KPH 0;
BA_ "GenSigTimeoutTime_VDCM" SG_ 1456 Set_Speed_KPH 0;
BA_ "GenSigTimeoutTime_ADCAM" SG_ 1456 Set_Speed_MPH 0;
BA_ "GenSigTimeoutTime_CVADAS" SG_ 1456 Set_Speed_MPH 0;
BA_ "GenSigTimeoutTime_VDCM" SG_ 1456 Set_Speed_MPH 0;
BA_ "GenSigSendType" SG_ 1456 Set_Speed_KPH 3;
BA_ "GenSigTimeoutTime_AHCP" SG_ 1456 Set_Speed_KPH 0;
BA_ "GenSigTimeoutTime_BSM" SG_ 1456 Set_Speed_KPH 0;
BA_ "GenSigTimeoutTime_BSM2" SG_ 1456 Set_Speed_KPH 0;
BA_ "GenSigTimeoutTime_CADM" SG_ 1456 Set_Speed_KPH 0;
BA_ "GenSigTimeoutTime_CVPAM" SG_ 1456 Set_Speed_KPH 0;
BA_ "GenSigTimeoutTime_EPS" SG_ 1456 Set_Speed_KPH 0;
BA_ "GenSigSendType" SG_ 1456 Set_Speed_MPH 3;
BA_ "GenSigTimeoutTime_AHCP" SG_ 1456 Set_Speed_MPH 0;
BA_ "GenSigTimeoutTime_BSM" SG_ 1456 Set_Speed_MPH 0;
BA_ "GenSigTimeoutTime_BSM2" SG_ 1456 Set_Speed_MPH 0;
BA_ "GenSigTimeoutTime_CADM" SG_ 1456 Set_Speed_MPH 0;
BA_ "GenSigTimeoutTime_CVPAM" SG_ 1456 Set_Speed_MPH 0;
BA_ "GenSigTimeoutTime_EPS" SG_ 1456 Set_Speed_MPH 0;
BA_ "GenSigTimeoutTime_ORC" SG_ 1456 Set_Speed_MPH 0;
BA_ "GenSigTimeoutTime_AHCP" SG_ 1456 CRC_ADAS_FD_HMI 0;
BA_ "GenSigTimeoutTime_CADM" SG_ 1456 CRC_ADAS_FD_HMI 0;
BA_ "GenSigTimeoutTime_CVPAM" SG_ 1456 CRC_ADAS_FD_HMI 0;
BA_ "GenSigTimeoutTime_ORC" SG_ 1456 CRC_ADAS_FD_HMI 0;
BA_ "GenSigTimeoutTime_AHCP" SG_ 1456 MessageCounter_ADAS_FD_HMI 0;
BA_ "GenSigTimeoutTime_CADM" SG_ 1456 MessageCounter_ADAS_FD_HMI 0;
BA_ "GenSigTimeoutTime_CVPAM" SG_ 1456 MessageCounter_ADAS_FD_HMI 0;
BA_ "GenSigTimeoutTime_ORC" SG_ 1456 MessageCounter_ADAS_FD_HMI 0;
BA_ "GenSigTimeoutTime_CVADAS" SG_ 513 CRC_BRAKE1 0;
BA_ "GenSigTimeoutTime_VDCM" SG_ 513 CRC_BRAKE1 0;
BA_ "GenSigTimeoutTime_BSM" SG_ 513 CRC_BRAKE1 0;
BA_ "GenSigTimeoutTime_EPS" SG_ 513 CRC_BRAKE1 0;
BA_ "GenSigTimeoutTime_ORC" SG_ 513 CRC_BRAKE1 0;
BA_ "GenSigTimeoutTime_CVADAS" SG_ 513 MessageCounter_BRAKE1 0;
BA_ "GenSigTimeoutTime_VDCM" SG_ 513 MessageCounter_BRAKE1 0;
BA_ "GenSigTimeoutTime_BSM" SG_ 513 MessageCounter_BRAKE1 0;
BA_ "GenSigTimeoutTime_EPS" SG_ 513 MessageCounter_BRAKE1 0;
BA_ "GenSigTimeoutTime_ORC" SG_ 513 MessageCounter_BRAKE1 0;
BA_ "GenSigTimeoutTime_AHCP" SG_ 513 SelectSpdSts 0;
BA_ "GenSigTimeoutTime_BSM" SG_ 513 SelectSpdSts 0;
BA_ "GenSigTimeoutTime_BSM2" SG_ 513 SelectSpdSts 0;
BA_ "GenSigTimeoutTime_CADM" SG_ 513 SelectSpdSts 0;
BA_ "GenSigTimeoutTime_CVPAM" SG_ 513 SelectSpdSts 0;
BA_ "GenSigTimeoutTime_EPS" SG_ 513 SelectSpdSts 0;
BA_ "GenSigTimeoutTime_ORC" SG_ 513 SelectSpdSts 0;
BA_ "GenSigTimeoutTime_CVADAS" SG_ 1155 CRC_BRAKE5 0;
BA_ "GenSigTimeoutTime_VDCM" SG_ 1155 CRC_BRAKE5 0;
BA_ "GenSigTimeoutTime_CVADAS" SG_ 1155 MessageCounter_BRAKE5 0;
BA_ "GenSigTimeoutTime_VDCM" SG_ 1155 MessageCounter_BRAKE5 0;
BA_ "GenSigTimeoutTime_ADCAM" SG_ 1155 ABSFailSts 0;
BA_ "GenSigTimeoutTime_CVADAS" SG_ 1155 ABSFailSts 0;
BA_ "GenSigTimeoutTime_VDCM" SG_ 1155 ABSFailSts 0;
BA_ "GenSigTimeoutTime_ADCAM" SG_ 1155 ACCEngaged 0;
BA_ "GenSigTimeoutTime_CVADAS" SG_ 1155 ACCEngaged 0;
BA_ "GenSigTimeoutTime_VDCM" SG_ 1155 ACCEngaged 0;
BA_ "GenSigTimeoutTime_AHCP" SG_ 1155 CRC_BRAKE5 0;
BA_ "GenSigTimeoutTime_BSM" SG_ 1155 CRC_BRAKE5 0;
BA_ "GenSigTimeoutTime_EPS" SG_ 1155 CRC_BRAKE5 0;
BA_ "GenSigTimeoutTime_ORC" SG_ 1155 CRC_BRAKE5 0;
BA_ "GenSigTimeoutTime_AHCP" SG_ 1155 MessageCounter_BRAKE5 0;
BA_ "GenSigTimeoutTime_BSM" SG_ 1155 MessageCounter_BRAKE5 0;
BA_ "GenSigTimeoutTime_EPS" SG_ 1155 MessageCounter_BRAKE5 0;
BA_ "GenSigTimeoutTime_ORC" SG_ 1155 MessageCounter_BRAKE5 0;
BA_ "GenSigSendType" SG_ 1155 ABSFailSts 3;
BA_ "GenSigTimeoutTime_AHCP" SG_ 1155 ABSFailSts 0;
BA_ "GenSigTimeoutTime_BSM" SG_ 1155 ABSFailSts 0;
BA_ "GenSigTimeoutTime_BSM2" SG_ 1155 ABSFailSts 0;
BA_ "GenSigTimeoutTime_CADM" SG_ 1155 ABSFailSts 0;
BA_ "GenSigTimeoutTime_EPS" SG_ 1155 ABSFailSts 0;
BA_ "GenSigTimeoutTime_ORC" SG_ 1155 ABSFailSts 0;
BA_ "GenSigSendType" SG_ 1155 ACCEngaged 3;
BA_ "GenSigTimeoutTime_AHCP" SG_ 1155 ACCEngaged 0;
BA_ "GenSigTimeoutTime_BSM" SG_ 1155 ACCEngaged 0;
BA_ "GenSigTimeoutTime_BSM2" SG_ 1155 ACCEngaged 0;
BA_ "GenSigTimeoutTime_CADM" SG_ 1155 ACCEngaged 0;
BA_ "GenSigTimeoutTime_CVPAM" SG_ 1155 ACCEngaged 0;
BA_ "GenSigTimeoutTime_EPS" SG_ 1155 ACCEngaged 0;
BA_ "GenSigTimeoutTime_ORC" SG_ 1155 ACCEngaged 0;
BA_ "GenSigTimeoutTime_VDCM" SG_ 514 CRC_BRAKE7 0;
BA_ "GenSigTimeoutTime_BSM" SG_ 514 CRC_BRAKE7 0;
BA_ "GenSigTimeoutTime_EPS" SG_ 514 CRC_BRAKE7 0;
BA_ "GenSigTimeoutTime_ORC" SG_ 514 CRC_BRAKE7 0;
BA_ "GenSigTimeoutTime_VDCM" SG_ 514 MessageCounter_BRAKE7 0;
BA_ "GenSigTimeoutTime_BSM" SG_ 514 MessageCounter_BRAKE7 0;
BA_ "GenSigTimeoutTime_EPS" SG_ 514 MessageCounter_BRAKE7 0;
BA_ "GenSigTimeoutTime_ORC" SG_ 514 MessageCounter_BRAKE7 0;
BA_ "GenSigTimeoutTime_CVADAS" SG_ 514 BrkPdl_Flt 0;
BA_ "GenSigTimeoutTime_VDCM" SG_ 514 BrkPdl_Flt 0;
BA_ "GenSigTimeoutTime_BSM" SG_ 514 BrkPdl_Flt 0;
BA_ "GenSigTimeoutTime_EPS" SG_ 514 BrkPdl_Flt 0;
BA_ "GenSigTimeoutTime_ORC" SG_ 514 BrkPdl_Flt 0;
BA_ "GenSigTimeoutTime_CVADAS" SG_ 514 BrakePdlPosn 0;
BA_ "GenSigTimeoutTime_VDCM" SG_ 514 BrakePdlPosn 0;
BA_ "GenSigTimeoutTime_BSM" SG_ 514 BrakePdlPosn 0;
BA_ "GenSigTimeoutTime_EPS" SG_ 514 BrakePdlPosn 0;
BA_ "GenSigTimeoutTime_ORC" SG_ 514 BrakePdlPosn 0;
BA_ "GenSigTimeoutTime_CVADAS" SG_ 514 BrkPdl_Stat 0;
BA_ "GenSigTimeoutTime_VDCM" SG_ 514 BrkPdl_Stat 0;
BA_ "GenSigStartValue" SG_ 514 BrkPdl_Stat 3;
BA_ "GenSigTimeoutTime_AHCP" SG_ 514 BrkPdl_Stat 0;
BA_ "GenSigTimeoutTime_BSM" SG_ 514 BrkPdl_Stat 0;
BA_ "GenSigTimeoutTime_CVPAM" SG_ 514 BrkPdl_Stat 0;
BA_ "GenSigTimeoutTime_EPS" SG_ 514 BrkPdl_Stat 0;
BA_ "GenSigTimeoutTime_ORC" SG_ 514 BrkPdl_Stat 0;
BA_ "GenSigTimeoutTime_ADCAM" SG_ 204 Rear_Axle_Regen_Capacity 0;
BA_ "GenSigTimeoutTime_CVADAS" SG_ 204 Rear_Axle_Regen_Capacity 0;
BA_ "GenSigTimeoutTime_EVCU2" SG_ 204 Rear_Axle_Regen_Capacity 0;
BA_ "GenSigTimeoutTime_VDCM" SG_ 204 Rear_Axle_Regen_Capacity 0;
BA_ "GenSigTimeoutTime_ECM" SG_ 204 Rear_Axle_Regen_Capacity 0;
BA_ "GenSigTimeoutTime_EPS" SG_ 204 Rear_Axle_Regen_Capacity 0;
BA_ "GenSigTimeoutTime_ORC" SG_ 204 Rear_Axle_Regen_Capacity 0;
BA_ "GenSigTimeoutTime_ADCAM" SG_ 204 Rear_Axle_Est_Regen_Torq 0;
BA_ "GenSigTimeoutTime_CVADAS" SG_ 204 Rear_Axle_Est_Regen_Torq 0;
BA_ "GenSigTimeoutTime_EVCU2" SG_ 204 Rear_Axle_Est_Regen_Torq 0;
BA_ "GenSigTimeoutTime_VDCM" SG_ 204 Rear_Axle_Est_Regen_Torq 0;
BA_ "GenSigTimeoutTime_ECM" SG_ 204 Rear_Axle_Est_Regen_Torq 0;
BA_ "GenSigTimeoutTime_EPS" SG_ 204 Rear_Axle_Est_Regen_Torq 0;
BA_ "GenSigTimeoutTime_ORC" SG_ 204 Rear_Axle_Est_Regen_Torq 0;
BA_ "GenSigTimeoutTime_ADCAM" SG_ 204 Front_Axle_Regen_Capacity 0;
BA_ "GenSigTimeoutTime_CVADAS" SG_ 204 Front_Axle_Regen_Capacity 0;
BA_ "GenSigTimeoutTime_EVCU2" SG_ 204 Front_Axle_Regen_Capacity 0;
BA_ "GenSigTimeoutTime_VDCM" SG_ 204 Front_Axle_Regen_Capacity 0;
BA_ "GenSigTimeoutTime_ECM" SG_ 204 Front_Axle_Regen_Capacity 0;
BA_ "GenSigTimeoutTime_EPS" SG_ 204 Front_Axle_Regen_Capacity 0;
BA_ "GenSigTimeoutTime_ORC" SG_ 204 Front_Axle_Regen_Capacity 0;
BA_ "GenSigTimeoutTime_ADCAM" SG_ 204 Front_Axle_Est_Regen_Torq 0;
BA_ "GenSigTimeoutTime_CVADAS" SG_ 204 Front_Axle_Est_Regen_Torq 0;
BA_ "GenSigTimeoutTime_EVCU2" SG_ 204 Front_Axle_Est_Regen_Torq 0;
BA_ "GenSigTimeoutTime_VDCM" SG_ 204 Front_Axle_Est_Regen_Torq 0;
BA_ "GenSigTimeoutTime_ECM" SG_ 204 Front_Axle_Est_Regen_Torq 0;
BA_ "GenSigTimeoutTime_EPS" SG_ 204 Front_Axle_Est_Regen_Torq 0;
BA_ "GenSigTimeoutTime_ORC" SG_ 204 Front_Axle_Est_Regen_Torq 0;
BA_ "GenSigTimeoutTime_ADCAM" SG_ 204 Rear_AxleTorque_Min 0;
BA_ "GenSigTimeoutTime_CVADAS" SG_ 204 Rear_AxleTorque_Min 0;
BA_ "GenSigTimeoutTime_EVCU2" SG_ 204 Rear_AxleTorque_Min 0;
BA_ "GenSigTimeoutTime_VDCM" SG_ 204 Rear_AxleTorque_Min 0;
BA_ "GenSigStartValue" SG_ 204 Rear_AxleTorque_Min 32767;
BA_ "GenSigTimeoutTime_ECM" SG_ 204 Rear_AxleTorque_Min 0;
BA_ "GenSigTimeoutTime_EPS" SG_ 204 Rear_AxleTorque_Min 0;
BA_ "GenSigTimeoutTime_ORC" SG_ 204 Rear_AxleTorque_Min 0;
BA_ "GenSigTimeoutTime_ADCAM" SG_ 204 Rear_AxleTorque_Max 0;
BA_ "GenSigTimeoutTime_CVADAS" SG_ 204 Rear_AxleTorque_Max 0;
BA_ "GenSigTimeoutTime_EVCU2" SG_ 204 Rear_AxleTorque_Max 0;
BA_ "GenSigTimeoutTime_VDCM" SG_ 204 Rear_AxleTorque_Max 0;
BA_ "GenSigStartValue" SG_ 204 Rear_AxleTorque_Max 32767;
BA_ "GenSigTimeoutTime_ECM" SG_ 204 Rear_AxleTorque_Max 0;
BA_ "GenSigTimeoutTime_EPS" SG_ 204 Rear_AxleTorque_Max 0;
BA_ "GenSigTimeoutTime_ORC" SG_ 204 Rear_AxleTorque_Max 0;
BA_ "GenSigTimeoutTime_ADCAM" SG_ 204 Front_AxleTorque_Min 0;
BA_ "GenSigTimeoutTime_CVADAS" SG_ 204 Front_AxleTorque_Min 0;
BA_ "GenSigTimeoutTime_EVCU2" SG_ 204 Front_AxleTorque_Min 0;
BA_ "GenSigTimeoutTime_VDCM" SG_ 204 Front_AxleTorque_Min 0;
BA_ "GenSigStartValue" SG_ 204 Front_AxleTorque_Min 32767;
BA_ "GenSigTimeoutTime_ECM" SG_ 204 Front_AxleTorque_Min 0;
BA_ "GenSigTimeoutTime_EPS" SG_ 204 Front_AxleTorque_Min 0;
BA_ "GenSigTimeoutTime_ORC" SG_ 204 Front_AxleTorque_Min 0;
BA_ "GenSigTimeoutTime_ADCAM" SG_ 204 Front_AxleTorque_Max 0;
BA_ "GenSigTimeoutTime_CVADAS" SG_ 204 Front_AxleTorque_Max 0;
BA_ "GenSigTimeoutTime_EVCU2" SG_ 204 Front_AxleTorque_Max 0;
BA_ "GenSigTimeoutTime_VDCM" SG_ 204 Front_AxleTorque_Max 0;
BA_ "GenSigStartValue" SG_ 204 Front_AxleTorque_Max 32767;
BA_ "GenSigTimeoutTime_ECM" SG_ 204 Front_AxleTorque_Max 0;
BA_ "GenSigTimeoutTime_EPS" SG_ 204 Front_AxleTorque_Max 0;
BA_ "GenSigTimeoutTime_ORC" SG_ 204 Front_AxleTorque_Max 0;
BA_ "GenSigTimeoutTime_CVADAS" SG_ 204 Axle_Torque_DrvReqMod 0;
BA_ "GenSigTimeoutTime_EVCU2" SG_ 204 Axle_Torque_DrvReqMod 0;
BA_ "GenSigTimeoutTime_VDCM" SG_ 204 Axle_Torque_DrvReqMod 0;
BA_ "GenSigTimeoutTime_CVADAS" SG_ 204 Axle_TorqueStatic_D_TTC 0;
BA_ "GenSigTimeoutTime_EVCU2" SG_ 204 Axle_TorqueStatic_D_TTC 0;
BA_ "GenSigTimeoutTime_CVADAS" SG_ 204 Total_AxleTorque_Max 0;
BA_ "GenSigTimeoutTime_EVCU2" SG_ 204 Total_AxleTorque_Max 0;
BA_ "GenSigTimeoutTime_VDCM" SG_ 204 Total_AxleTorque_Max 0;
BA_ "GenSigTimeoutTime_CVADAS" SG_ 204 Total_AxleTorque_Min 0;
BA_ "GenSigTimeoutTime_EVCU2" SG_ 204 Total_AxleTorque_Min 0;
BA_ "GenSigTimeoutTime_VDCM" SG_ 204 Total_AxleTorque_Min 0;
BA_ "GenSigTimeoutTime_CVADAS" SG_ 204 CRC_AXLE_TORQUE_FD_1 0;
BA_ "GenSigTimeoutTime_EVCU2" SG_ 204 CRC_AXLE_TORQUE_FD_1 0;
BA_ "GenSigTimeoutTime_VDCM" SG_ 204 CRC_AXLE_TORQUE_FD_1 0;
BA_ "GenSigTimeoutTime_BSM" SG_ 204 CRC_AXLE_TORQUE_FD_1 0;
BA_ "GenSigTimeoutTime_CVADAS" SG_ 204 MessageCounter_AXLE_TORQUE_FD_1 0;
BA_ "GenSigTimeoutTime_EVCU2" SG_ 204 MessageCounter_AXLE_TORQUE_FD_1 0;
BA_ "GenSigTimeoutTime_VDCM" SG_ 204 MessageCounter_AXLE_TORQUE_FD_1 0;
BA_ "GenSigTimeoutTime_BSM" SG_ 204 MessageCounter_AXLE_TORQUE_FD_1 0;
BA_ "GenSigStartValue" SG_ 204 Axle_Torque_DrvReqMod 32768;
BA_ "GenSigTimeoutTime_AHCP" SG_ 204 Axle_Torque_DrvReqMod 0;
BA_ "GenSigTimeoutTime_BSM" SG_ 204 Axle_Torque_DrvReqMod 0;
BA_ "GenSigTimeoutTime_BSM2" SG_ 204 Axle_Torque_DrvReqMod 0;
BA_ "GenSigTimeoutTime_CVPAM" SG_ 204 Axle_Torque_DrvReqMod 0;
BA_ "GenSigTimeoutTime_ECM" SG_ 204 Axle_Torque_DrvReqMod 0;
BA_ "GenSigTimeoutTime_EPS" SG_ 204 Axle_Torque_DrvReqMod 0;
BA_ "GenSigTimeoutTime_ORC" SG_ 204 Axle_Torque_DrvReqMod 0;
BA_ "GenSigStartValue" SG_ 204 Axle_TorqueStatic_D_TTC 32767;
BA_ "GenSigTimeoutTime_AHCP" SG_ 204 Axle_TorqueStatic_D_TTC 0;
BA_ "GenSigTimeoutTime_BSM" SG_ 204 Axle_TorqueStatic_D_TTC 0;
BA_ "GenSigTimeoutTime_BSM2" SG_ 204 Axle_TorqueStatic_D_TTC 0;
BA_ "GenSigTimeoutTime_CVPAM" SG_ 204 Axle_TorqueStatic_D_TTC 0;
BA_ "GenSigTimeoutTime_ECM" SG_ 204 Axle_TorqueStatic_D_TTC 0;
BA_ "GenSigTimeoutTime_EPS" SG_ 204 Axle_TorqueStatic_D_TTC 0;
BA_ "GenSigTimeoutTime_ORC" SG_ 204 Axle_TorqueStatic_D_TTC 0;
BA_ "GenSigStartValue" SG_ 204 Total_AxleTorque_Max 32767;
BA_ "GenSigTimeoutTime_AHCP" SG_ 204 Total_AxleTorque_Max 0;
BA_ "GenSigTimeoutTime_BSM" SG_ 204 Total_AxleTorque_Max 0;
BA_ "GenSigTimeoutTime_BSM2" SG_ 204 Total_AxleTorque_Max 0;
BA_ "GenSigTimeoutTime_CVPAM" SG_ 204 Total_AxleTorque_Max 0;
BA_ "GenSigTimeoutTime_ECM" SG_ 204 Total_AxleTorque_Max 0;
BA_ "GenSigTimeoutTime_EPS" SG_ 204 Total_AxleTorque_Max 0;
BA_ "GenSigTimeoutTime_ORC" SG_ 204 Total_AxleTorque_Max 0;
BA_ "GenSigStartValue" SG_ 204 Total_AxleTorque_Min 32767;
BA_ "GenSigTimeoutTime_AHCP" SG_ 204 Total_AxleTorque_Min 0;
BA_ "GenSigTimeoutTime_BSM" SG_ 204 Total_AxleTorque_Min 0;
BA_ "GenSigTimeoutTime_BSM2" SG_ 204 Total_AxleTorque_Min 0;
BA_ "GenSigTimeoutTime_CVPAM" SG_ 204 Total_AxleTorque_Min 0;
BA_ "GenSigTimeoutTime_ECM" SG_ 204 Total_AxleTorque_Min 0;
BA_ "GenSigTimeoutTime_EPS" SG_ 204 Total_AxleTorque_Min 0;
BA_ "GenSigTimeoutTime_ORC" SG_ 204 Total_AxleTorque_Min 0;
BA_ "GenSigTimeoutTime_AHCP" SG_ 204 CRC_AXLE_TORQUE_FD_1 0;
BA_ "GenSigTimeoutTime_BSM2" SG_ 204 CRC_AXLE_TORQUE_FD_1 0;
BA_ "GenSigTimeoutTime_CVPAM" SG_ 204 CRC_AXLE_TORQUE_FD_1 0;
BA_ "GenSigTimeoutTime_ECM" SG_ 204 CRC_AXLE_TORQUE_FD_1 0;
BA_ "GenSigTimeoutTime_EPS" SG_ 204 CRC_AXLE_TORQUE_FD_1 0;
BA_ "GenSigTimeoutTime_ORC" SG_ 204 CRC_AXLE_TORQUE_FD_1 0;
BA_ "GenSigTimeoutTime_AHCP" SG_ 204 MessageCounter_AXLE_TORQUE_FD_1 0;
BA_ "GenSigTimeoutTime_BSM2" SG_ 204 MessageCounter_AXLE_TORQUE_FD_1 0;
BA_ "GenSigTimeoutTime_CVPAM" SG_ 204 MessageCounter_AXLE_TORQUE_FD_1 0;
BA_ "GenSigTimeoutTime_ECM" SG_ 204 MessageCounter_AXLE_TORQUE_FD_1 0;
BA_ "GenSigTimeoutTime_EPS" SG_ 204 MessageCounter_AXLE_TORQUE_FD_1 0;
BA_ "GenSigTimeoutTime_ORC" SG_ 204 MessageCounter_AXLE_TORQUE_FD_1 0;
BA_ "GenSigTimeoutTime_CVADAS" SG_ 262 CRC_ENGINE2 0;
BA_ "GenSigTimeoutTime_EVCU2" SG_ 262 CRC_ENGINE2 0;
BA_ "GenSigTimeoutTime_VDCM" SG_ 262 CRC_ENGINE2 0;
BA_ "GenSigTimeoutTime_BSM" SG_ 262 CRC_ENGINE2 0;
BA_ "GenSigTimeoutTime_EPS" SG_ 262 CRC_ENGINE2 0;
BA_ "GenSigTimeoutTime_CVADAS" SG_ 262 ECM_LHOM_W 0;
BA_ "GenSigTimeoutTime_EVCU2" SG_ 262 ECM_LHOM_W 0;
BA_ "GenSigTimeoutTime_VDCM" SG_ 262 ECM_LHOM_W 0;
BA_ "GenSigTimeoutTime_CVADAS" SG_ 262 EngineSpeed_W 0;
BA_ "GenSigTimeoutTime_EVCU2" SG_ 262 EngineSpeed_W 0;
BA_ "GenSigTimeoutTime_VDCM" SG_ 262 EngineSpeed_W 0;
BA_ "GenSigTimeoutTime_CVADAS" SG_ 262 EngineSts_W 0;
BA_ "GenSigTimeoutTime_EVCU2" SG_ 262 EngineSts_W 0;
BA_ "GenSigTimeoutTime_VDCM" SG_ 262 EngineSts_W 0;
BA_ "GenSigTimeoutTime_BSM" SG_ 262 EngineSts_W 0;
BA_ "GenSigTimeoutTime_CVADAS" SG_ 262 ESS_ENG_ST_W 0;
BA_ "GenSigTimeoutTime_EVCU2" SG_ 262 ESS_ENG_ST_W 0;
BA_ "GenSigTimeoutTime_VDCM" SG_ 262 ESS_ENG_ST_W 0;
BA_ "GenSigTimeoutTime_CVADAS" SG_ 262 GasPedalPosition_W 0;
BA_ "GenSigTimeoutTime_EVCU2" SG_ 262 GasPedalPosition_W 0;
BA_ "GenSigTimeoutTime_VDCM" SG_ 262 GasPedalPosition_W 0;
BA_ "GenSigTimeoutTime_CVADAS" SG_ 262 GasPedalPositionFailSts_W 0;
BA_ "GenSigTimeoutTime_EVCU2" SG_ 262 GasPedalPositionFailSts_W 0;
BA_ "GenSigTimeoutTime_VDCM" SG_ 262 GasPedalPositionFailSts_W 0;
BA_ "GenSigTimeoutTime_ADCAM" SG_ 262 LV12PwrFreeRq_W 0;
BA_ "GenSigTimeoutTime_CVADAS" SG_ 262 LV12PwrFreeRq_W 0;
BA_ "GenSigTimeoutTime_EVCU2" SG_ 262 LV12PwrFreeRq_W 0;
BA_ "GenSigTimeoutTime_VDCM" SG_ 262 LV12PwrFreeRq_W 0;
BA_ "GenSigTimeoutTime_CVADAS" SG_ 262 MessageCounter_ENGINE2 0;
BA_ "GenSigTimeoutTime_EVCU2" SG_ 262 MessageCounter_ENGINE2 0;
BA_ "GenSigTimeoutTime_VDCM" SG_ 262 MessageCounter_ENGINE2 0;
BA_ "GenSigTimeoutTime_BSM" SG_ 262 MessageCounter_ENGINE2 0;
BA_ "GenSigTimeoutTime_EPS" SG_ 262 MessageCounter_ENGINE2 0;
BA_ "GenSigTimeoutTime_CVADAS" SG_ 262 PowertrainPrplsnActv 0;
BA_ "GenSigTimeoutTime_EVCU2" SG_ 262 PowertrainPrplsnActv 0;
BA_ "GenSigTimeoutTime_VDCM" SG_ 262 PowertrainPrplsnActv 0;
BA_ "GenSigTimeoutTime_AHCP" SG_ 262 CRC_ENGINE2 0;
BA_ "GenSigTimeoutTime_BSM2" SG_ 262 CRC_ENGINE2 0;
BA_ "GenSigTimeoutTime_ECM" SG_ 262 CRC_ENGINE2 0;
BA_ "GenSigTimeoutTime_ORC" SG_ 262 CRC_ENGINE2 0;
BA_ "GenSigTimeoutTime_AHCP" SG_ 262 ECM_LHOM_W 0;
BA_ "GenSigTimeoutTime_BSM" SG_ 262 ECM_LHOM_W 0;
BA_ "GenSigTimeoutTime_BSM2" SG_ 262 ECM_LHOM_W 0;
BA_ "GenSigTimeoutTime_CVPAM" SG_ 262 ECM_LHOM_W 0;
BA_ "GenSigTimeoutTime_ECM" SG_ 262 ECM_LHOM_W 0;
BA_ "GenSigTimeoutTime_EPS" SG_ 262 ECM_LHOM_W 0;
BA_ "GenSigTimeoutTime_ORC" SG_ 262 ECM_LHOM_W 0;
BA_ "GenSigTimeoutTime_AHCP" SG_ 262 EngineSpeed_W 0;
BA_ "GenSigTimeoutTime_BSM2" SG_ 262 EngineSpeed_W 0;
BA_ "GenSigTimeoutTime_CVPAM" SG_ 262 EngineSpeed_W 0;
BA_ "GenSigTimeoutTime_ECM" SG_ 262 EngineSpeed_W 0;
BA_ "GenSigTimeoutTime_ORC" SG_ 262 EngineSpeed_W 0;
BA_ "GenSigStartValue" SG_ 262 EngineSts_W 3;
BA_ "GenSigTimeoutTime_AHCP" SG_ 262 EngineSts_W 0;
BA_ "GenSigTimeoutTime_BSM2" SG_ 262 EngineSts_W 0;
BA_ "GenSigTimeoutTime_CVPAM" SG_ 262 EngineSts_W 0;
BA_ "GenSigTimeoutTime_ECM" SG_ 262 EngineSts_W 0;
BA_ "GenSigTimeoutTime_ORC" SG_ 262 EngineSts_W 0;
BA_ "GenSigStartValue" SG_ 262 ESS_ENG_ST_W 15;
BA_ "GenSigSendType" SG_ 262 ESS_ENG_ST_W 3;
BA_ "GenSigTimeoutTime_AHCP" SG_ 262 ESS_ENG_ST_W 0;
BA_ "GenSigTimeoutTime_BSM2" SG_ 262 ESS_ENG_ST_W 0;
BA_ "GenSigTimeoutTime_CVPAM" SG_ 262 ESS_ENG_ST_W 0;
BA_ "GenSigTimeoutTime_ECM" SG_ 262 ESS_ENG_ST_W 0;
BA_ "GenSigTimeoutTime_ORC" SG_ 262 ESS_ENG_ST_W 0;
BA_ "GenSigTimeoutTime_AHCP" SG_ 262 FeedbackASR_ESCReq_W 0;
BA_ "GenSigTimeoutTime_BSM" SG_ 262 FeedbackASR_ESCReq_W 0;
BA_ "GenSigTimeoutTime_BSM2" SG_ 262 FeedbackASR_ESCReq_W 0;
BA_ "GenSigTimeoutTime_CADM" SG_ 262 FeedbackASR_ESCReq_W 0;
BA_ "GenSigTimeoutTime_CVPAM" SG_ 262 FeedbackASR_ESCReq_W 0;
BA_ "GenSigTimeoutTime_ECM" SG_ 262 FeedbackASR_ESCReq_W 0;
BA_ "GenSigTimeoutTime_EPS" SG_ 262 FeedbackASR_ESCReq_W 0;
BA_ "GenSigTimeoutTime_ORC" SG_ 262 FeedbackASR_ESCReq_W 0;
BA_ "GenSigTimeoutTime_AHCP" SG_ 262 GasPedalPosition_W 0;
BA_ "GenSigTimeoutTime_BSM2" SG_ 262 GasPedalPosition_W 0;
BA_ "GenSigTimeoutTime_CADM" SG_ 262 GasPedalPosition_W 0;
BA_ "GenSigTimeoutTime_CVPAM" SG_ 262 GasPedalPosition_W 0;
BA_ "GenSigTimeoutTime_ECM" SG_ 262 GasPedalPosition_W 0;
BA_ "GenSigTimeoutTime_EPS" SG_ 262 GasPedalPosition_W 0;
BA_ "GenSigTimeoutTime_ORC" SG_ 262 GasPedalPosition_W 0;
BA_ "GenSigTimeoutTime_AHCP" SG_ 262 GasPedalPositionFailSts_W 0;
BA_ "GenSigTimeoutTime_BSM2" SG_ 262 GasPedalPositionFailSts_W 0;
BA_ "GenSigTimeoutTime_CVPAM" SG_ 262 GasPedalPositionFailSts_W 0;
BA_ "GenSigTimeoutTime_ECM" SG_ 262 GasPedalPositionFailSts_W 0;
BA_ "GenSigTimeoutTime_EPS" SG_ 262 GasPedalPositionFailSts_W 0;
BA_ "GenSigTimeoutTime_ORC" SG_ 262 GasPedalPositionFailSts_W 0;
BA_ "GenSigTimeoutTime_AHCP" SG_ 262 LV12PwrFreeRq_W 0;
BA_ "GenSigTimeoutTime_BSM" SG_ 262 LV12PwrFreeRq_W 0;
BA_ "GenSigTimeoutTime_BSM2" SG_ 262 LV12PwrFreeRq_W 0;
BA_ "GenSigTimeoutTime_CADM" SG_ 262 LV12PwrFreeRq_W 0;
BA_ "GenSigTimeoutTime_CVPAM" SG_ 262 LV12PwrFreeRq_W 0;
BA_ "GenSigTimeoutTime_ECM" SG_ 262 LV12PwrFreeRq_W 0;
BA_ "GenSigTimeoutTime_EPS" SG_ 262 LV12PwrFreeRq_W 0;
BA_ "GenSigTimeoutTime_ORC" SG_ 262 LV12PwrFreeRq_W 0;
BA_ "GenSigTimeoutTime_AHCP" SG_ 262 MessageCounter_ENGINE2 0;
BA_ "GenSigTimeoutTime_BSM2" SG_ 262 MessageCounter_ENGINE2 0;
BA_ "GenSigTimeoutTime_ECM" SG_ 262 MessageCounter_ENGINE2 0;
BA_ "GenSigTimeoutTime_ORC" SG_ 262 MessageCounter_ENGINE2 0;
BA_ "GenSigTimeoutTime_AHCP" SG_ 262 PowertrainPrplsnActv 0;
BA_ "GenSigTimeoutTime_BSM2" SG_ 262 PowertrainPrplsnActv 0;
BA_ "GenSigTimeoutTime_CVPAM" SG_ 262 PowertrainPrplsnActv 0;
BA_ "GenSigTimeoutTime_ECM" SG_ 262 PowertrainPrplsnActv 0;
BA_ "GenSigTimeoutTime_EPS" SG_ 262 PowertrainPrplsnActv 0;
BA_ "GenSigTimeoutTime_ORC" SG_ 262 PowertrainPrplsnActv 0;
BA_ "GenSigTimeoutTime_ADCAM" SG_ 2654486529 CBV_bit0_RepeatMessageRequestBit_1E384001 0;
BA_ "GenSigTimeoutTime_CVADAS" SG_ 2654486529 CBV_bit0_RepeatMessageRequestBit_1E384001 0;
BA_ "GenSigTimeoutTime_EVCU2" SG_ 2654486529 CBV_bit0_RepeatMessageRequestBit_1E384001 0;
BA_ "GenSigTimeoutTime_VDCM" SG_ 2654486529 CBV_bit0_RepeatMessageRequestBit_1E384001 0;
BA_ "GenSigTimeoutTime_ADCAM" SG_ 2654486529 CBV_bit1_1E384001 0;
BA_ "GenSigTimeoutTime_CVADAS" SG_ 2654486529 CBV_bit1_1E384001 0;
BA_ "GenSigTimeoutTime_EVCU2" SG_ 2654486529 CBV_bit1_1E384001 0;
BA_ "GenSigTimeoutTime_VDCM" SG_ 2654486529 CBV_bit1_1E384001 0;
BA_ "GenSigTimeoutTime_ADCAM" SG_ 2654486529 CBV_bit2_1E384001 0;
BA_ "GenSigTimeoutTime_CVADAS" SG_ 2654486529 CBV_bit2_1E384001 0;
BA_ "GenSigTimeoutTime_EVCU2" SG_ 2654486529 CBV_bit2_1E384001 0;
BA_ "GenSigTimeoutTime_VDCM" SG_ 2654486529 CBV_bit2_1E384001 0;
BA_ "GenSigTimeoutTime_ADCAM" SG_ 2654486529 CBV_bit3_NMCoordinatorBit_1E384001 0;
BA_ "GenSigTimeoutTime_CVADAS" SG_ 2654486529 CBV_bit3_NMCoordinatorBit_1E384001 0;
BA_ "GenSigTimeoutTime_EVCU2" SG_ 2654486529 CBV_bit3_NMCoordinatorBit_1E384001 0;
BA_ "GenSigTimeoutTime_VDCM" SG_ 2654486529 CBV_bit3_NMCoordinatorBit_1E384001 0;
BA_ "GenSigTimeoutTime_ADCAM" SG_ 2654486529 CBV_bit4_ActiveWakeupBit_1E384001 0;
BA_ "GenSigTimeoutTime_CVADAS" SG_ 2654486529 CBV_bit4_ActiveWakeupBit_1E384001 0;
BA_ "GenSigTimeoutTime_EVCU2" SG_ 2654486529 CBV_bit4_ActiveWakeupBit_1E384001 0;
BA_ "GenSigTimeoutTime_VDCM" SG_ 2654486529 CBV_bit4_ActiveWakeupBit_1E384001 0;
BA_ "GenSigTimeoutTime_ADCAM" SG_ 2654486529 CBV_bit5_1E384001 0;
BA_ "GenSigTimeoutTime_CVADAS" SG_ 2654486529 CBV_bit5_1E384001 0;
BA_ "GenSigTimeoutTime_EVCU2" SG_ 2654486529 CBV_bit5_1E384001 0;
BA_ "GenSigTimeoutTime_VDCM" SG_ 2654486529 CBV_bit5_1E384001 0;
BA_ "GenSigTimeoutTime_ADCAM" SG_ 2654486529 CBV_bit6_PartialNtwInfBit_1E384001 0;
BA_ "GenSigTimeoutTime_CVADAS" SG_ 2654486529 CBV_bit6_PartialNtwInfBit_1E384001 0;
BA_ "GenSigTimeoutTime_EVCU2" SG_ 2654486529 CBV_bit6_PartialNtwInfBit_1E384001 0;
BA_ "GenSigTimeoutTime_VDCM" SG_ 2654486529 CBV_bit6_PartialNtwInfBit_1E384001 0;
BA_ "GenSigTimeoutTime_ADCAM" SG_ 2654486529 CBV_bit7_1E384001 0;
BA_ "GenSigTimeoutTime_CVADAS" SG_ 2654486529 CBV_bit7_1E384001 0;
BA_ "GenSigTimeoutTime_EVCU2" SG_ 2654486529 CBV_bit7_1E384001 0;
BA_ "GenSigTimeoutTime_VDCM" SG_ 2654486529 CBV_bit7_1E384001 0;
BA_ "GenSigTimeoutTime_ADCAM" SG_ 2654486529 SourceNodeIdentifier_1E384001 0;
BA_ "GenSigTimeoutTime_CVADAS" SG_ 2654486529 SourceNodeIdentifier_1E384001 0;
BA_ "GenSigTimeoutTime_EVCU2" SG_ 2654486529 SourceNodeIdentifier_1E384001 0;
BA_ "GenSigTimeoutTime_VDCM" SG_ 2654486529 SourceNodeIdentifier_1E384001 0;
BA_ "GenSigTimeoutTime_AHCP" SG_ 2654486529 CBV_bit0_RepeatMessageRequestBit_1E384001 0;
BA_ "GenSigTimeoutTime_BSM" SG_ 2654486529 CBV_bit0_RepeatMessageRequestBit_1E384001 0;
BA_ "GenSigTimeoutTime_BSM2" SG_ 2654486529 CBV_bit0_RepeatMessageRequestBit_1E384001 0;
BA_ "GenSigTimeoutTime_CADM" SG_ 2654486529 CBV_bit0_RepeatMessageRequestBit_1E384001 0;
BA_ "GenSigTimeoutTime_CVPAM" SG_ 2654486529 CBV_bit0_RepeatMessageRequestBit_1E384001 0;
BA_ "GenSigTimeoutTime_ECM" SG_ 2654486529 CBV_bit0_RepeatMessageRequestBit_1E384001 0;
BA_ "GenSigTimeoutTime_EPS" SG_ 2654486529 CBV_bit0_RepeatMessageRequestBit_1E384001 0;
BA_ "GenSigTimeoutTime_ORC" SG_ 2654486529 CBV_bit0_RepeatMessageRequestBit_1E384001 0;
BA_ "GenSigTimeoutTime_AHCP" SG_ 2654486529 CBV_bit1_1E384001 0;
BA_ "GenSigTimeoutTime_BSM" SG_ 2654486529 CBV_bit1_1E384001 0;
BA_ "GenSigTimeoutTime_BSM2" SG_ 2654486529 CBV_bit1_1E384001 0;
BA_ "GenSigTimeoutTime_CADM" SG_ 2654486529 CBV_bit1_1E384001 0;
BA_ "GenSigTimeoutTime_CVPAM" SG_ 2654486529 CBV_bit1_1E384001 0;
BA_ "GenSigTimeoutTime_ECM" SG_ 2654486529 CBV_bit1_1E384001 0;
BA_ "GenSigTimeoutTime_EPS" SG_ 2654486529 CBV_bit1_1E384001 0;
BA_ "GenSigTimeoutTime_ORC" SG_ 2654486529 CBV_bit1_1E384001 0;
BA_ "GenSigTimeoutTime_AHCP" SG_ 2654486529 CBV_bit2_1E384001 0;
BA_ "GenSigTimeoutTime_BSM" SG_ 2654486529 CBV_bit2_1E384001 0;
BA_ "GenSigTimeoutTime_BSM2" SG_ 2654486529 CBV_bit2_1E384001 0;
BA_ "GenSigTimeoutTime_CADM" SG_ 2654486529 CBV_bit2_1E384001 0;
BA_ "GenSigTimeoutTime_CVPAM" SG_ 2654486529 CBV_bit2_1E384001 0;
BA_ "GenSigTimeoutTime_ECM" SG_ 2654486529 CBV_bit2_1E384001 0;
BA_ "GenSigTimeoutTime_EPS" SG_ 2654486529 CBV_bit2_1E384001 0;
BA_ "GenSigTimeoutTime_ORC" SG_ 2654486529 CBV_bit2_1E384001 0;
BA_ "GenSigTimeoutTime_AHCP" SG_ 2654486529 CBV_bit3_NMCoordinatorBit_1E384001 0;
BA_ "GenSigTimeoutTime_BSM" SG_ 2654486529 CBV_bit3_NMCoordinatorBit_1E384001 0;
BA_ "GenSigTimeoutTime_BSM2" SG_ 2654486529 CBV_bit3_NMCoordinatorBit_1E384001 0;
BA_ "GenSigTimeoutTime_CADM" SG_ 2654486529 CBV_bit3_NMCoordinatorBit_1E384001 0;
BA_ "GenSigTimeoutTime_CVPAM" SG_ 2654486529 CBV_bit3_NMCoordinatorBit_1E384001 0;
BA_ "GenSigTimeoutTime_ECM" SG_ 2654486529 CBV_bit3_NMCoordinatorBit_1E384001 0;
BA_ "GenSigTimeoutTime_EPS" SG_ 2654486529 CBV_bit3_NMCoordinatorBit_1E384001 0;
BA_ "GenSigTimeoutTime_ORC" SG_ 2654486529 CBV_bit3_NMCoordinatorBit_1E384001 0;
BA_ "GenSigTimeoutTime_AHCP" SG_ 2654486529 CBV_bit4_ActiveWakeupBit_1E384001 0;
BA_ "GenSigTimeoutTime_BSM" SG_ 2654486529 CBV_bit4_ActiveWakeupBit_1E384001 0;
BA_ "GenSigTimeoutTime_BSM2" SG_ 2654486529 CBV_bit4_ActiveWakeupBit_1E384001 0;
BA_ "GenSigTimeoutTime_CADM" SG_ 2654486529 CBV_bit4_ActiveWakeupBit_1E384001 0;
BA_ "GenSigTimeoutTime_CVPAM" SG_ 2654486529 CBV_bit4_ActiveWakeupBit_1E384001 0;
BA_ "GenSigTimeoutTime_ECM" SG_ 2654486529 CBV_bit4_ActiveWakeupBit_1E384001 0;
BA_ "GenSigTimeoutTime_EPS" SG_ 2654486529 CBV_bit4_ActiveWakeupBit_1E384001 0;
BA_ "GenSigTimeoutTime_ORC" SG_ 2654486529 CBV_bit4_ActiveWakeupBit_1E384001 0;
BA_ "GenSigTimeoutTime_AHCP" SG_ 2654486529 CBV_bit5_1E384001 0;
BA_ "GenSigTimeoutTime_BSM" SG_ 2654486529 CBV_bit5_1E384001 0;
BA_ "GenSigTimeoutTime_BSM2" SG_ 2654486529 CBV_bit5_1E384001 0;
BA_ "GenSigTimeoutTime_CADM" SG_ 2654486529 CBV_bit5_1E384001 0;
BA_ "GenSigTimeoutTime_CVPAM" SG_ 2654486529 CBV_bit5_1E384001 0;
BA_ "GenSigTimeoutTime_ECM" SG_ 2654486529 CBV_bit5_1E384001 0;
BA_ "GenSigTimeoutTime_EPS" SG_ 2654486529 CBV_bit5_1E384001 0;
BA_ "GenSigTimeoutTime_ORC" SG_ 2654486529 CBV_bit5_1E384001 0;
BA_ "GenSigTimeoutTime_AHCP" SG_ 2654486529 CBV_bit6_PartialNtwInfBit_1E384001 0;
BA_ "GenSigTimeoutTime_BSM" SG_ 2654486529 CBV_bit6_PartialNtwInfBit_1E384001 0;
BA_ "GenSigTimeoutTime_BSM2" SG_ 2654486529 CBV_bit6_PartialNtwInfBit_1E384001 0;
BA_ "GenSigTimeoutTime_CADM" SG_ 2654486529 CBV_bit6_PartialNtwInfBit_1E384001 0;
BA_ "GenSigTimeoutTime_CVPAM" SG_ 2654486529 CBV_bit6_PartialNtwInfBit_1E384001 0;
BA_ "GenSigTimeoutTime_ECM" SG_ 2654486529 CBV_bit6_PartialNtwInfBit_1E384001 0;
BA_ "GenSigTimeoutTime_EPS" SG_ 2654486529 CBV_bit6_PartialNtwInfBit_1E384001 0;
BA_ "GenSigTimeoutTime_ORC" SG_ 2654486529 CBV_bit6_PartialNtwInfBit_1E384001 0;
BA_ "GenSigTimeoutTime_AHCP" SG_ 2654486529 CBV_bit7_1E384001 0;
BA_ "GenSigTimeoutTime_BSM" SG_ 2654486529 CBV_bit7_1E384001 0;
BA_ "GenSigTimeoutTime_BSM2" SG_ 2654486529 CBV_bit7_1E384001 0;
BA_ "GenSigTimeoutTime_CADM" SG_ 2654486529 CBV_bit7_1E384001 0;
BA_ "GenSigTimeoutTime_CVPAM" SG_ 2654486529 CBV_bit7_1E384001 0;
BA_ "GenSigTimeoutTime_ECM" SG_ 2654486529 CBV_bit7_1E384001 0;
BA_ "GenSigTimeoutTime_EPS" SG_ 2654486529 CBV_bit7_1E384001 0;
BA_ "GenSigTimeoutTime_ORC" SG_ 2654486529 CBV_bit7_1E384001 0;
BA_ "GenSigTimeoutTime_AHCP" SG_ 2654486529 SourceNodeIdentifier_1E384001 0;
BA_ "GenSigTimeoutTime_BSM" SG_ 2654486529 SourceNodeIdentifier_1E384001 0;
BA_ "GenSigTimeoutTime_BSM2" SG_ 2654486529 SourceNodeIdentifier_1E384001 0;
BA_ "GenSigTimeoutTime_CADM" SG_ 2654486529 SourceNodeIdentifier_1E384001 0;
BA_ "GenSigTimeoutTime_CVPAM" SG_ 2654486529 SourceNodeIdentifier_1E384001 0;
BA_ "GenSigTimeoutTime_ECM" SG_ 2654486529 SourceNodeIdentifier_1E384001 0;
BA_ "GenSigTimeoutTime_EPS" SG_ 2654486529 SourceNodeIdentifier_1E384001 0;
BA_ "GenSigTimeoutTime_ORC" SG_ 2654486529 SourceNodeIdentifier_1E384001 0;
BA_ "GenSigTimeoutTime_AHCP" SG_ 1036 CRC_ENGINE3 0;
BA_ "GenSigTimeoutTime_BSM" SG_ 518 EngTrqEnblRq_DAS_W 0;
BA_ "GenSigTimeoutTime_BSM2" SG_ 518 EngTrqEnblRq_DAS_W 0;
BA_ "GenSigTimeoutTime_CVPAM" SG_ 518 EngTrqEnblRq_DAS_W 0;
BA_ "GenSigTimeoutTime_ECM" SG_ 518 EngTrqEnblRq_DAS_W 0;
BA_ "GenSigTimeoutTime_EPS" SG_ 518 EngTrqEnblRq_DAS_W 0;
BA_ "GenSigTimeoutTime_ORC" SG_ 518 EngTrqEnblRq_DAS_W 0;
BA_ "GenSigTimeoutTime_AHCP" SG_ 518 MessageCounter_ENGINE5 0;
BA_ "GenSigTimeoutTime_CVPAM" SG_ 518 MessageCounter_ENGINE5 0;
BA_ "GenSigTimeoutTime_ECM" SG_ 518 MessageCounter_ENGINE5 0;
BA_ "GenSigTimeoutTime_EPS" SG_ 518 MessageCounter_ENGINE5 0;
BA_ "GenSigTimeoutTime_ORC" SG_ 518 MessageCounter_ENGINE5 0;
BA_ "GenSigStartValue" SG_ 518 PdlPosActual 1;
BA_ "GenSigTimeoutTime_AHCP" SG_ 518 PdlPosActual 0;
BA_ "GenSigTimeoutTime_CVPAM" SG_ 518 PdlPosActual 0;
BA_ "GenSigTimeoutTime_ECM" SG_ 518 PdlPosActual 0;
BA_ "GenSigTimeoutTime_EPS" SG_ 518 PdlPosActual 0;
BA_ "GenSigTimeoutTime_ORC" SG_ 518 PdlPosActual 0;
BA_ "GenSigTimeoutTime_AHCP" SG_ 518 RPMOverRev_W 0;
BA_ "GenSigTimeoutTime_BSM" SG_ 518 RPMOverRev_W 0;
BA_ "GenSigTimeoutTime_BSM2" SG_ 518 RPMOverRev_W 0;
BA_ "GenSigTimeoutTime_CVPAM" SG_ 518 RPMOverRev_W 0;
BA_ "GenSigTimeoutTime_ECM" SG_ 518 RPMOverRev_W 0;
BA_ "GenSigTimeoutTime_EPS" SG_ 518 RPMOverRev_W 0;
BA_ "GenSigTimeoutTime_ORC" SG_ 518 RPMOverRev_W 0;
VAL_ 264 LwsAngle 65535 "SNA";
VAL_ 1036 SpeedLimitSts 0 "Standby" 1 "Activated" 2 "Not_Actuable" 3 "Override" 4 "Overspeed" 5 "Deactivated" 6 "Off" 7 "SNA";
VAL_ 1036 Override 0 "Not_active" 1 "Active";
VAL_ 1155 ACCEngaged 0 "Not_Engaged" 1 "Engaged";
VAL_ 1155 ABSFailSts 0 "Fail_Not_Present" 1 "Fail_Present";
VAL_ 255 SumTorqueStatic 2047 "SNA";
VAL_ 255 SumTorqueSel_D_TTC 2047 "SNA";
VAL_ 255 SumTorqueMin 2047 "SNA";
VAL_ 255 SumTorqueMax 2047 "SNA";
VAL_ 255 SumTorqueExp 2047 "SNA";
VAL_ 255 SumTorque_DrvReqMod 8191 "SNA";
VAL_ 518 RPMOverRev_W 0 "FALSE" 1 "TRUE";
VAL_ 518 PdlPosActual 255 "SNA";
VAL_ 518 EngTrqEnblRq_DAS_W 0 "FALSE" 1 "TRUE";
VAL_ 1036 ISASts 0 "Not_Active" 1 "Active";
VAL_ 1054 ThermalManagementActive_W 0 "Not_active" 1 "Active";
VAL_ 514 BrkPdl_Stat 0 "UPSTOP" 1 "PSD" 2 "NDEF2" 3 "SNA";
VAL_ 514 BrkPdl_Flt 0 "NOT FAULTED" 1 "FAULTED";
VAL_ 514 BrakePdlPosn 255 "SNA";
VAL_ 513 SelectSpdSts 0 "OFF" 1 "Select Speed Mode" 2 "Select Speed Mode Inhibit" 3 "SNA";
VAL_ 280 Object_Dist 255 "SNA";
VAL_ 280 ACC_DsrSpeedKPH 255 "SNA";
VAL_ 262 PowertrainPrplsnActv 0 "Off" 1 "Active";
VAL_ 262 LV12PwrFreeRq_W 0 "Level 1 or 2 Power free Mode NOT active" 1 "Level 1 or 2 Power free Mode Active";
VAL_ 262 GasPedalPositionFailSts_W 0 "Fail_not_present" 1 "Fail_present";
VAL_ 262 GasPedalPosition_W 255 "SNA";
VAL_ 262 FeedbackASR_ESCReq_W 0 "TorqueReq_ASR_ESCValid" 1 "TorqueReq_ASR_ESCNot_Valid";
VAL_ 262 ESS_ENG_ST_W 1 "ENS Stopped / ENS_STOPPED" 2 "ENS Request Start / ENS_RQ_ST" 3 "ENS Running / ENS_RUN" 4 "ENS Stop Pending / ENS_STOP_PEND" 5 "ENS Start protection / ENS_ST_PRTCT" 6 "ENS Start inhibit / ENS_ST_INH" 7 "ENS disabled / ENS_DSBL" 8 "ENS_IHB_LATCH" 9 "ENS Starting / ENS_Starting" 15 "SNA";
VAL_ 262 EngineSts_W 0 "Engine_Off" 1 "Engine_Cranking" 2 "Engine_On" 3 "SNA";
VAL_ 262 EngineSpeed_W 16383 "SNA";
VAL_ 262 ECM_LHOM_W 0 "Not_In_Limp_Home" 1 "In_Limp_Home";
VAL_ 258 TorqueRequest 2047 "SNA";
VAL_ 258 TorqueReduct 0 "Not_Active" 1 "Active";
VAL_ 258 TorqueIncrease 0 "Not_Active" 1 "Active";
VAL_ 258 BrakePedalPressure 2047 "SNA";
VAL_ 258 BrakeBoostPressure 2047 "SNA";
VAL_ 258 ABSActive 0 "Not_active" 1 "Active";
VAL_ 276 PropulsionSystemActive 0 "Not_Active" 1 "Active";
VAL_ 258 Brk_Stat 0 "IDLE" 1 "BRAKING" 2 "NDEF2" 3 "SNA";
VAL_ 280 MRM_STATUS 0 "Not_Active" 1 "MRM_in_Process" 2 "Vehicle_Secure_Request" 3 "Vehicle_Securement_Complete" 4 "Canceled" 7 "SNA";
VAL_ 280 ACC_Systemsts 0 "OFF" 1 "ACC_Enabled" 2 "ACC_Engaged" 3 "ACC_Engaged_BrakeOnly" 4 "ACC_Cancel" 5 "NCC_Enabled" 6 "NCC_Engaged" 7 "NCC_Cancel" 8 "HAS_BSoC" 9 "RRCC_Enabled_No_Set_Speed" 10 "RRCC_Enabled_With_Set_Speed" 11 "RRCC_Engaged" 12 "L3_Engaged" 13 "L3_Disengaged" 15 "SNA";
VAL_ 280 ACC_StopStart 0 "DEFAULT" 1 "AutoStop_Allowed" 2 "AutoStart_Allowed" 3 "SNA";
VAL_ 1456 Set_Speed_MPH 255 "SNA";
VAL_ 1456 Set_Speed_KPH 255 "SNA";
VAL_ 258 ACC_Wheel_Torque_Enabled_BSM 0 "Not Enabled" 1 "Enabled";
VAL_ 258 ACC_Wheel_Torque_BSM 65535 "SNA";
VAL_ 2654486529 CBV_bit0_RepeatMessageRequestBit_1E384001 0 "Repeat_Message_State_not_requested" 1 "Repeat_Message_State_requested";
VAL_ 2654486529 CBV_bit3_NMCoordinatorBit_1E384001 0 "Start_of_synchronized_shutdown_is_not_requested_by_main_coordinator" 1 "Start_of_synchronized_shutdown_is_requested_by_main_coordinator";
VAL_ 2654486529 CBV_bit4_ActiveWakeupBit_1E384001 0 "PassiveWakeup" 1 "ActiveWakeup";
VAL_ 2654486529 CBV_bit6_PartialNtwInfBit_1E384001 0 "NM_PDU_contains_no_Partial_Network_request_information" 1 "NM_PDU_contains_Partial_Network_request_information";
VAL_ 2654486669 CBV_bit3_NMCoordinatorBit_1E38408D 0 "Start_of_synchronized_shutdown_is_not_requested_by_main_coordinator" 1 "Start_of_synchronized_shutdown_is_requested_by_main_coordinator";
VAL_ 2654486669 CBV_bit4_ActiveWakeupBit_1E38408D 0 "PassiveWakeup" 1 "ActiveWakeup";
VAL_ 2654486669 CBV_bit6_PartialNtwInfBit_1E38408D 0 "NM_PDU_contains_no_Partial_Network_request_information" 1 "NM_PDU_contains_Partial_Network_request_information";
VAL_ 2654486669 CBV_bit0_RepeatMessageRequestBit_1E38408D 0 "Repeat_Message_State_not_requested" 1 "Repeat_Message_State_requested";
VAL_ 2654486534 CBV_bit0_RepeatMessageRequestBit_1E384006 0 "Repeat_Message_State_not_requested" 1 "Repeat_Message_State_requested";
VAL_ 2654486534 CBV_bit3_NMCoordinatorBit_1E384006 0 "Start_of_synchronized_shutdown_is_not_requested_by_main_coordinator" 1 "Start_of_synchronized_shutdown_is_requested_by_main_coordinator";
VAL_ 2654486534 CBV_bit4_ActiveWakeupBit_1E384006 0 "PassiveWakeup" 1 "ActiveWakeup";
VAL_ 2654486534 CBV_bit6_PartialNtwInfBit_1E384006 0 "NM_PDU_contains_no_Partial_Network_request_information" 1 "NM_PDU_contains_Partial_Network_request_information";
VAL_ 2654486614 CBV_bit0_RepeatMessageRequestBit_1E384056 0 "Repeat Message State not requested" 1 "Repeat Message State requested";
VAL_ 2654486614 CBV_bit3_NMCoordinatorBit_1E384056 0 "Start of synchronized shutdown is not requested by main coordinator" 1 "Start of synchronized shutdown is requested by main coordinator";
VAL_ 2654486614 CBV_bit4_ActiveWakeupBit_1E384056 0 "PassiveWakeup" 1 "ActiveWakeup";
VAL_ 2654486614 CBV_bit6_PartialNtwInfBit_1E384056 0 "NM PDU contains no Partial Network request information" 1 "NM PDU contains Partial Network request information";
VAL_ 205 TotalAxle_Min_Rq_BSM 0 "Not_Active" 1 "Active";
VAL_ 205 TotalAxle_Max_Rq_BSM 0 "Not_Active" 1 "Active";
VAL_ 205 DriverReq_AxleTrq_Enabled_BSM 0 "No_Req" 1 "ACC_NCC" 2 "SSC" 3 "PPPA" 4 "RRCC" 15 "SNA";
VAL_ 204 Rear_Axle_Regen_Capacity 16383 "SNA";
VAL_ 204 Rear_Axle_Est_Regen_Torq 16383 "SNA";
VAL_ 204 Front_Axle_Regen_Capacity 16383 "SNA";
VAL_ 204 Front_Axle_Est_Regen_Torq 16383 "SNA";
VAL_ 255 SSC_TrqEnblRq_Allowed 0 "FALSE" 1 "TRUE";
VAL_ 255 ESC_TrqEnblRq_Allowed 0 "FALSE" 1 "TRUE";
VAL_ 255 Accel_Pedal_Override 0 "FALSE" 1 "TRUE";
VAL_ 255 ACC_NCC_TrqEnblRq_Allowed 0 "FALSE" 1 "TRUE";
VAL_ 255 Total_AxleTorque_Static 65535 "SNA";
VAL_ 205 TotalAxle_Rq_BSM 65535 "SNA";
VAL_ 205 DriverRequested_AxleTrq_BSM 65535 "SNA";
VAL_ 204 Total_AxleTorque_Min 65535 "SNA";
VAL_ 204 Total_AxleTorque_Max 65535 "SNA";
VAL_ 204 Axle_TorqueStatic_D_TTC 65535 "SNA";
VAL_ 204 Axle_Torque_DrvReqMod 65535 "SNA";
VAL_ 255 Rear_AxleTorque_Static 65535 "SNA";
VAL_ 255 Front_AxleTorque_Static 65535 "SNA";
VAL_ 204 Rear_AxleTorque_Min 65535 "SNA";
VAL_ 204 Rear_AxleTorque_Max 65535 "SNA";
VAL_ 204 Front_AxleTorque_Min 65535 "SNA";
VAL_ 204 Front_AxleTorque_Max 65535 "SNA";
VAL_ 2654486592 CBV_bit4_ActiveWakeupBit_1E384040 0 "PassiveWakeup" 1 "ActiveWakeup";
VAL_ 2654486689 CBV_bit0_RepeatMessageRequestBit_1E3840A1 0 "Repeat_Msg_State_not_requested" 1 "Repeat_Msg_State_requested";
VAL_ 2654486689 CBV_bit3_NMCoordinatorBit_1E3840A1 0 "Synch_shutdown_not_requested" 1 "Synch_shutdown_requested";
VAL_ 2654486689 CBV_bit4_ActiveWakeupBit_1E3840A1 0 "PassiveWakeup" 1 "ActiveWakeup";
VAL_ 2654486689 CBV_bit6_PartialNtwInfBit_1E3840A1 0 "Partial_Network_info_contained" 1 "No_Partial_Network_info_contained";
VAL_ 2654486552 CBV_bit0_RepeatMessageRequestBit_1E384018 0 "Repeat_Message_State_not_requested" 1 "Repeat_Message_State_requested";
VAL_ 2654486552 CBV_bit3_NMCoordinatorBit_1E384018 0 "Start_of_synchronized_shutdown_is_not_requested_by_main_coordinator" 1 "Start_of_synchronized_shutdown_is_requested_by_main_coordinator";
VAL_ 2654486552 CBV_bit4_ActiveWakeupBit_1E384018 0 "PassiveWakeup" 1 "ActiveWakeup";
VAL_ 2654486552 CBV_bit6_PartialNtwInfBit_1E384018 0 "NM_PDU_contains_no_Partial_Network_request_information" 1 "NM_PDU_contains_Partial_Network_request_information";
VAL_ 2654486554 CBV_bit0_RepeatMessageRequestBit_1E38401A 0 "Repeat Message State not requested" 1 "Repeat Message State requested";
VAL_ 2654486554 CBV_bit3_NMCoordinatorBit_1E38401A 0 "Start of synchronized shutdown is not requested by main coordinator" 1 "Start of synchronized shutdown is requested by main coordinator";
VAL_ 2654486554 CBV_bit4_ActiveWakeupBit_1E38401A 0 "PassiveWakeup" 1 "ActiveWakeup";
VAL_ 2654486554 CBV_bit6_PartialNtwInfBit_1E38401A 0 "NM PDU contains no Partial Network request information" 1 "NM PDU contains Partial Network request information";
VAL_ 2654486530 CBV_bit0_RepeatMessageRequestBit_1E384002 0 "Repeat_Message_State_not_requested" 1 "Repeat_Message_State_requested";
VAL_ 2654486530 CBV_bit3_NMCoordinatorBit_1E384002 0 "Start_of_synchronized_shutdown_is_not_requested_by_main_coordinator" 1 "Start_of_synchronized_shutdown_is_requested_by_main_coordinator";
VAL_ 2654486530 CBV_bit4_ActiveWakeupBit_1E384002 0 "PassiveWakeup" 1 "ActiveWakeup";
VAL_ 2654486530 CBV_bit6_PartialNtwInfBit_1E384002 0 "NM_PDU_contains_no_Partial_Network_request_information" 1 "NM_PDU_contains_Partial_Network_request_information";
VAL_ 2654486676 CBV_bit0_RepeatMessageRequestBit_1E384094 0 "Repeat_Message_State_not_requested" 1 "Repeat_Message_State_requested";
VAL_ 2654486676 CBV_bit3_NMCoordinatorBit_1E384094 0 "Start_of_synchronized_shutdown_is_not_requested_by_main_coordinator" 1 "Start_of_synchronized_shutdown_is_requested_by_main_coordinator";
VAL_ 2654486676 CBV_bit4_ActiveWakeupBit_1E384094 0 "PassiveWakeup" 1 "ActiveWakeup";
VAL_ 2654486676 CBV_bit6_PartialNtwInfBit_1E384094 0 "NM_PDU_contains_no_Partial_Network_request_information" 1 "NM_PDU_contains_Partial_Network_request_information";

SIG_GROUP_ 264 EPS_FD_1_Pkt 1 : LwsAngle;
SIG_GROUP_ 518 ENGINE_FD_5_Pkt 1 : RPMOverRev_W PdlPosActual MessageCounter_ENGINE5 EngTrqEnblRq_DAS_W CRC_ENGINE5;
SIG_GROUP_ 514 BRAKE_FD_7_Pkt 1 : MessageCounter_BRAKE7 CRC_BRAKE7 BrkPdl_Stat BrkPdl_Flt BrakePdlPosn;
SIG_GROUP_ 1155 BRAKE_FD_5_Pkt 1 : ACCEngaged ABSFailSts MessageCounter_BRAKE5 CRC_BRAKE5;
SIG_GROUP_ 513 BRAKE_FD_1_Pkt 1 : SelectSpdSts MessageCounter_BRAKE1 CRC_BRAKE1;
SIG_GROUP_ 255 PT_TORQUE_FD_1_Pkt 1 : SumTorqueStatic SumTorqueSel_D_TTC SumTorqueMin SumTorqueMax SumTorqueExp SumTorque_DrvReqMod MessageCounter_PT_TORQUE_FD_1 CRC_PT_TORQUE_FD_1 SSC_TrqEnblRq_Allowed ESC_TrqEnblRq_Allowed Accel_Pedal_Override ACC_NCC_TrqEnblRq_Allowed Total_AxleTorque_Static Rear_AxleTorque_Static Front_AxleTorque_Static;
SIG_GROUP_ 276 HYBRID_POWERTRAIN1_Pkt 1 : PropulsionSystemActive;
SIG_GROUP_ 262 ENGINE_FD_2_Pkt 1 : PowertrainPrplsnActv MessageCounter_ENGINE2 LV12PwrFreeRq_W GasPedalPositionFailSts_W GasPedalPosition_W FeedbackASR_ESCReq_W ESS_ENG_ST_W EngineSts_W EngineSpeed_W ECM_LHOM_W CRC_ENGINE2;
SIG_GROUP_ 258 BRAKE_FD_2_Pkt 1 : TorqueRequest TorqueReduct TorqueIncrease MessageCounter_BRAKE2 CRC_BRAKE2 BrakePedalPressure BrakeBoostPressure ABSActive Brk_Stat ACC_Wheel_Torque_Enabled_BSM ACC_Wheel_Torque_BSM;
SIG_GROUP_ 280 ADAS_FD_INFO_Pkt 1 : Object_Dist MessageCounter_ADAS_FD_INFO CRC_ADAS_FD_INFO ACC_DsrSpeedKPH MRM_STATUS ACC_Systemsts ACC_StopStart;
SIG_GROUP_ 205 BRAKE_FD_6_Pkt 1 : CRC_BRAKE_FD_6 MessageCounter_BRAKE_FD_6 TotalAxle_Min_Rq_BSM TotalAxle_Max_Rq_BSM DriverReq_AxleTrq_Enabled_BSM TotalAxle_Rq_BSM DriverRequested_AxleTrq_BSM;
SIG_GROUP_ 204 AXLE_TORQUE_FD_1_Pkt 1 : MessageCounter_AXLE_TORQUE_FD_1 CRC_AXLE_TORQUE_FD_1 Rear_Axle_Regen_Capacity Rear_Axle_Est_Regen_Torq Front_Axle_Regen_Capacity Front_Axle_Est_Regen_Torq Total_AxleTorque_Min Total_AxleTorque_Max Axle_TorqueStatic_D_TTC Axle_Torque_DrvReqMod Rear_AxleTorque_Min Rear_AxleTorque_Max Front_AxleTorque_Min Front_AxleTorque_Max;
